VERSION ""

NS_ :

BS_:

BU_: VCU_LE CHUD_LE VKM_LE RCRM_LE VPM_LE EDI_LE V2V_LE TCP_LE CSM_LE UHP_Low_LE TouchPad_LE RSE_LE RSC_LE RSA_LE PDIM_LE OTIM_LE ICS_LE LVMPC_LE LVMNav_LE DVB_T_LE ONSTAR_LE HUD_LE IPC_LE RadioHead_LE CHM_LE Dummy_LE CGM_LE AMP_LE

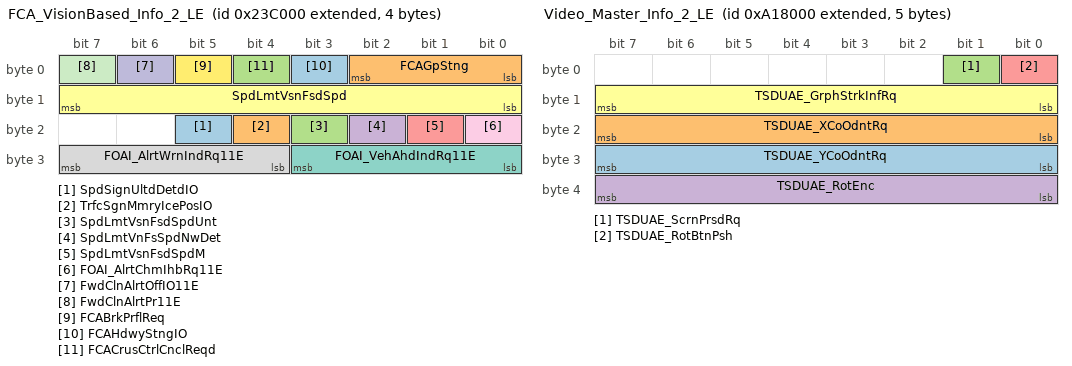
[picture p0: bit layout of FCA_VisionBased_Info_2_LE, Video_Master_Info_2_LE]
BO_ 2149826560 FCA_VisionBased_Info_2_LE: 4 CGM_LE
 SG_ SpdSignUltdDetdIO : 21|1@0+ (1,0) [0|1] ""  VCU_LE,IPC_LE
 SG_ TrfcSgnMmryIcePosIO : 20|1@0+ (1,0) [0|1] ""  VCU_LE,IPC_LE
 SG_ SpdLmtVsnFsdSpdUnt : 19|1@0+ (1,0) [0|1] ""  VCU_LE,IPC_LE,Dummy_LE
 SG_ SpdLmtVnFsSpdNwDet : 18|1@0+ (1,0) [0|1] ""  Dummy_LE
 SG_ SpdLmtVsnFsdSpdM : 17|1@0+ (1,0) [0|1] ""  VCU_LE,IPC_LE
 SG_ SpdLmtVsnFsdSpd : 15|8@0+ (1,0) [0|255] ""  CSM_LE,RadioHead_LE,VCU_LE,IPC_LE
 SG_ FOAI_VehAhdIndRq11E : 27|4@0+ (1,0) [0|15] ""  VCU_LE,IPC_LE,CHUD_LE,HUD_LE
 SG_ FOAI_AlrtWrnIndRq11E : 31|4@0+ (1,0) [0|15] ""  VCU_LE,IPC_LE,CHUD_LE,HUD_LE
 SG_ FOAI_AlrtChmIhbRq11E : 16|1@0+ (1,0) [0|1] ""  VCU_LE,IPC_LE,CHUD_LE,HUD_LE
 SG_ FwdClnAlrtOffIO11E : 6|1@0+ (1,0) [0|1] ""  VCU_LE,IPC_LE
 SG_ FwdClnAlrtPr11E : 7|1@0+ (1,0) [0|1] ""  VCU_LE,IPC_LE,CHUD_LE,HUD_LE
 SG_ FCABrkPrflReq : 5|1@0+ (1,0) [0|1] ""  Dummy_LE
 SG_ FCAHdwyStngIO : 3|1@0+ (1,0) [0|1] ""  VCU_LE,IPC_LE
 SG_ FCAGpStng : 2|3@0+ (1,0) [0|7] ""  VCU_LE,IPC_LE
 SG_ FCACrusCtrlCnclReqd : 4|1@0+ (1,0) [0|1] ""  Dummy_LE

BO_ 2149711872 ACC_YawRate_Information_LE: 8 CGM_LE
 SG_ SetSpdLmtRchd : 54|2@0+ (1,0) [0|3] ""  VCU_LE,IPC_LE
 SG_ FOAI_VehAhdIndRq : 63|4@0+ (1,0) [0|15] ""  CSM_LE,RadioHead_LE,VCU_LE,IPC_LE,CHUD_LE,HUD_LE
 SG_ FOAI_AlrtWrnIndRq : 59|4@0+ (1,0) [0|15] ""  CSM_LE,RadioHead_LE,VCU_LE,IPC_LE,CHUD_LE,HUD_LE
 SG_ FOAI_AlrtChmIhbRq : 48|1@0+ (1,0) [0|1] ""  CSM_LE,RadioHead_LE,VCU_LE,IPC_LE,CHUD_LE,HUD_LE
 SG_ FwdClnAlrtOffIO : 39|1@0+ (1,0) [0|1] ""  CSM_LE,RadioHead_LE,VCU_LE,IPC_LE
 SG_ FwdClnAlrtPr : 23|1@0+ (1,0) [0|1] ""  V2V_LE,CSM_LE,RadioHead_LE,VCU_LE,IPC_LE,CHUD_LE,HUD_LE
 SG_ VehDynYawRateV : 36|1@0+ (1,0) [0|1] ""  VPM_LE,CSM_LE,RadioHead_LE,VCU_LE,IPC_LE
 SG_ ACCHdwyStg : 22|3@0+ (1,0) [0|7] ""  CSM_LE,RadioHead_LE,VCU_LE,IPC_LE,CHUD_LE,HUD_LE
 SG_ ACCDrvrSeltdSpd : 3|12@0+ (0.0625,0) [0|255.9375] "km / h"  CSM_LE,RadioHead_LE,VCU_LE,IPC_LE,CHUD_LE,HUD_LE
 SG_ AdapCrsCntVDA : 4|1@0+ (1,0) [0|1] ""  V2V_LE,CSM_LE,RadioHead_LE,VCU_LE,IPC_LE,CHUD_LE,HUD_LE
 SG_ SpdLmtrSpdWrngEnbld : 37|1@0+ (1,0) [0|1] ""  CSM_LE,RadioHead_LE,VCU_LE,IPC_LE
 SG_ VehDynYawRate : 35|12@0- (0.0625,0) [-128|127.9375] "deg/sec"  VPM_LE,CSM_LE,RadioHead_LE,VCU_LE,IPC_LE
 SG_ CrsCntlDrSelSpdAct : 7|1@0+ (1,0) [0|1] ""  CSM_LE,RadioHead_LE,VCU_LE,IPC_LE
 SG_ ACCAct370 : 6|1@0+ (1,0) [0|1] ""  V2V_LE,CSM_LE,RadioHead_LE,VCU_LE,IPC_LE,CHUD_LE,HUD_LE
 SG_ SpdLmtrSpdWrngAct : 38|1@0+ (1,0) [0|1] ""  CSM_LE,RadioHead_LE,VCU_LE,IPC_LE
 SG_ CrsSpdLmtrDrvSelSpd : 19|12@0+ (0.0625,0) [0|255.9375] "km / h"  CSM_LE,RadioHead_LE,VCU_LE,IPC_LE,Dummy_LE
 SG_ AutoMdSpdLmtStat : 50|2@0+ (1,0) [0|3] ""  CSM_LE,VCU_LE,IPC_LE
 SG_ ACCAutoSetSpdStat : 52|2@0+ (1,0) [0|3] ""  CSM_LE,ONSTAR_LE,VCU_LE,IPC_LE

BO_ 2149629952 Lighting_Status_LE: 5 CGM_LE
 SG_ RtTrnLmpOn : 34|1@0+ (1,0) [0|1] ""  VPM_LE,Dummy_LE
 SG_ LftTrnLmpOn : 35|1@0+ (1,0) [0|1] ""  VPM_LE,Dummy_LE
 SG_ FrFogLmpsAct : 7|1@0+ (1,0) [0|1] ""  CSM_LE,VCU_LE,RadioHead_LE
 SG_ HiBmReqd : 20|1@0+ (1,0) [0|1] ""  V2V_LE,CSM_LE,VCU_LE,RadioHead_LE
 SG_ PrkLtRightOn : 22|1@0+ (1,0) [0|1] ""  CSM_LE,V2V_LE,VCU_LE,RadioHead_LE
 SG_ PrkLtLeftOn : 8|1@0+ (1,0) [0|1] ""  CSM_LE,V2V_LE,VCU_LE,RadioHead_LE
 SG_ TrnSwAct : 6|2@0+ (1,0) [0|3] ""  VPM_LE,CSM_LE,RadioHead_LE,VCU_LE,IPC_LE,CHUD_LE,HUD_LE
 SG_ PrkLtRightIO : 4|1@0+ (1,0) [0|1] ""  CSM_LE,IPC_LE,VCU_LE,RadioHead_LE,CHUD_LE,HUD_LE
 SG_ MainLghtSw : 31|2@0+ (1,0) [0|3] "N/A"  CSM_LE,VCU_LE,RadioHead_LE
 SG_ PrkLtLeftIO : 3|1@0+ (1,0) [0|1] ""  CSM_LE,IPC_LE,VCU_LE,RadioHead_LE,CHUD_LE,HUD_LE
 SG_ HazSwAtv : 2|1@0+ (1,0) [0|1] ""  V2V_LE,IPC_LE,CSM_LE,VCU_LE,RadioHead_LE,CHUD_LE,HUD_LE
 SG_ HiBmIO : 13|1@0+ (1,0) [0|1] ""  CSM_LE,RadioHead_LE,VCU_LE,IPC_LE
 SG_ FrFgLtIO : 9|1@0+ (1,0) [0|1] ""  V2V_LE,CSM_LE,RadioHead_LE,VCU_LE,IPC_LE
 SG_ AutoLtsInactIO : 10|1@0+ (1,0) [0|1] ""  CSM_LE,RadioHead_LE,VCU_LE,IPC_LE
 SG_ AutoLtsActIO : 11|1@0+ (1,0) [0|1] ""  CSM_LE,RadioHead_LE,VCU_LE,IPC_LE
 SG_ LftTrnLmpAtv : 29|2@0+ (1,0) [0|3] ""  VPM_LE,V2V_LE,CSM_LE,RadioHead_LE,VCU_LE,IPC_LE,CHUD_LE,HUD_LE
 SG_ RtTrnLmpAtv : 25|2@0+ (1,0) [0|3] ""  VPM_LE,V2V_LE,CSM_LE,RadioHead_LE,VCU_LE,IPC_LE,CHUD_LE,HUD_LE
 SG_ RevLmpAtv : 17|1@0+ (1,0) [0|1] "N/A"  V2V_LE,CSM_LE,VCU_LE,RadioHead_LE
 SG_ HdlmpBmSelectStat : 33|2@0+ (1,0) [0|3] ""  V2V_LE,CSM_LE,VCU_LE,RadioHead_LE
 SG_ SrvlnceMdAct : 23|1@0+ (1,0) [0|1] ""  CSM_LE,VCU_LE,RadioHead_LE
 SG_ RrFgLtIO : 12|1@0+ (1,0) [0|1] ""  CSM_LE,RadioHead_LE,VCU_LE,IPC_LE
 SG_ PrkLtIO : 14|1@0+ (1,0) [0|1] ""  CSM_LE,VPM_LE,RadioHead_LE,VCU_LE,IPC_LE
 SG_ OtsdAmbtLtLvlStatV : 0|1@0+ (1,0) [0|1] ""  CSM_LE,VPM_LE,VCU_LE,RadioHead_LE
 SG_ OtsdAmbtLtLvlStat : 27|2@0+ (1,0) [0|3] ""  CSM_LE,VPM_LE,VCU_LE,RadioHead_LE
 SG_ RrFogLmpsAct : 19|1@0+ (1,0) [0|1] ""  CSM_LE,VCU_LE,RadioHead_LE
 SG_ PrkngLtsAct : 18|1@0+ (1,0) [0|1] ""  V2V_LE,VPM_LE,CSM_LE,VCU_LE,RadioHead_LE
 SG_ BrkLtsAtv : 15|1@0+ (1,0) [0|1] ""  CSM_LE,VCU_LE,RadioHead_LE
 SG_ AutoBmSlctAllwd : 21|1@0+ (1,0) [0|1] ""  CSM_LE,VCU_LE,RadioHead_LE
 SG_ FlToPsSwAtv : 16|1@0+ (1,0) [0|1] ""  CSM_LE,VCU_LE,RadioHead_LE
 SG_ DRLAct : 1|1@0+ (1,0) [0|1] ""  CSM_LE,V2V_LE,RadioHead_LE,VCU_LE,IPC_LE

BO_ 2151047168 HUD_Status_LE: 1 HUD_LE
 SG_ HdUpDspAnmtStat : 3|3@0+ (1,0) [0|7] ""  CGM_LE,RadioHead_LE,VCU_LE,IPC_LE
 SG_ HUDActv : 0|1@0+ (1,0) [0|1] ""  CSM_LE,CGM_LE,VCU_LE,RadioHead_LE

BO_ 1618 USDT_Resp_From_DVBT_LE: 8 DVB_T_LE
 SG_ DgnInf : 7|64@0+ (1,0) [0|1.84467440737096E+019] ""  CSM_LE,CGM_LE,TCP_LE,ONSTAR_LE

BO_ 1586 VNMF_LE_632_DVB_T: 8 DVB_T_LE
 SG_ VectraSpcNWMgtD : 7|64@0+ (1,0) [0|1.84467440737096E+019] ""  RCRM_LE,V2V_LE,TCP_LE,UHP_Low_LE,LVMNav_LE,ONSTAR_LE,VKM_LE,RSC_LE,RSE_LE,RSA_LE,PDIM_LE,OTIM_LE,CHUD_LE,LVMPC_LE,IPC_LE,ICS_LE,VPM_LE,HUD_LE,VCU_LE,CSM_LE,RadioHead_LE,CHM_LE,AMP_LE,CGM_LE

BO_ 1362 UUDT_Resp_From_DVBT_LE: 8 DVB_T_LE
 SG_ DgnInf_LS552 : 7|64@0+ (1,0) [0|1.84467440737096E+019] ""  CSM_LE,CGM_LE,TCP_LE,ONSTAR_LE

BO_ 2153947136 Remote_Reflash_Stat_LE: 1 CGM_LE
 SG_ RmtRflshMdAct : 7|1@0+ (1,0) [0|1] ""  VCU_LE,CSM_LE,RadioHead_LE

BO_ 2158067712 Video_Master_Info_2_LE: 5 RadioHead_LE
 SG_ TSDUAE_YCoOdntRq : 31|8@0+ (1,0) [0|255] ""  EDI_LE,DVB_T_LE,CGM_LE
 SG_ TSDUAE_XCoOdntRq : 23|8@0+ (1,0) [0|255] ""  EDI_LE,DVB_T_LE,CGM_LE
 SG_ TSDUAE_ScrnPrsdRq : 1|1@0+ (1,0) [0|1] ""  EDI_LE,DVB_T_LE,CGM_LE
 SG_ TSDUAE_RotEnc : 39|8@0- (1,0) [-128|127] "Detentions"  EDI_LE,DVB_T_LE,CGM_LE
 SG_ TSDUAE_RotBtnPsh : 0|1@0+ (1,0) [0|1] ""  EDI_LE,DVB_T_LE,CGM_LE
 SG_ TSDUAE_GrphStrkInfRq : 15|8@0+ (1,0) [0|255] ""  EDI_LE,DVB_T_LE,CGM_LE

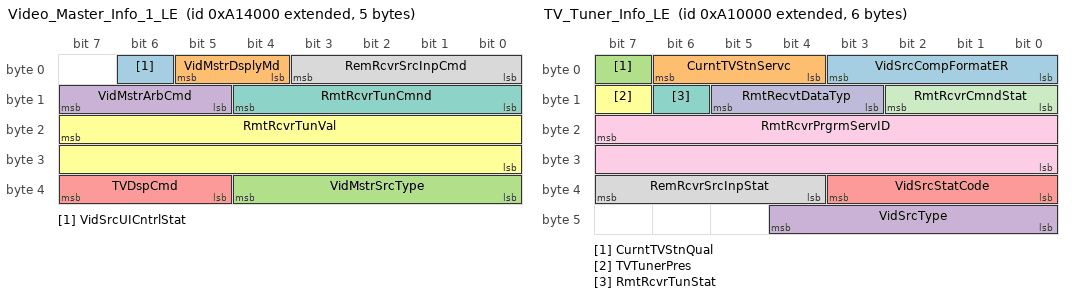
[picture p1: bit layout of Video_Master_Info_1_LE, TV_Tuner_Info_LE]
BO_ 2158051328 Video_Master_Info_1_LE: 5 RadioHead_LE
 SG_ VidSrcUICntrlStat : 6|1@0+ (1,0) [0|1] ""  EDI_LE,Dummy_LE,CGM_LE
 SG_ VidMstrDsplyMd : 5|2@0+ (1,0) [0|3] ""  EDI_LE,CGM_LE,Dummy_LE
 SG_ VidMstrSrcType : 36|5@0+ (1,0) [0|31] ""  EDI_LE,CGM_LE,DVB_T_LE
 SG_ VidMstrArbCmd : 15|3@0+ (1,0) [0|7] ""  CGM_LE,DVB_T_LE
 SG_ TVDspCmd : 39|3@0+ (1,0) [0|7] ""  CGM_LE,DVB_T_LE
 SG_ RmtRcvrTunVal : 23|16@0- (1,0) [-32768|32767] ""  CGM_LE,DVB_T_LE
 SG_ RmtRcvrTunCmnd : 12|5@0+ (1,0) [0|31] ""  CGM_LE,DVB_T_LE
 SG_ RemRcvrSrcInpCmd : 3|4@0+ (1,0) [0|15] ""  CGM_LE,DVB_T_LE

BO_ 2158034944 TV_Tuner_Info_LE: 6 DVB_T_LE
 SG_ VidSrcCompFormatER : 3|4@0+ (1,0) [0|15] ""  VCU_LE,RadioHead_LE
 SG_ CurntTVStnServc : 6|3@0+ (1,0) [0|7] ""  VCU_LE,RadioHead_LE
 SG_ CurntTVStnQual : 7|1@0+ (1,0) [0|1] ""  VCU_LE,RadioHead_LE
 SG_ VidSrcType : 44|5@0+ (1,0) [0|31] ""  VCU_LE,RadioHead_LE
 SG_ VidSrcStatCode : 35|4@0+ (1,0) [0|15] ""  VCU_LE,RadioHead_LE
 SG_ TVTunerPres : 15|1@0+ (1,0) [0|1] ""  VCU_LE,RadioHead_LE
 SG_ RmtRcvrTunStat : 14|1@0+ (1,0) [0|1] ""  VCU_LE,RadioHead_LE
 SG_ RemRcvrSrcInpStat : 39|4@0+ (1,0) [0|15] ""  VCU_LE,RadioHead_LE
 SG_ RmtRcvrPrgrmServID : 23|16@0+ (1,0) [0|65535] ""  VCU_LE,RadioHead_LE
 SG_ RmtRecvtDataTyp : 13|3@0+ (1,0) [0|7] ""  VCU_LE,RadioHead_LE
 SG_ RmtRcvrCmndStat : 10|3@0+ (1,0) [0|7] ""  VCU_LE,RadioHead_LE

BO_ 2158018560 TV_Station_Name_LE: 8 DVB_T_LE
 SG_ TVStatNmeChar1_8 : 7|64@0+ (1,0) [0|0] ""  VCU_LE,RadioHead_LE

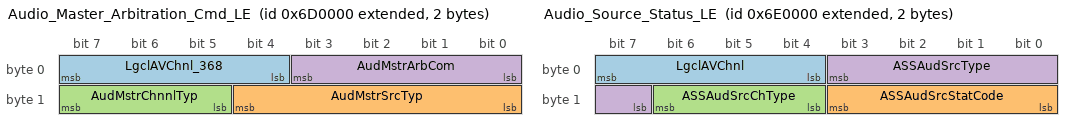
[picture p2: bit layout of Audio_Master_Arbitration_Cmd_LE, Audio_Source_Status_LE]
BO_ 2154627072 Audio_Master_Arbitration_Cmd_LE: 2 RadioHead_LE
 SG_ LgclAVChnl_368 : 7|4@0+ (1,0) [0|15] ""  TCP_LE,UHP_Low_LE,DVB_T_LE,ONSTAR_LE
 SG_ AudMstrSrcTyp : 12|5@0+ (1,0) [0|31] ""  LVMNav_LE,TCP_LE,UHP_Low_LE,DVB_T_LE,ONSTAR_LE
 SG_ AudMstrChnnlTyp : 15|3@0+ (1,0) [0|7] ""  LVMNav_LE,TCP_LE,UHP_Low_LE,DVB_T_LE,ONSTAR_LE
 SG_ AudMstrArbCom : 3|4@0+ (1,0) [0|15] ""  LVMNav_LE,TCP_LE,UHP_Low_LE,DVB_T_LE,ONSTAR_LE

BO_ 2154692608 Audio_Source_Status_LE: 2 ONSTAR_LE
 SG_ LgclAVChnl : 7|4@0+ (1,0) [0|15] ""  V2V_LE,CSM_LE,CGM_LE,LVMNav_LE,VCU_LE,RadioHead_LE
 SG_ ASSAudSrcStatCode : 11|4@0+ (1,0) [0|15] ""  CSM_LE,CGM_LE,OTIM_LE,VCU_LE,RadioHead_LE
 SG_ ASSAudSrcChType : 14|3@0+ (1,0) [0|7] ""  CSM_LE,CGM_LE,OTIM_LE,VCU_LE,RadioHead_LE
 SG_ ASSAudSrcType : 3|5@0+ (1,0) [0|31] ""  CSM_LE,CGM_LE,OTIM_LE,VCU_LE,RadioHead_LE

BO_ 1604 USDT_Resp_From_RadioHead_LE: 8 CHM_LE
 SG_ DgnInf : 7|64@0+ (1,0) [0|1.84467440737096E+019] ""  CGM_LE,TCP_LE,ONSTAR_LE

BO_ 1348 UUDT_Resp_From_RadioHead_LE: 8 CHM_LE
 SG_ DgnInf_LS544 : 7|64@0+ (1,0) [0|1.84467440737096E+019] ""  CGM_LE,TCP_LE,ONSTAR_LE

BO_ 1572 VNMF_LE_624_RadioHead_CHM: 8 CHM_LE
 SG_ VectraSpcNWMgtD : 7|64@0+ (1,0) [0|1.84467440737096E+019] ""  RCRM_LE,V2V_LE,TCP_LE,UHP_Low_LE,LVMNav_LE,ONSTAR_LE,VKM_LE,RSC_LE,RSE_LE,RSA_LE,PDIM_LE,OTIM_LE,CHUD_LE,LVMPC_LE,IPC_LE,ICS_LE,VPM_LE,HUD_LE,TouchPad_LE,DVB_T_LE,AMP_LE,CGM_LE

BO_ 1620 USDT_Resp_From_AMP_LE: 8 AMP_LE
 SG_ DgnInf : 7|64@0+ (1,0) [0|1.84467440737096E+019] ""  CSM_LE,CGM_LE,TCP_LE,ONSTAR_LE

BO_ 1588 VNMF_LE_634_AMP: 8 AMP_LE
 SG_ VectraSpcNWMgtD : 7|64@0+ (1,0) [0|1.84467440737096E+019] ""  RCRM_LE,V2V_LE,TCP_LE,UHP_Low_LE,LVMNav_LE,ONSTAR_LE,VKM_LE,RSC_LE,RSE_LE,RSA_LE,PDIM_LE,OTIM_LE,CHUD_LE,LVMPC_LE,IPC_LE,ICS_LE,VPM_LE,HUD_LE,TouchPad_LE,DVB_T_LE,VCU_LE,CSM_LE,RadioHead_LE,CHM_LE,CGM_LE

BO_ 1364 UUDT_Resp_From_AMP_LE: 8 AMP_LE
 SG_ DgnInf_LS554 : 7|64@0+ (1,0) [0|1.84467440737096E+019] ""  CSM_LE,CGM_LE,TCP_LE,ONSTAR_LE

BO_ 2153775104 DTC_Triggered_LE: 7 AMP_LE
 SG_ DTCI_DTCFaultType : 55|8@0+ (1,0) [0|255] ""  VCU_LE,RadioHead_LE,TCP_LE,CSM_LE,ONSTAR_LE
 SG_ DTCI_CodeSupported : 40|1@0+ (1,0) [0|1] ""  VCU_LE,RadioHead_LE,TCP_LE,CSM_LE,ONSTAR_LE
 SG_ DTCI_CurrentStatus : 41|1@0+ (1,0) [0|1] ""  VCU_LE,RadioHead_LE,TCP_LE,CSM_LE,ONSTAR_LE
 SG_ DTCI_TstNPsdCdClrdSt : 42|1@0+ (1,0) [0|1] ""  VCU_LE,RadioHead_LE,TCP_LE,CSM_LE,ONSTAR_LE
 SG_ DTCI_TstFldCdClrdStat : 43|1@0+ (1,0) [0|1] ""  VCU_LE,RadioHead_LE,TCP_LE,CSM_LE,ONSTAR_LE
 SG_ DTCI_HistStat : 44|1@0+ (1,0) [0|1] ""  VCU_LE,RadioHead_LE,TCP_LE,CSM_LE,ONSTAR_LE
 SG_ DTCI_TstNPsdPwrUpSt : 45|1@0+ (1,0) [0|1] ""  VCU_LE,RadioHead_LE,TCP_LE,CSM_LE,ONSTAR_LE
 SG_ DTCI_TstFldPwrUpSt : 46|1@0+ (1,0) [0|1] ""  VCU_LE,RadioHead_LE,TCP_LE,CSM_LE,ONSTAR_LE
 SG_ DTCI_WrnIndRqdSt : 47|1@0+ (1,0) [0|1] ""  VCU_LE,RadioHead_LE,TCP_LE,CSM_LE,ONSTAR_LE
 SG_ DTCI_DTCFailType : 39|8@0+ (1,0) [0|255] ""  VCU_LE,RadioHead_LE,TCP_LE,CSM_LE,ONSTAR_LE
 SG_ DTCI_DTCNumber : 23|16@0+ (1,0) [0|65535] ""  VCU_LE,RadioHead_LE,TCP_LE,CSM_LE,ONSTAR_LE
 SG_ DTCI_DTCSource : 15|8@0+ (1,0) [0|255] ""  VCU_LE,RadioHead_LE,TCP_LE,CSM_LE,ONSTAR_LE
 SG_ DTCI_DTCTriggered : 0|1@0+ (1,0) [0|1] ""  VCU_LE,RadioHead_LE,TCP_LE,CSM_LE,ONSTAR_LE
 SG_ DTCIUnused7 : 7|1@0+ (1,0) [0|1] ""  VCU_LE,RadioHead_LE,TCP_LE,CSM_LE,ONSTAR_LE
 SG_ DTCIUnused6 : 6|1@0+ (1,0) [0|1] ""  VCU_LE,RadioHead_LE,TCP_LE,CSM_LE,ONSTAR_LE
 SG_ DTCIUnused5 : 5|1@0+ (1,0) [0|1] ""  VCU_LE,RadioHead_LE,TCP_LE,CSM_LE,ONSTAR_LE
 SG_ DTCIUnused4 : 4|1@0+ (1,0) [0|1] ""  VCU_LE,RadioHead_LE,TCP_LE,CSM_LE,ONSTAR_LE
 SG_ DTCIUnused3 : 3|1@0+ (1,0) [0|1] ""  VCU_LE,RadioHead_LE,TCP_LE,CSM_LE,ONSTAR_LE
 SG_ DTCIUnused2 : 2|1@0+ (1,0) [0|1] ""  VCU_LE,RadioHead_LE,TCP_LE,CSM_LE,ONSTAR_LE
 SG_ DTCIUnused1 : 1|1@0+ (1,0) [0|1] ""  VCU_LE,RadioHead_LE,TCP_LE,CSM_LE,ONSTAR_LE

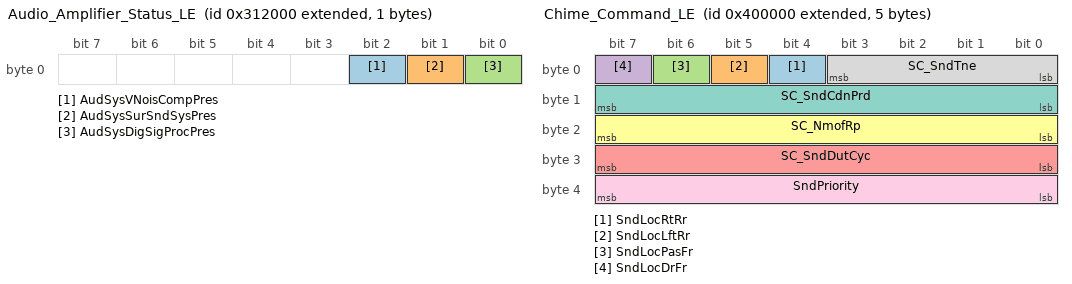
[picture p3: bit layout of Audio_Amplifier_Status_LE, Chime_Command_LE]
BO_ 2150703104 Audio_Amplifier_Status_LE: 1 AMP_LE
 SG_ AudSysVNoisCompPres : 2|1@0+ (1,0) [0|1] ""  VCU_LE,RadioHead_LE
 SG_ AudSysSurSndSysPres : 1|1@0+ (1,0) [0|1] ""  VCU_LE,RadioHead_LE
 SG_ AudSysDigSigProcPres : 0|1@0+ (1,0) [0|1] ""  VCU_LE,RadioHead_LE

BO_ 2151718912 Chime_Active_LE: 1 AMP_LE
 SG_ ChmVolSt : 2|2@0+ (1,0) [0|3] ""  V2V_LE,CSM_LE,CGM_LE,VCU_LE,RadioHead_LE
 SG_ ChmAct : 0|1@0+ (1,0) [0|1] ""  VPM_LE,V2V_LE,TCP_LE,CSM_LE,CGM_LE,ONSTAR_LE,RadioHead_LE,CHUD_LE,HUD_LE,VCU_LE,IPC_LE

BO_ 2155020288 Language_Selection_LE: 1 RadioHead_LE
 SG_ ChVolRq2 : 7|2@0+ (1,0) [0|3] ""  VCU_LE,CSM_LE,IPC_LE,RadioHead_LE,CHM_LE,AMP_LE
 SG_ LngSelExt : 5|6@0+ (1,0) [0|63] ""  RSE_LE,TCP_LE,VPM_LE,RSC_LE,LVMNav_LE,PDIM_LE,OTIM_LE,LVMPC_LE,UHP_Low_LE,ONSTAR_LE,RSA_LE,CHUD_LE,HUD_LE,VCU_LE,IPC_LE

BO_ 2151677952 Chime_Command_LE: 5 CGM_LE
 SG_ SndLocRtRr : 4|1@0+ (1,0) [0|1] ""  VCU_LE,CSM_LE,IPC_LE,RadioHead_LE,CHM_LE,AMP_LE
 SG_ SndLocLftRr : 5|1@0+ (1,0) [0|1] ""  VCU_LE,CSM_LE,IPC_LE,RadioHead_LE,CHM_LE,AMP_LE
 SG_ SndLocPasFr : 6|1@0+ (1,0) [0|1] ""  VCU_LE,CSM_LE,IPC_LE,RadioHead_LE,CHM_LE,AMP_LE
 SG_ SndLocDrFr : 7|1@0+ (1,0) [0|1] ""  VCU_LE,CSM_LE,IPC_LE,RadioHead_LE,CHM_LE,AMP_LE
 SG_ SC_SndDutCyc : 31|8@0+ (0.392157,0) [0|100.000035] "%"  VCU_LE,CSM_LE,IPC_LE,RadioHead_LE,CHM_LE,AMP_LE
 SG_ SC_NmofRp : 23|8@0+ (1,0) [0|255] "reps"  VCU_LE,CSM_LE,IPC_LE,RadioHead_LE,CHM_LE,AMP_LE
 SG_ SC_SndCdnPrd : 15|8@0+ (10,0) [0|2550] "ms"  VCU_LE,CSM_LE,IPC_LE,RadioHead_LE,CHM_LE,AMP_LE
 SG_ SC_SndTne : 3|4@0+ (1,0) [0|15] ""  VCU_LE,CSM_LE,IPC_LE,RadioHead_LE,CHM_LE,AMP_LE
 SG_ SndPriority : 39|8@0+ (1,0) [0|255] ""  VCU_LE,CSM_LE,IPC_LE,RadioHead_LE,CHM_LE,AMP_LE

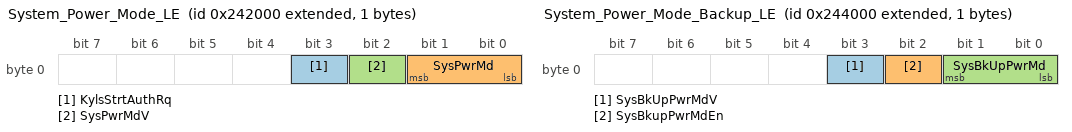
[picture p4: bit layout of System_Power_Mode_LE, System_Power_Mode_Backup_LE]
BO_ 2149851136 System_Power_Mode_LE: 1 CGM_LE
 SG_ KylsStrtAuthRq : 3|1@0+ (1,0) [0|1] ""  Dummy_LE
 SG_ SysPwrMd : 1|2@0+ (1,0) [0|3] ""  EDI_LE,IPC_LE,VCU_LE,CHUD_LE,VKM_LE,RCRM_LE,VPM_LE,V2V_LE,TCP_LE,CSM_LE,UHP_Low_LE,RSC_LE,RSA_LE,PDIM_LE,OTIM_LE,ICS_LE,LVMPC_LE,LVMNav_LE,DVB_T_LE,ONSTAR_LE,HUD_LE,RadioHead_LE,CHM_LE,AMP_LE
 SG_ SysPwrMdV : 2|1@0+ (1,0) [0|1] ""  EDI_LE,VCU_LE,CHUD_LE,VKM_LE,RCRM_LE,VPM_LE,V2V_LE,TCP_LE,CSM_LE,UHP_Low_LE,RSC_LE,RSA_LE,PDIM_LE,OTIM_LE,ICS_LE,LVMPC_LE,LVMNav_LE,DVB_T_LE,ONSTAR_LE,HUD_LE,RadioHead_LE,CHM_LE,AMP_LE

BO_ 2149859328 System_Power_Mode_Backup_LE: 1 IPC_LE
 SG_ SysBkUpPwrMdV : 3|1@0+ (1,0) [0|1] ""  CGM_LE,VCU_LE,CHUD_LE,VKM_LE,RCRM_LE,VPM_LE,V2V_LE,TCP_LE,CSM_LE,UHP_Low_LE,RSC_LE,RSA_LE,PDIM_LE,OTIM_LE,ICS_LE,LVMPC_LE,LVMNav_LE,DVB_T_LE,ONSTAR_LE,HUD_LE,RadioHead_LE,CHM_LE,AMP_LE
 SG_ SysBkupPwrMdEn : 2|1@0+ (1,0) [0|1] ""  CGM_LE,VCU_LE,CHUD_LE,VKM_LE,RCRM_LE,VPM_LE,V2V_LE,TCP_LE,CSM_LE,UHP_Low_LE,RSC_LE,RSA_LE,PDIM_LE,OTIM_LE,ICS_LE,LVMPC_LE,LVMNav_LE,DVB_T_LE,ONSTAR_LE,HUD_LE,RadioHead_LE,CHM_LE,AMP_LE
 SG_ SysBkUpPwrMd : 1|2@0+ (1,0) [0|3] ""  CGM_LE,VCU_LE,CHUD_LE,VKM_LE,RCRM_LE,VPM_LE,V2V_LE,TCP_LE,CSM_LE,UHP_Low_LE,RSC_LE,RSA_LE,PDIM_LE,OTIM_LE,ICS_LE,LVMPC_LE,LVMNav_LE,DVB_T_LE,ONSTAR_LE,HUD_LE,RadioHead_LE,CHM_LE,AMP_LE

BO_ 2155167744 Power_Mode_Info_LE: 3 CGM_LE
 SG_ ClsEngCmprtmtToStrtVehIO : 23|1@0+ (1,0) [0|1] ""  VCU_LE,IPC_LE
 SG_ PrsCltchPrsStrtAgnIO : 22|1@0+ (1,0) [0|1] ""  VCU_LE,IPC_LE
 SG_ PrsStrtAgnIO : 21|1@0+ (1,0) [0|1] ""  VCU_LE,IPC_LE
 SG_ AutoShtdwnDsblIO : 11|1@0+ (1,0) [0|1] ""  VCU_LE,IPC_LE
 SG_ ShftToNtrlIO : 1|1@0+ (1,0) [0|1] ""  VCU_LE,IPC_LE
 SG_ AppPrkBrkIO : 12|1@0+ (1,0) [0|1] ""  VCU_LE,IPC_LE
 SG_ NRmtDtctdRstrtAllwd : 20|1@0+ (1,0) [0|1] ""  VCU_LE,IPC_LE,Dummy_LE
 SG_ NRmtDtdPsCluRstIO : 13|1@0+ (1,0) [0|1] ""  VCU_LE,IPC_LE,Dummy_LE
 SG_ SecPwrMdPshBtnAtv : 3|1@0+ (1,0) [0|1] ""  VKM_LE,Dummy_LE
 SG_ TSLgMdPwrCtOWAtv : 19|1@0+ (1,0) [0|1] ""  Dummy_LE
 SG_ PrsBtnAgnTTrnEngOffIO : 18|1@0+ (1,0) [0|1] ""  VCU_LE,IPC_LE,Dummy_LE
 SG_ NRmtDtdPsBrkRstIO : 17|1@0+ (1,0) [0|1] ""  VCU_LE,IPC_LE,Dummy_LE
 SG_ NoReDetInOn : 16|1@0+ (1,0) [0|1] ""  VCU_LE,IPC_LE,Dummy_LE
 SG_ ApplyCltPdlIO : 15|1@0+ (1,0) [0|1] ""  CSM_LE,VCU_LE,IPC_LE,Dummy_LE
 SG_ VehMovState : 10|3@0+ (1,0) [0|7] ""  RCRM_LE,VPM_LE,ICS_LE,VCU_LE,CSM_LE,RadioHead_LE,LVMNav_LE,TCP_LE,ONSTAR_LE,Dummy_LE
 SG_ TrStLgMdAtv : 7|1@0+ (1,0) [0|1] ""  VCU_LE,CHUD_LE,VKM_LE,RCRM_LE,VPM_LE,V2V_LE,TCP_LE,CSM_LE,UHP_Low_LE,TouchPad_LE,RSC_LE,RSA_LE,PDIM_LE,OTIM_LE,ICS_LE,LVMPC_LE,LVMNav_LE,DVB_T_LE,HUD_LE,IPC_LE,RadioHead_LE,CHM_LE,AMP_LE,ONSTAR_LE
 SG_ TransModInactIO : 5|1@0+ (1,0) [0|1] ""  VCU_LE,IPC_LE,Dummy_LE
 SG_ TransModActIO : 4|1@0+ (1,0) [0|1] ""  VCU_LE,IPC_LE,Dummy_LE
 SG_ ApplyBrkPdlIO : 14|1@0+ (1,0) [0|1] ""  CSM_LE,VCU_LE,IPC_LE,Dummy_LE
 SG_ Ky_IdDevPr : 2|1@0+ (1,0) [0|1] ""  ONSTAR_LE,TCP_LE,CSM_LE,RadioHead_LE,CHUD_LE,HUD_LE,VCU_LE,IPC_LE
 SG_ KylsStrtUseTxPckIO : 6|1@0+ (1,0) [0|1] ""  VCU_LE,IPC_LE,Dummy_LE
 SG_ ShftPrkIO : 0|1@0+ (1,0) [0|1] ""  VCU_LE,IPC_LE,Dummy_LE

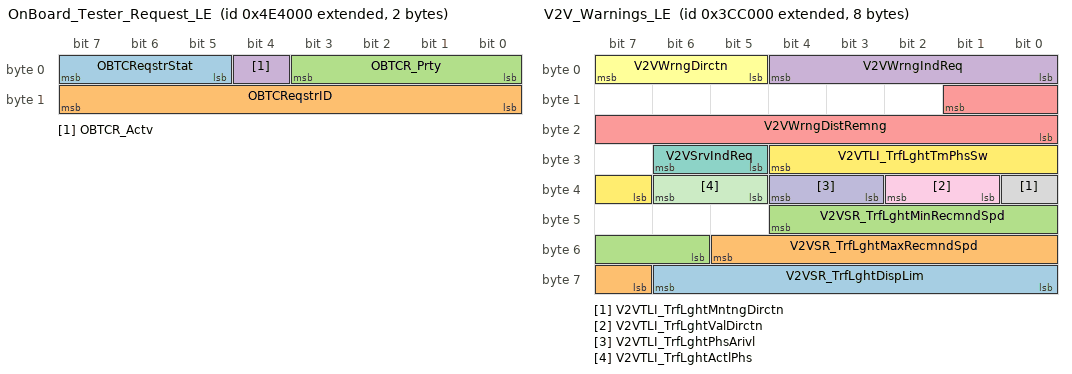
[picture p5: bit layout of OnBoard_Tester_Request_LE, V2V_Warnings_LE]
BO_ 2152611840 OnBoard_Tester_Request_LE: 2 CSM_LE
 SG_ OBTCReqstrStat : 7|3@0+ (1,0) [0|7] ""  TCP_LE
 SG_ OBTCReqstrID : 15|8@0+ (1,0) [0|255] ""  TCP_LE
 SG_ OBTCR_Prty : 3|4@0+ (1,0) [0|15] ""  TCP_LE
 SG_ OBTCR_Actv : 4|1@0+ (1,0) [0|1] ""  TCP_LE

BO_ 2156945408 SSID_AMM_1_LE: 8 ONSTAR_LE
 SG_ WiFiSSIDDgts1to8_Mp : 7|64@0+ (1,0) [0|0] ""  CGM_LE

BO_ 2151292928 V2V_Customization_Menu_LE: 5 V2V_LE
 SG_ TrfRdsdInfCsStAvail : 0|1@0+ (1,0) [0|1] ""  VCU_LE,CSM_LE,RadioHead_LE
 SG_ TrfRdsdInfCsCrStVal : 10|3@0+ (1,0) [0|7] ""  VCU_LE,CSM_LE,RadioHead_LE
 SG_ TRICA_Resrv5Avail : 32|1@0+ (1,0) [0|1] ""  VCU_LE,CSM_LE,RadioHead_LE
 SG_ TRICA_Resrv4Avail : 33|1@0+ (1,0) [0|1] ""  VCU_LE,CSM_LE,RadioHead_LE
 SG_ TRICA_Resrv3Avail : 34|1@0+ (1,0) [0|1] ""  VCU_LE,CSM_LE,RadioHead_LE
 SG_ TRICA_Resrv2Avail : 35|1@0+ (1,0) [0|1] ""  VCU_LE,CSM_LE,RadioHead_LE
 SG_ TRICA_Resrv1Avail : 36|1@0+ (1,0) [0|1] ""  VCU_LE,CSM_LE,RadioHead_LE
 SG_ TRICA_OnAvail : 37|1@0+ (1,0) [0|1] ""  VCU_LE,CSM_LE,RadioHead_LE
 SG_ TRICA_OfAvail : 38|1@0+ (1,0) [0|1] ""  VCU_LE,CSM_LE,RadioHead_LE
 SG_ IntrStopAlrtCsSetAvl : 2|1@0+ (1,0) [0|1] ""  VCU_LE,CSM_LE,RadioHead_LE
 SG_ IntrStAlrtCsCrSetVal : 5|3@0+ (1,0) [0|7] ""  VCU_LE,CSM_LE,RadioHead_LE
 SG_ ISACA_Resrv4Avail : 16|1@0+ (1,0) [0|1] ""  VCU_LE,CSM_LE,RadioHead_LE
 SG_ ISACA_Resrv3Avail : 17|1@0+ (1,0) [0|1] ""  VCU_LE,CSM_LE,RadioHead_LE
 SG_ ISACA_Resrv2Avail : 18|1@0+ (1,0) [0|1] ""  VCU_LE,CSM_LE,RadioHead_LE
 SG_ ISACA_Resrv1Avail : 19|1@0+ (1,0) [0|1] ""  VCU_LE,CSM_LE,RadioHead_LE
 SG_ ISACA_AlrtBrkAvail : 20|1@0+ (1,0) [0|1] ""  VCU_LE,CSM_LE,RadioHead_LE
 SG_ ISACA_AlrtAvail : 21|1@0+ (1,0) [0|1] ""  VCU_LE,CSM_LE,RadioHead_LE
 SG_ ISACA_OfAvail : 22|1@0+ (1,0) [0|1] ""  VCU_LE,CSM_LE,RadioHead_LE
 SG_ CntdVehBrkAltCsStAvl : 1|1@0+ (1,0) [0|1] ""  VCU_LE,CSM_LE,RadioHead_LE
 SG_ CntdVehBrAltCsCrStVal : 13|3@0+ (1,0) [0|7] ""  VCU_LE,CSM_LE,RadioHead_LE
 SG_ CVBACA_Resrv5Avail : 24|1@0+ (1,0) [0|1] ""  VCU_LE,CSM_LE,RadioHead_LE
 SG_ CVBACA_Resrv4Avail : 25|1@0+ (1,0) [0|1] ""  VCU_LE,CSM_LE,RadioHead_LE
 SG_ CVBACA_Resrv3Avail : 26|1@0+ (1,0) [0|1] ""  VCU_LE,CSM_LE,RadioHead_LE
 SG_ CVBACA_Resrv2Avail : 27|1@0+ (1,0) [0|1] ""  VCU_LE,CSM_LE,RadioHead_LE
 SG_ CVBACA_Resrv1Avail : 28|1@0+ (1,0) [0|1] ""  VCU_LE,CSM_LE,RadioHead_LE
 SG_ CVBACA_OnAvail : 29|1@0+ (1,0) [0|1] ""  VCU_LE,CSM_LE,RadioHead_LE
 SG_ CVBACA_OfAvail : 30|1@0+ (1,0) [0|1] ""  VCU_LE,CSM_LE,RadioHead_LE

BO_ 2151464960 V2V_Warnings_LE: 8 V2V_LE
 SG_ V2VSR_TrfLghtDispLim : 62|7@0+ (1,0) [0|127] "km/h"  VCU_LE,IPC_LE
 SG_ V2VSR_TrfLghtMaxRecmndSpd : 53|7@0+ (1,0) [0|127] "km/h"  VCU_LE,IPC_LE
 SG_ V2VSR_TrfLghtMinRecmndSpd : 44|7@0+ (1,0) [0|127] "km/h"  VCU_LE,IPC_LE
 SG_ V2VWrngIndReq : 4|5@0+ (1,0) [0|31] ""  VCU_LE,IPC_LE
 SG_ V2VWrngDistRemng : 9|10@0+ (1,0) [0|1023] ""  VCU_LE,IPC_LE
 SG_ V2VWrngDirctn : 7|3@0+ (1,0) [0|7] ""  VCU_LE,IPC_LE
 SG_ V2VSrvIndReq : 30|2@0+ (1,0) [0|3] ""  VCU_LE,IPC_LE
 SG_ V2VTLI_TrfLghtMntngDirctn : 32|1@0+ (1,0) [0|1] ""  VCU_LE,IPC_LE
 SG_ V2VTLI_TrfLghtValDirctn : 34|2@0+ (1,0) [0|3] ""  VCU_LE,IPC_LE
 SG_ V2VTLI_TrfLghtPhsArivl : 36|2@0+ (1,0) [0|3] ""  VCU_LE,IPC_LE
 SG_ V2VTLI_TrfLghtActlPhs : 38|2@0+ (1,0) [0|3] ""  VCU_LE,IPC_LE
 SG_ V2VTLI_TrfLghtTmPhsSw : 28|6@0+ (1,0) [0|63] ""  VCU_LE,IPC_LE

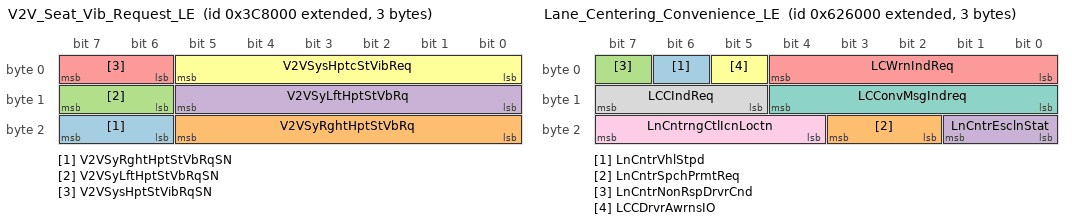
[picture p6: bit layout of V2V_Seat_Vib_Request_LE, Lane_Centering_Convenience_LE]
BO_ 2151448576 V2V_Seat_Vib_Request_LE: 3 V2V_LE
 SG_ V2VSyRghtHptStVbRqSN : 23|2@0+ (1,0) [0|3] ""  CGM_LE
 SG_ V2VSyRghtHptStVbRq : 21|6@0+ (1,0) [0|63] ""  CGM_LE
 SG_ V2VSyLftHptStVbRqSN : 15|2@0+ (1,0) [0|3] ""  CGM_LE
 SG_ V2VSyLftHptStVbRq : 13|6@0+ (1,0) [0|63] ""  CGM_LE
 SG_ V2VSysHptStVibRqSN : 7|2@0+ (1,0) [0|3] ""  CGM_LE
 SG_ V2VSysHptcStVibReq : 5|6@0+ (1,0) [0|63] ""  CGM_LE

BO_ 2153930752 Lane_Centering_Convenience_LE: 3 CGM_LE
 SG_ LnCntrVhlStpd : 6|1@0+ (1,0) [0|1] ""  TCP_LE,ONSTAR_LE
 SG_ LnCntrSpchPrmtReq : 19|2@0+ (1,0) [0|3] ""  CSM_LE,TCP_LE,ONSTAR_LE
 SG_ LnCntrNonRspDrvrCnd : 7|1@0+ (1,0) [0|1] ""  TCP_LE,ONSTAR_LE
 SG_ LnCntrEsclnStat : 17|2@0+ (1,0) [0|3] ""  TCP_LE,ONSTAR_LE
 SG_ LCWrnIndReq : 4|5@0+ (1,0) [0|31] ""  VCU_LE,IPC_LE
 SG_ LCCDrvrAwrnsIO : 5|1@0+ (1,0) [0|1] ""  TCP_LE,ONSTAR_LE,VCU_LE,IPC_LE
 SG_ LCConvMsgIndreq : 12|5@0+ (1,0) [0|31] ""  CSM_LE,VCU_LE,IPC_LE
 SG_ LCCIndReq : 15|3@0+ (1,0) [0|7] ""  TCP_LE,ONSTAR_LE,VCU_LE,IPC_LE
 SG_ LnCntrngCtlIcnLoctn : 23|4@0- (1,0) [-8|7] ""  VCU_LE,IPC_LE

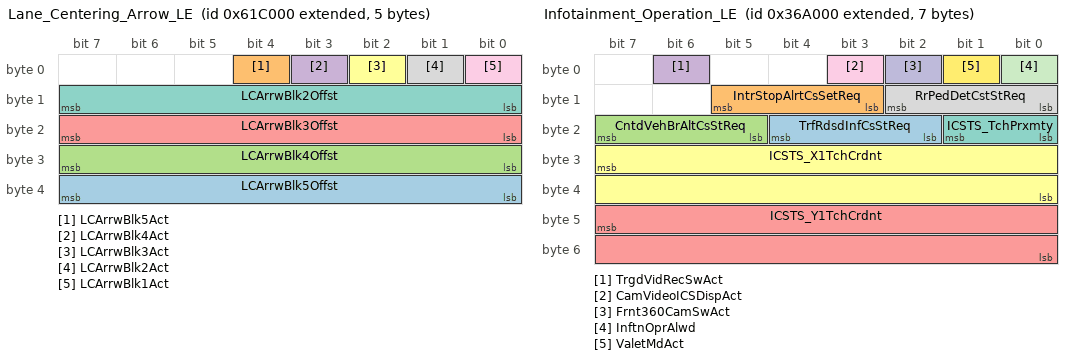
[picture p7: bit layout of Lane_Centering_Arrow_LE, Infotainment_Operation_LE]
BO_ 2153889792 Lane_Centering_Arrow_LE: 5 CGM_LE
 SG_ LCArrwBlk5Offst : 39|8@0- (1,0) [-128|127] ""  VCU_LE,IPC_LE
 SG_ LCArrwBlk5Act : 4|1@0+ (1,0) [0|1] ""  VCU_LE,IPC_LE
 SG_ LCArrwBlk4Offst : 31|8@0- (1,0) [-128|127] ""  VCU_LE,IPC_LE
 SG_ LCArrwBlk4Act : 3|1@0+ (1,0) [0|1] ""  VCU_LE,IPC_LE
 SG_ LCArrwBlk3Offst : 23|8@0- (1,0) [-128|127] ""  VCU_LE,IPC_LE
 SG_ LCArrwBlk3Act : 2|1@0+ (1,0) [0|1] ""  VCU_LE,IPC_LE
 SG_ LCArrwBlk2Offst : 15|8@0- (1,0) [-128|127] ""  VCU_LE,IPC_LE
 SG_ LCArrwBlk2Act : 1|1@0+ (1,0) [0|1] ""  VCU_LE,IPC_LE
 SG_ LCArrwBlk1Act : 0|1@0+ (1,0) [0|1] ""  VCU_LE,IPC_LE

BO_ 2151063552 Infotainment_Operation_LE: 7 RadioHead_LE
 SG_ TrfRdsdInfCsStReq : 20|3@0+ (1,0) [0|7] ""  CGM_LE,V2V_LE
 SG_ IntrStopAlrtCsSetReq : 13|3@0+ (1,0) [0|7] ""  CGM_LE,V2V_LE
 SG_ CntdVehBrAltCsStReq : 23|3@0+ (1,0) [0|7] ""  CGM_LE,V2V_LE
 SG_ TrgdVidRecSwAct : 6|1@0+ (1,0) [0|1] ""  CGM_LE,VPM_LE,Dummy_LE
 SG_ ICSTS_Y1TchCrdnt : 47|16@0+ (0.001526,0) [0|100] ""  CGM_LE,VPM_LE,Dummy_LE
 SG_ ICSTS_X1TchCrdnt : 31|16@0+ (0.001526,0) [0|100] ""  CGM_LE,VPM_LE,Dummy_LE
 SG_ ICSTS_TchPrxmty : 17|2@0+ (1,0) [0|3] ""  CGM_LE,VPM_LE,Dummy_LE
 SG_ RrPedDetCstStReq : 10|3@0+ (1,0) [0|7] ""  CGM_LE,VPM_LE,Dummy_LE
 SG_ CamVideoICSDispAct : 3|1@0+ (1,0) [0|1] ""  CGM_LE,VPM_LE,Dummy_LE
 SG_ Frnt360CamSwAct : 2|1@0+ (1,0) [0|1] ""  CGM_LE,VPM_LE,Dummy_LE
 SG_ InftnOprAlwd : 0|1@0+ (1,0) [0|1] ""  CGM_LE,LVMPC_LE,TCP_LE,UHP_Low_LE,RSC_LE,PDIM_LE,OTIM_LE,ONSTAR_LE,AMP_LE
 SG_ ValetMdAct : 1|1@0+ (1,0) [0|1] ""  ICS_LE,VCU_LE,IPC_LE,TCP_LE,CGM_LE,ONSTAR_LE,LVMPC_LE

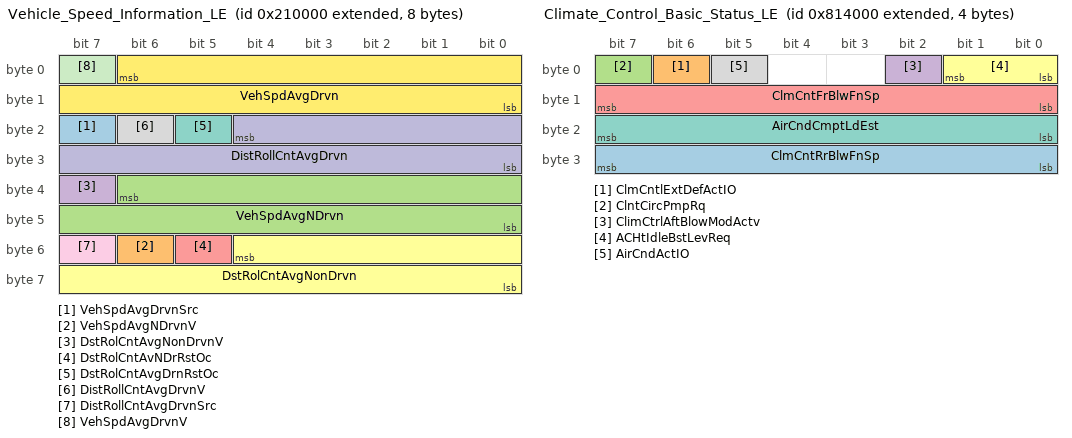
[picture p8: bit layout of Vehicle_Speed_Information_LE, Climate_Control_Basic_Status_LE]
BO_ 2149646336 Vehicle_Speed_Information_LE: 8 CGM_LE
 SG_ VehSpdAvgDrvnSrc : 23|1@0+ (1,0) [0|1] ""  CSM_LE,RadioHead_LE,VCU_LE,IPC_LE
 SG_ VehSpdAvgNDrvnV : 54|1@0+ (1,0) [0|1] ""  RCRM_LE,CSM_LE,VPM_LE,IPC_LE,PDIM_LE,VCU_LE,RadioHead_LE,CHUD_LE,HUD_LE
 SG_ VehSpdAvgNDrvn : 38|15@0+ (0.015625,0) [0|511.984375] "km / h"  RCRM_LE,VPM_LE,CSM_LE,ICS_LE,IPC_LE,PDIM_LE,VCU_LE,RadioHead_LE,CHUD_LE,HUD_LE
 SG_ DstRolCntAvgNonDrvnV : 39|1@0+ (1,0) [0|1] ""  CSM_LE,RadioHead_LE,VCU_LE,IPC_LE
 SG_ DstRolCntAvNDrRstOc : 53|1@0+ (1,0) [0|1] ""  CSM_LE,RadioHead_LE,VCU_LE,IPC_LE
 SG_ DstRolCntAvgNonDrvn : 52|13@0+ (0.125,0) [0|1023.875] "m"  CSM_LE,RadioHead_LE,VCU_LE,IPC_LE
 SG_ DstRolCntAvgDrnRstOc : 21|1@0+ (1,0) [0|1] ""  CSM_LE,RadioHead_LE,VCU_LE,IPC_LE
 SG_ DistRollCntAvgDrvnV : 22|1@0+ (1,0) [0|1] ""  CSM_LE,RadioHead_LE,VCU_LE,IPC_LE
 SG_ DistRollCntAvgDrvnSrc : 55|1@0+ (1,0) [0|1] ""  CSM_LE,RadioHead_LE,VCU_LE,IPC_LE
 SG_ DistRollCntAvgDrvn : 20|13@0+ (0.125,0) [0|1023.875] "m"  CSM_LE,RadioHead_LE,VCU_LE,IPC_LE
 SG_ VehSpdAvgDrvnV : 7|1@0+ (1,0) [0|1] ""  VKM_LE,AMP_LE,TCP_LE,ONSTAR_LE,LVMNav_LE,IPC_LE,OTIM_LE,CHUD_LE,HUD_LE,VCU_LE,CSM_LE,RadioHead_LE
 SG_ VehSpdAvgDrvn : 6|15@0+ (0.015625,0) [0|511.984375] "km / h"  VKM_LE,ICS_LE,AMP_LE,TCP_LE,ONSTAR_LE,LVMNav_LE,IPC_LE,OTIM_LE,CHUD_LE,HUD_LE,VCU_LE,CSM_LE,RadioHead_LE

BO_ 2154905600 Driver_Identifier_LE: 1 CGM_LE
 SG_ DrvSeatPrsMemID : 5|3@0+ (1,0) [0|7] ""  CSM_LE,EDI_LE,ONSTAR_LE,VCU_LE,IPC_LE,CHUD_LE,HUD_LE
 SG_ DrId : 2|3@0+ (1,0) [0|7] ""  EDI_LE,TCP_LE,IPC_LE,LVMNav_LE,ONSTAR_LE,VCU_LE,CSM_LE,RadioHead_LE

BO_ 2155954176 Climate_Control_Basic_Status_LE: 4 CGM_LE
 SG_ ClmCntRrBlwFnSp : 31|8@0+ (0.392157,0) [0|100.000035] "%"  Dummy_LE
 SG_ ClmCntlExtDefActIO : 6|1@0+ (1,0) [0|1] ""  RSC_LE,VCU_LE,IPC_LE
 SG_ ClntCircPmpRq : 7|1@0+ (1,0) [0|1] ""  RSC_LE
 SG_ ClimCtrlAftBlowModActv : 2|1@0+ (1,0) [0|1] ""  RSC_LE
 SG_ ClmCntFrBlwFnSp : 15|8@0+ (0.392157,0) [0|100.000035] "%"  RSA_LE,RSC_LE,IPC_LE,VCU_LE,CSM_LE,RadioHead_LE
 SG_ ACHtIdleBstLevReq : 1|2@0+ (1,0) [0|3] ""  RSC_LE
 SG_ AirCndCmptLdEst : 23|8@0+ (0.392157,0) [0|100.000035] "%"  RSC_LE,VCU_LE,IPC_LE
 SG_ AirCndActIO : 5|1@0+ (1,0) [0|1] ""  CSM_LE,RSC_LE,VCU_LE,IPC_LE

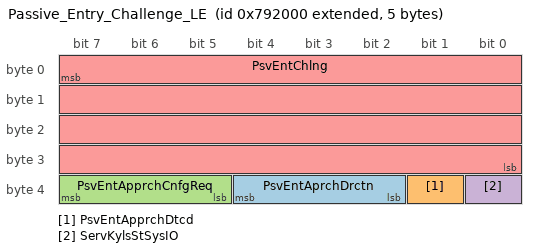
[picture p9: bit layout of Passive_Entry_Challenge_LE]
BO_ 2155421696 Passive_Entry_Challenge_LE: 5 CGM_LE
 SG_ PsvEntAprchDrctn : 36|3@0+ (1,0) [0|7] ""  Dummy_LE
 SG_ PsvEntApprchDtcd : 33|1@0+ (1,0) [0|1] ""  Dummy_LE
 SG_ PsvEntApprchCnfgReq : 39|3@0+ (1,0) [0|7] ""  Dummy_LE
 SG_ ServKylsStSysIO : 32|1@0+ (1,0) [0|1] ""  VCU_LE,IPC_LE
 SG_ PsvEntChlng : 7|32@0+ (1,0) [0|4294967295] "passwrd"  TCP_LE,ONSTAR_LE,VCU_LE,CSM_LE,RadioHead_LE,Dummy_LE

BO_ 2153938944 Remote_Reflash_Req_LE: 1 RadioHead_LE
 SG_ RmtRflshMdReqtd : 7|1@0+ (1,0) [0|1] ""  CGM_LE

BO_TX_BU_ 2151047168 : VCU_LE,IPC_LE,CHUD_LE,HUD_LE;
BO_TX_BU_ 1618 : TouchPad_LE,DVB_T_LE;
BO_TX_BU_ 1586 : TouchPad_LE,DVB_T_LE;
BO_TX_BU_ 1362 : TouchPad_LE,DVB_T_LE;
BO_TX_BU_ 2158067712 : VCU_LE,RadioHead_LE;
BO_TX_BU_ 2158051328 : VCU_LE,RadioHead_LE;
BO_TX_BU_ 2154627072 : CSM_LE,VCU_LE,RadioHead_LE;
BO_TX_BU_ 2154692608 : TCP_LE,UHP_Low_LE,DVB_T_LE,ONSTAR_LE;
BO_TX_BU_ 1604 : VCU_LE,CSM_LE,RadioHead_LE,CHM_LE;
BO_TX_BU_ 1348 : VCU_LE,CSM_LE,RadioHead_LE,CHM_LE;
BO_TX_BU_ 1572 : VCU_LE,CSM_LE,RadioHead_LE,CHM_LE;
BO_TX_BU_ 2153775104 : VCU_LE,CHUD_LE,VKM_LE,RCRM_LE,VPM_LE,V2V_LE,TCP_LE,CSM_LE,UHP_Low_LE,TouchPad_LE,RSE_LE,RSC_LE,RSA_LE,PDIM_LE,OTIM_LE,ICS_LE,LVMPC_LE,LVMNav_LE,DVB_T_LE,ONSTAR_LE,HUD_LE,IPC_LE,RadioHead_LE,CHM_LE,CGM_LE,AMP_LE;
BO_TX_BU_ 2151718912 : VCU_LE,CSM_LE,IPC_LE,RadioHead_LE,CHM_LE,AMP_LE;
BO_TX_BU_ 2155020288 : CSM_LE,VCU_LE,RadioHead_LE;
BO_TX_BU_ 2151677952 : V2V_LE,VPM_LE,TCP_LE,CSM_LE,RadioHead_LE,ONSTAR_LE,VCU_LE,IPC_LE,CHUD_LE,HUD_LE,CGM_LE;
BO_TX_BU_ 2149859328 : VCU_LE,IPC_LE;
BO_TX_BU_ 2156945408 : CSM_LE,ONSTAR_LE;
BO_TX_BU_ 2151063552 : VCU_LE,CSM_LE,RadioHead_LE;
BO_TX_BU_ 2153938944 : VCU_LE,CSM_LE,RadioHead_LE;
CM_ SG_ 2149711872 ACCHdwyStg "Headway is the  time which results from dividing the following distance (or gap) between vehicles by the vehicle speed.  This setting allows the driver to choose a Headway Setting without actually knowing the value of this time.";
CM_ SG_ 2149629952 MainLghtSw "Operator selection for the main lighting switch";
CM_ SG_ 2149629952 RevLmpAtv "Indicates if backup lamps are active - Changed name to Reversing Lamps Active";
CM_ SG_ 2158051328 RmtRcvrTunVal "To be used with the Remote Receiver Tune Command signal";
CM_ SG_ 2153775104 DTCI_DTCFaultType "Based on Powertrain definition.  Not expected to be supported by all devices.";
CM_ SG_ 2153775104 DTCI_DTCFailType "Assigned per GMW3110, Appendix E";
CM_ SG_ 2153775104 DTCI_DTCSource "This shall be equal to the Diagnostic Address of the transmittting device.";
CM_ SG_ 2155167744 NRmtDtdPsBrkRstIO "Used to display notification to the driver that they do not have the fob in the vehicle when they pressed the off button.  Gives the driver a chance to obtain the fob before shutting off the car.";
CM_ SG_ 2154905600 DrId "Driver 8 changed to Unknown on 3/30/99";
BA_DEF_ SG_  "VNSigPrimaryTriggering" ENUM  "No","Yes","DLCLS","DLCHS","DLCCE","DLCFO";
BA_DEF_ SG_  "VNSigRemoteDiagnostics" ENUM  "No","Yes","DLCLS","DLCHS","DLCCE","DLCFO";
BA_DEF_ SG_  "VNSigInfotainment" ENUM  "No","Yes","DLCLS","DLCHS","DLCCE","DLCFO";
BA_DEF_ SG_  "VNSigParkedVehicle" ENUM  "No","Yes","DLCLS","DLCHS","DLCCE","DLCFO";
BA_DEF_ SG_  "VNSigIntermediate" ENUM  "No","Yes","DLCLS","DLCHS","DLCCE","DLCFO";
BA_DEF_ SG_  "VNSigUnused_4" ENUM  "No","Yes","DLCLS","DLCHS","DLCCE","DLCFO";
BA_DEF_ SG_  "SignalType" STRING ;
BA_DEF_ SG_  "PacketOrder" INT 0 65535;
BA_DEF_ SG_  "SignalLongName" STRING ;
BA_DEF_ SG_  "GenSigStartValue" INT 0 65535;
BA_DEF_ SG_  "VNSigDiagnostic" ENUM  "No","Yes","DLCLS","DLCHS","DLCCE","DLCFO";
BA_DEF_ SG_  "VNSigAllNodes" ENUM  "No","Yes","DLCLS","DLCHS","DLCCE","DLCFO";
BA_DEF_ SG_  "GenSigDeltaValue" INT 0 0;
BA_DEF_ SG_  "GenSigSendType" ENUM  "not used","not used","not used","not used","not used","not used","not used","NoSigSendType","not used","not used","OnAnyChange","OnChangeIfActive","OnDelta","DLCLS","DLCHS","DLCCE","DLCFO";
BA_DEF_ SG_  "GenSigSendOnInit" ENUM  "Not Initialized","Application","Handler","DLCLS","DLCHS","DLCCE","DLCFO";
BA_DEF_ BO_  "AppGenMsgCycleTime" INT 0 0;
BA_DEF_ BO_  "TpTxIndex" INT 0 99;
BA_DEF_ BO_  "GenMsgILSupport" ENUM  "No","Yes","DLCLS","DLCHS","DLCCE","DLCFO";
BA_DEF_ BO_  "TpApplType" STRING ;
BA_DEF_ BO_  "Prio" INT 0 7;
BA_DEF_ BO_  "MessageSubnet" ENUM  "LS","MS","HS","CE","PE","HV","FO","S1","HE","LE","HE2","DLCLS","DLCHS","DLCCE","DLCFO";
BA_DEF_ BO_  "GenMsgMandatoryToSupervision" ENUM  "No","Yes","DLCLS","DLCHS","DLCCE","DLCFO";
BA_DEF_ BO_  "DiagState" ENUM  "No","Yes","DLCLS","DLCHS","DLCCE","DLCFO";
BA_DEF_ BO_  "GenMsgStartDelayTime" INT 0 100000;
BA_DEF_ BO_  "GenMsgDelayTime" INT 0 100000;
BA_DEF_ BO_  "GenMsgCycleTime" INT 0 100000;
BA_DEF_ BO_  "GenMsgSendType" ENUM  "cyclicX","spontanX","cyclicIfActiveX","spontanWithDelay","cyclicAndSpontanX","cyclicAndSpontanWithDelay","spontanWithRepitition","cyclicIfActiveAndSpontanWD","DLCLS","DLCHS","DLCCE","DLCFO";
BA_DEF_ BO_  "DiagResponse" ENUM  "No","Yes","DLCLS","DLCHS","DLCCE","DLCFO";
BA_DEF_ BO_  "DiagRequest" ENUM  "No","Yes","DLCLS","DLCHS","DLCCE","DLCFO";
BA_DEF_ BO_  "NmMessage" ENUM  "No","Yes","DLCLS","DLCHS","DLCCE","DLCFO";
BA_DEF_REL_ BU_SG_REL_  "GenSigSuprvRespComment" STRING ;
BA_DEF_REL_ BU_SG_REL_  "GenSigVBitResp" ENUM  "No","Yes","DLCLS","DLCHS","DLCCE","DLCFO";
BA_DEF_REL_ BU_SG_REL_  "GenSigVBitRespComment" STRING ;
BA_DEF_REL_ BU_SG_REL_  "GenSigVDAFailComment" STRING ;
BA_DEF_REL_ BU_SG_REL_  "GenSigVDAFailResp" ENUM  "No","Yes","DLCLS","DLCHS","DLCCE","DLCFO";
BA_DEF_REL_ BU_SG_REL_  "GenSigRxStartValue" STRING ;
BA_DEF_REL_ BU_SG_REL_  "GenSigSuprvRespSubValue" INT 0 65535;
BA_DEF_REL_ BU_SG_REL_  "GenSigSuprvResp" ENUM  "None","Notify App","Substitute Default","DLCLS","DLCHS","DLCCE","DLCFO";
BA_DEF_REL_ BU_SG_REL_  "GenSigTimeoutMsg" HEX -2147483648 268435455;
BA_DEF_DEF_  "VNSigPrimaryTriggering" "No";
BA_DEF_DEF_  "VNSigRemoteDiagnostics" "No";
BA_DEF_DEF_  "VNSigInfotainment" "No";
BA_DEF_DEF_  "VNSigParkedVehicle" "No";
BA_DEF_DEF_  "VNSigIntermediate" "No";
BA_DEF_DEF_  "VNSigUnused_4" "No";
BA_DEF_DEF_  "SignalType" "";
BA_DEF_DEF_  "PacketOrder" 0;
BA_DEF_DEF_  "SignalLongName" "";
BA_DEF_DEF_  "GenSigStartValue" 0;
BA_DEF_DEF_  "VNSigDiagnostic" "No";
BA_DEF_DEF_  "VNSigAllNodes" "No";
BA_DEF_DEF_  "GenSigDeltaValue" 0;
BA_DEF_DEF_  "GenSigSendType" "NoSigSendType";
BA_DEF_DEF_  "GenSigSendOnInit" "Not Initialized";
BA_DEF_DEF_  "AppGenMsgCycleTime" 0;
BA_DEF_DEF_  "TpTxIndex" 0;
BA_DEF_DEF_  "GenMsgILSupport" "Yes";
BA_DEF_DEF_  "TpApplType" "";
BA_DEF_DEF_  "Prio" 4;
BA_DEF_DEF_  "MessageSubnet" "FO";
BA_DEF_DEF_  "GenMsgMandatoryToSupervision" "No";
BA_DEF_DEF_  "DiagState" "No";
BA_DEF_DEF_  "GenMsgStartDelayTime" 0;
BA_DEF_DEF_  "GenMsgDelayTime" 0;
BA_DEF_DEF_  "GenMsgCycleTime" 0;
BA_DEF_DEF_  "GenMsgSendType" "spontanX";
BA_DEF_DEF_  "DiagResponse" "No";
BA_DEF_DEF_  "DiagRequest" "No";
BA_DEF_DEF_  "NmMessage" "No";
BA_DEF_DEF_REL_ "GenSigSuprvRespComment" "";
BA_DEF_DEF_REL_ "GenSigVBitResp" "No";
BA_DEF_DEF_REL_ "GenSigVBitRespComment" "";
BA_DEF_DEF_REL_ "GenSigVDAFailComment" "";
BA_DEF_DEF_REL_ "GenSigVDAFailResp" "No";
BA_DEF_DEF_REL_ "GenSigRxStartValue" "";
BA_DEF_DEF_REL_ "GenSigSuprvRespSubValue" 0;
BA_DEF_DEF_REL_ "GenSigSuprvResp" "None";
BA_DEF_DEF_REL_ "GenSigTimeoutMsg" 0;
BA_ "MessageSubnet" BO_ 2149826560 9;
BA_ "GenMsgDelayTime" BO_ 2149826560 100;
BA_ "MessageSubnet" BO_ 2149711872 9;
BA_ "GenMsgStartDelayTime" BO_ 2149711872 120;
BA_ "GenMsgCycleTime" BO_ 2149711872 100;
BA_ "GenMsgSendType" BO_ 2149711872 0;
BA_ "MessageSubnet" BO_ 2149629952 9;
BA_ "GenMsgMandatoryToSupervision" BO_ 2149629952 1;
BA_ "GenMsgDelayTime" BO_ 2149629952 30;
BA_ "MessageSubnet" BO_ 2151047168 9;
BA_ "GenMsgDelayTime" BO_ 2151047168 100;
BA_ "Prio" BO_ 1618 0;
BA_ "MessageSubnet" BO_ 1618 9;
BA_ "DiagResponse" BO_ 1618 1;
BA_ "Prio" BO_ 1586 0;
BA_ "MessageSubnet" BO_ 1586 9;
BA_ "GenMsgCycleTime" BO_ 1586 3000;
BA_ "GenMsgSendType" BO_ 1586 0;
BA_ "NmMessage" BO_ 1586 1;
BA_ "GenMsgILSupport" BO_ 1362 0;
BA_ "TpApplType" BO_ 1362 "DiagUUDTResponse";
BA_ "Prio" BO_ 1362 0;
BA_ "MessageSubnet" BO_ 1362 9;
BA_ "MessageSubnet" BO_ 2153947136 9;
BA_ "GenMsgDelayTime" BO_ 2153947136 100;
BA_ "MessageSubnet" BO_ 2158067712 9;
BA_ "GenMsgDelayTime" BO_ 2158067712 100;
BA_ "MessageSubnet" BO_ 2158051328 9;
BA_ "GenMsgDelayTime" BO_ 2158051328 100;
BA_ "MessageSubnet" BO_ 2158034944 9;
BA_ "GenMsgDelayTime" BO_ 2158034944 100;
BA_ "MessageSubnet" BO_ 2158018560 9;
BA_ "GenMsgDelayTime" BO_ 2158018560 100;
BA_ "MessageSubnet" BO_ 2154627072 9;
BA_ "GenMsgDelayTime" BO_ 2154627072 100;
BA_ "GenMsgCycleTime" BO_ 2154627072 1200;
BA_ "GenMsgSendType" BO_ 2154627072 0;
BA_ "MessageSubnet" BO_ 2154692608 9;
BA_ "GenMsgDelayTime" BO_ 2154692608 10;
BA_ "GenMsgCycleTime" BO_ 2154692608 1200;
BA_ "GenMsgSendType" BO_ 2154692608 0;
BA_ "Prio" BO_ 1604 0;
BA_ "MessageSubnet" BO_ 1604 9;
BA_ "DiagResponse" BO_ 1604 1;
BA_ "TpApplType" BO_ 1348 "DiagUUDTResponse";
BA_ "Prio" BO_ 1348 0;
BA_ "MessageSubnet" BO_ 1348 9;
BA_ "Prio" BO_ 1572 0;
BA_ "MessageSubnet" BO_ 1572 9;
BA_ "GenMsgCycleTime" BO_ 1572 3000;
BA_ "GenMsgSendType" BO_ 1572 0;
BA_ "NmMessage" BO_ 1572 1;
BA_ "Prio" BO_ 1620 0;
BA_ "MessageSubnet" BO_ 1620 9;
BA_ "DiagResponse" BO_ 1620 1;
BA_ "Prio" BO_ 1588 0;
BA_ "MessageSubnet" BO_ 1588 9;
BA_ "GenMsgCycleTime" BO_ 1588 3000;
BA_ "GenMsgSendType" BO_ 1588 0;
BA_ "NmMessage" BO_ 1588 1;
BA_ "GenMsgILSupport" BO_ 1364 0;
BA_ "TpApplType" BO_ 1364 "DiagUUDTResponse";
BA_ "Prio" BO_ 1364 0;
BA_ "MessageSubnet" BO_ 1364 9;
BA_ "MessageSubnet" BO_ 2153775104 9;
BA_ "GenMsgDelayTime" BO_ 2153775104 1000;
BA_ "MessageSubnet" BO_ 2150703104 9;
BA_ "GenMsgDelayTime" BO_ 2150703104 100;
BA_ "MessageSubnet" BO_ 2151718912 9;
BA_ "GenMsgDelayTime" BO_ 2151718912 10;
BA_ "MessageSubnet" BO_ 2155020288 9;
BA_ "GenMsgDelayTime" BO_ 2155020288 100;
BA_ "MessageSubnet" BO_ 2151677952 9;
BA_ "GenMsgDelayTime" BO_ 2151677952 100;
BA_ "MessageSubnet" BO_ 2149851136 9;
BA_ "GenMsgStartDelayTime" BO_ 2149851136 120;
BA_ "GenMsgDelayTime" BO_ 2149851136 30;
BA_ "GenMsgCycleTime" BO_ 2149851136 5000;
BA_ "GenMsgSendType" BO_ 2149851136 0;
BA_ "MessageSubnet" BO_ 2149859328 9;
BA_ "GenMsgMandatoryToSupervision" BO_ 2149859328 1;
BA_ "GenMsgDelayTime" BO_ 2149859328 100;
BA_ "GenMsgCycleTime" BO_ 2149859328 5000;
BA_ "GenMsgSendType" BO_ 2149859328 0;
BA_ "MessageSubnet" BO_ 2155167744 9;
BA_ "GenMsgDelayTime" BO_ 2155167744 100;
BA_ "MessageSubnet" BO_ 2152611840 9;
BA_ "GenMsgDelayTime" BO_ 2152611840 100;
BA_ "GenMsgCycleTime" BO_ 2152611840 3000;
BA_ "GenMsgSendType" BO_ 2152611840 0;
BA_ "MessageSubnet" BO_ 2156945408 9;
BA_ "GenMsgDelayTime" BO_ 2156945408 100;
BA_ "MessageSubnet" BO_ 2151292928 9;
BA_ "GenMsgDelayTime" BO_ 2151292928 100;
BA_ "MessageSubnet" BO_ 2151464960 9;
BA_ "GenMsgDelayTime" BO_ 2151464960 100;
BA_ "MessageSubnet" BO_ 2151448576 9;
BA_ "GenMsgDelayTime" BO_ 2151448576 100;
BA_ "MessageSubnet" BO_ 2153930752 9;
BA_ "GenMsgDelayTime" BO_ 2153930752 100;
BA_ "AppGenMsgCycleTime" BO_ 2153889792 250;
BA_ "MessageSubnet" BO_ 2153889792 9;
BA_ "GenMsgDelayTime" BO_ 2153889792 100;
BA_ "MessageSubnet" BO_ 2151063552 9;
BA_ "GenMsgDelayTime" BO_ 2151063552 100;
BA_ "MessageSubnet" BO_ 2149646336 9;
BA_ "GenMsgMandatoryToSupervision" BO_ 2149646336 1;
BA_ "GenMsgStartDelayTime" BO_ 2149646336 110;
BA_ "GenMsgCycleTime" BO_ 2149646336 100;
BA_ "GenMsgSendType" BO_ 2149646336 0;
BA_ "Prio" BO_ 2154905600 3;
BA_ "MessageSubnet" BO_ 2154905600 9;
BA_ "GenMsgDelayTime" BO_ 2154905600 100;
BA_ "MessageSubnet" BO_ 2155954176 9;
BA_ "GenMsgDelayTime" BO_ 2155954176 100;
BA_ "GenMsgCycleTime" BO_ 2155954176 2500;
BA_ "GenMsgSendType" BO_ 2155954176 0;
BA_ "Prio" BO_ 2155421696 3;
BA_ "MessageSubnet" BO_ 2155421696 9;
BA_ "GenMsgDelayTime" BO_ 2155421696 100;
BA_ "MessageSubnet" BO_ 2153938944 9;
BA_ "GenMsgDelayTime" BO_ 2153938944 100;
BA_ "GenSigSendType" SG_ 2149826560 SpdSignUltdDetdIO 10;
BA_ "SignalType" SG_ 2149826560 SpdSignUltdDetdIO "BLN";
BA_ "SignalLongName" SG_ 2149826560 SpdSignUltdDetdIO "Speed Sign Unlimited Detected Indication On";
BA_ "VNSigAllNodes" SG_ 2149826560 SpdSignUltdDetdIO 1;
BA_ "GenSigSendType" SG_ 2149826560 TrfcSgnMmryIcePosIO 10;
BA_ "SignalType" SG_ 2149826560 TrfcSgnMmryIcePosIO "BLN";
BA_ "SignalLongName" SG_ 2149826560 TrfcSgnMmryIcePosIO "Traffic Sign Memory Ice Possible Indication On";
BA_ "VNSigAllNodes" SG_ 2149826560 TrfcSgnMmryIcePosIO 1;
BA_ "GenSigSendType" SG_ 2149826560 SpdLmtVsnFsdSpdUnt 10;
BA_ "SignalType" SG_ 2149826560 SpdLmtVsnFsdSpdUnt "ENM";
BA_ "SignalLongName" SG_ 2149826560 SpdLmtVsnFsdSpdUnt "Speed Limit Vision Fused Speed Unit";
BA_ "VNSigAllNodes" SG_ 2149826560 SpdLmtVsnFsdSpdUnt 1;
BA_ "GenSigSendType" SG_ 2149826560 SpdLmtVnFsSpdNwDet 10;
BA_ "SignalType" SG_ 2149826560 SpdLmtVnFsSpdNwDet "BLN";
BA_ "SignalLongName" SG_ 2149826560 SpdLmtVnFsSpdNwDet "Speed Limit Vision Fused Speed New Detected";
BA_ "VNSigAllNodes" SG_ 2149826560 SpdLmtVnFsSpdNwDet 1;
BA_ "GenSigSendType" SG_ 2149826560 SpdLmtVsnFsdSpdM 10;
BA_ "SignalType" SG_ 2149826560 SpdLmtVsnFsdSpdM "ENM";
BA_ "SignalLongName" SG_ 2149826560 SpdLmtVsnFsdSpdM "Speed Limit Vision Fused Speed Mask";
BA_ "VNSigAllNodes" SG_ 2149826560 SpdLmtVsnFsdSpdM 1;
BA_ "GenSigDeltaValue" SG_ 2149826560 SpdLmtVsnFsdSpd 1;
BA_ "GenSigSendType" SG_ 2149826560 SpdLmtVsnFsdSpd 12;
BA_ "SignalType" SG_ 2149826560 SpdLmtVsnFsdSpd "UNM";
BA_ "SignalLongName" SG_ 2149826560 SpdLmtVsnFsdSpd "Speed Limit Vision Fused Speed";
BA_ "VNSigAllNodes" SG_ 2149826560 SpdLmtVsnFsdSpd 1;
BA_ "GenSigSendType" SG_ 2149826560 FOAI_VehAhdIndRq11E 10;
BA_ "SignalType" SG_ 2149826560 FOAI_VehAhdIndRq11E "ENM";
BA_ "PacketOrder" SG_ 2149826560 FOAI_VehAhdIndRq11E 3;
BA_ "SignalLongName" SG_ 2149826560 FOAI_VehAhdIndRq11E "Forward Object Alert Indications : Vehicle Ahead Indication Request";
BA_ "VNSigAllNodes" SG_ 2149826560 FOAI_VehAhdIndRq11E 1;
BA_ "GenSigSendType" SG_ 2149826560 FOAI_AlrtWrnIndRq11E 10;
BA_ "SignalType" SG_ 2149826560 FOAI_AlrtWrnIndRq11E "ENM";
BA_ "PacketOrder" SG_ 2149826560 FOAI_AlrtWrnIndRq11E 2;
BA_ "SignalLongName" SG_ 2149826560 FOAI_AlrtWrnIndRq11E "Forward Object Alert Indications : Alert Warning Indication Request";
BA_ "VNSigAllNodes" SG_ 2149826560 FOAI_AlrtWrnIndRq11E 1;
BA_ "GenSigSendType" SG_ 2149826560 FOAI_AlrtChmIhbRq11E 10;
BA_ "SignalType" SG_ 2149826560 FOAI_AlrtChmIhbRq11E "ENM";
BA_ "PacketOrder" SG_ 2149826560 FOAI_AlrtChmIhbRq11E 1;
BA_ "SignalLongName" SG_ 2149826560 FOAI_AlrtChmIhbRq11E "Forward Object Alert Indications : Alert Warning Chime Inhibit Request";
BA_ "VNSigAllNodes" SG_ 2149826560 FOAI_AlrtChmIhbRq11E 1;
BA_ "GenSigSendType" SG_ 2149826560 FwdClnAlrtOffIO11E 10;
BA_ "SignalType" SG_ 2149826560 FwdClnAlrtOffIO11E "BLN";
BA_ "SignalLongName" SG_ 2149826560 FwdClnAlrtOffIO11E "Forward Collision Alert Off Indication On";
BA_ "VNSigAllNodes" SG_ 2149826560 FwdClnAlrtOffIO11E 1;
BA_ "GenSigSendType" SG_ 2149826560 FwdClnAlrtPr11E 10;
BA_ "GenSigSendOnInit" SG_ 2149826560 FwdClnAlrtPr11E 1;
BA_ "SignalType" SG_ 2149826560 FwdClnAlrtPr11E "BLN";
BA_ "SignalLongName" SG_ 2149826560 FwdClnAlrtPr11E "Forward Collision Alert Present";
BA_ "VNSigAllNodes" SG_ 2149826560 FwdClnAlrtPr11E 1;
BA_ "GenSigSendType" SG_ 2149826560 FCABrkPrflReq 10;
BA_ "SignalType" SG_ 2149826560 FCABrkPrflReq "BLN";
BA_ "SignalLongName" SG_ 2149826560 FCABrkPrflReq "Forward Collision Alert Brake Prefill Request";
BA_ "VNSigAllNodes" SG_ 2149826560 FCABrkPrflReq 1;
BA_ "GenSigSendType" SG_ 2149826560 FCAHdwyStngIO 10;
BA_ "SignalType" SG_ 2149826560 FCAHdwyStngIO "BLN";
BA_ "SignalLongName" SG_ 2149826560 FCAHdwyStngIO "Forward Collision Alert Headway Setting Indication On";
BA_ "VNSigAllNodes" SG_ 2149826560 FCAHdwyStngIO 1;
BA_ "GenSigSendType" SG_ 2149826560 FCAGpStng 10;
BA_ "SignalType" SG_ 2149826560 FCAGpStng "ENM";
BA_ "SignalLongName" SG_ 2149826560 FCAGpStng "Forward Collision Alert Gap Setting";
BA_ "VNSigAllNodes" SG_ 2149826560 FCAGpStng 1;
BA_ "GenSigSendType" SG_ 2149826560 FCACrusCtrlCnclReqd 10;
BA_ "SignalType" SG_ 2149826560 FCACrusCtrlCnclReqd "BLN";
BA_ "SignalLongName" SG_ 2149826560 FCACrusCtrlCnclReqd "Forward Collision Alert Cruise Control Cancel Requested";
BA_ "VNSigAllNodes" SG_ 2149826560 FCACrusCtrlCnclReqd 1;
BA_ "SignalType" SG_ 2149711872 SetSpdLmtRchd "ENM";
BA_ "SignalLongName" SG_ 2149711872 SetSpdLmtRchd "Set Speed Limit Reached";
BA_ "VNSigAllNodes" SG_ 2149711872 SetSpdLmtRchd 1;
BA_ "SignalType" SG_ 2149711872 FOAI_VehAhdIndRq "ENM";
BA_ "PacketOrder" SG_ 2149711872 FOAI_VehAhdIndRq 2;
BA_ "SignalLongName" SG_ 2149711872 FOAI_VehAhdIndRq "Forward Object Alert Indications : Vehicle Ahead Indication Request";
BA_ "VNSigAllNodes" SG_ 2149711872 FOAI_VehAhdIndRq 1;
BA_ "SignalType" SG_ 2149711872 FOAI_AlrtWrnIndRq "ENM";
BA_ "PacketOrder" SG_ 2149711872 FOAI_AlrtWrnIndRq 3;
BA_ "SignalLongName" SG_ 2149711872 FOAI_AlrtWrnIndRq "Forward Object Alert Indications : Alert Warning Indication Request";
BA_ "VNSigAllNodes" SG_ 2149711872 FOAI_AlrtWrnIndRq 1;
BA_ "SignalType" SG_ 2149711872 FOAI_AlrtChmIhbRq "ENM";
BA_ "PacketOrder" SG_ 2149711872 FOAI_AlrtChmIhbRq 1;
BA_ "SignalLongName" SG_ 2149711872 FOAI_AlrtChmIhbRq "Forward Object Alert Indications : Alert Warning Chime Inhibit Request";
BA_ "VNSigAllNodes" SG_ 2149711872 FOAI_AlrtChmIhbRq 1;
BA_ "SignalType" SG_ 2149711872 FwdClnAlrtOffIO "BLN";
BA_ "SignalLongName" SG_ 2149711872 FwdClnAlrtOffIO "Forward Collision Alert Off Indication On";
BA_ "VNSigAllNodes" SG_ 2149711872 FwdClnAlrtOffIO 1;
BA_ "SignalType" SG_ 2149711872 FwdClnAlrtPr "BLN";
BA_ "SignalLongName" SG_ 2149711872 FwdClnAlrtPr "Forward Collision Alert Present";
BA_ "VNSigAllNodes" SG_ 2149711872 FwdClnAlrtPr 1;
BA_ "SignalType" SG_ 2149711872 VehDynYawRateV "ENM";
BA_ "SignalLongName" SG_ 2149711872 VehDynYawRateV "Vehicle Dynamics Yaw Rate Validity";
BA_ "VNSigAllNodes" SG_ 2149711872 VehDynYawRateV 1;
BA_ "SignalType" SG_ 2149711872 ACCHdwyStg "ENM";
BA_ "SignalLongName" SG_ 2149711872 ACCHdwyStg "Adaptive Cruise Control Headway Setting";
BA_ "VNSigAllNodes" SG_ 2149711872 ACCHdwyStg 1;
BA_ "SignalType" SG_ 2149711872 ACCDrvrSeltdSpd "UNM";
BA_ "SignalLongName" SG_ 2149711872 ACCDrvrSeltdSpd "Adaptive Cruise Control Driver Selected Speed";
BA_ "VNSigAllNodes" SG_ 2149711872 ACCDrvrSeltdSpd 1;
BA_ "SignalType" SG_ 2149711872 AdapCrsCntVDA "ENM";
BA_ "SignalLongName" SG_ 2149711872 AdapCrsCntVDA "Adaptive Cruise Control Virtual Device Availability";
BA_ "GenSigStartValue" SG_ 2149711872 AdapCrsCntVDA 1;
BA_ "VNSigAllNodes" SG_ 2149711872 AdapCrsCntVDA 1;
BA_ "SignalType" SG_ 2149711872 SpdLmtrSpdWrngEnbld "BLN";
BA_ "SignalLongName" SG_ 2149711872 SpdLmtrSpdWrngEnbld "Speed Limiter/Speed Warning Enabled";
BA_ "VNSigAllNodes" SG_ 2149711872 SpdLmtrSpdWrngEnbld 1;
BA_ "SignalType" SG_ 2149711872 VehDynYawRate "SNM";
BA_ "SignalLongName" SG_ 2149711872 VehDynYawRate "Vehicle Dynamics Yaw Rate";
BA_ "VNSigAllNodes" SG_ 2149711872 VehDynYawRate 1;
BA_ "SignalType" SG_ 2149711872 CrsCntlDrSelSpdAct "BLN";
BA_ "SignalLongName" SG_ 2149711872 CrsCntlDrSelSpdAct "Cruise Control Driver Selected Speed Active";
BA_ "VNSigAllNodes" SG_ 2149711872 CrsCntlDrSelSpdAct 1;
BA_ "SignalType" SG_ 2149711872 ACCAct370 "BLN";
BA_ "SignalLongName" SG_ 2149711872 ACCAct370 "Adaptive Cruise Control Active";
BA_ "VNSigAllNodes" SG_ 2149711872 ACCAct370 1;
BA_ "SignalType" SG_ 2149711872 SpdLmtrSpdWrngAct "BLN";
BA_ "SignalLongName" SG_ 2149711872 SpdLmtrSpdWrngAct "Speed Limiter/Speed Warning Active";
BA_ "VNSigAllNodes" SG_ 2149711872 SpdLmtrSpdWrngAct 1;
BA_ "SignalType" SG_ 2149711872 CrsSpdLmtrDrvSelSpd "UNM";
BA_ "SignalLongName" SG_ 2149711872 CrsSpdLmtrDrvSelSpd "Cruise and Speed Limiter Driver Selected Speed";
BA_ "VNSigAllNodes" SG_ 2149711872 CrsSpdLmtrDrvSelSpd 1;
BA_ "SignalType" SG_ 2149711872 AutoMdSpdLmtStat "ENM";
BA_ "SignalLongName" SG_ 2149711872 AutoMdSpdLmtStat "Auto Mode Speed Limit Status";
BA_ "VNSigAllNodes" SG_ 2149711872 AutoMdSpdLmtStat 1;
BA_ "SignalType" SG_ 2149711872 ACCAutoSetSpdStat "ENM";
BA_ "SignalLongName" SG_ 2149711872 ACCAutoSetSpdStat "Adaptive Cruise Control Auto Set Speed Status";
BA_ "VNSigAllNodes" SG_ 2149711872 ACCAutoSetSpdStat 1;
BA_ "GenSigSendType" SG_ 2149629952 RtTrnLmpOn 10;
BA_ "VNSigParkedVehicle" SG_ 2149629952 RtTrnLmpOn 1;
BA_ "SignalType" SG_ 2149629952 RtTrnLmpOn "BLN";
BA_ "SignalLongName" SG_ 2149629952 RtTrnLmpOn "Right Turn Lamp On";
BA_ "VNSigAllNodes" SG_ 2149629952 RtTrnLmpOn 1;
BA_ "GenSigSendType" SG_ 2149629952 LftTrnLmpOn 10;
BA_ "VNSigParkedVehicle" SG_ 2149629952 LftTrnLmpOn 1;
BA_ "SignalType" SG_ 2149629952 LftTrnLmpOn "BLN";
BA_ "SignalLongName" SG_ 2149629952 LftTrnLmpOn "Left Turn Lamp On";
BA_ "VNSigAllNodes" SG_ 2149629952 LftTrnLmpOn 1;
BA_ "GenSigSendType" SG_ 2149629952 FrFogLmpsAct 10;
BA_ "GenSigSendOnInit" SG_ 2149629952 FrFogLmpsAct 1;
BA_ "SignalType" SG_ 2149629952 FrFogLmpsAct "BLN";
BA_ "SignalLongName" SG_ 2149629952 FrFogLmpsAct "Front Fog Lamps Active";
BA_ "VNSigAllNodes" SG_ 2149629952 FrFogLmpsAct 1;
BA_ "GenSigSendType" SG_ 2149629952 HiBmReqd 10;
BA_ "SignalType" SG_ 2149629952 HiBmReqd "BLN";
BA_ "SignalLongName" SG_ 2149629952 HiBmReqd "High Beam Requested";
BA_ "VNSigAllNodes" SG_ 2149629952 HiBmReqd 1;
BA_ "GenSigSendType" SG_ 2149629952 PrkLtRightOn 10;
BA_ "GenSigSendOnInit" SG_ 2149629952 PrkLtRightOn 2;
BA_ "VNSigParkedVehicle" SG_ 2149629952 PrkLtRightOn 1;
BA_ "SignalType" SG_ 2149629952 PrkLtRightOn "BLN";
BA_ "SignalLongName" SG_ 2149629952 PrkLtRightOn "Park Light Right On";
BA_ "VNSigAllNodes" SG_ 2149629952 PrkLtRightOn 1;
BA_ "GenSigSendType" SG_ 2149629952 PrkLtLeftOn 10;
BA_ "GenSigSendOnInit" SG_ 2149629952 PrkLtLeftOn 2;
BA_ "VNSigParkedVehicle" SG_ 2149629952 PrkLtLeftOn 1;
BA_ "SignalType" SG_ 2149629952 PrkLtLeftOn "BLN";
BA_ "SignalLongName" SG_ 2149629952 PrkLtLeftOn "Park Light Left On";
BA_ "VNSigAllNodes" SG_ 2149629952 PrkLtLeftOn 1;
BA_ "GenSigSendType" SG_ 2149629952 TrnSwAct 10;
BA_ "GenSigSendOnInit" SG_ 2149629952 TrnSwAct 1;
BA_ "SignalType" SG_ 2149629952 TrnSwAct "ENM";
BA_ "SignalLongName" SG_ 2149629952 TrnSwAct "Turn Switch Activation";
BA_ "VNSigAllNodes" SG_ 2149629952 TrnSwAct 1;
BA_ "GenSigSendType" SG_ 2149629952 PrkLtRightIO 10;
BA_ "GenSigSendOnInit" SG_ 2149629952 PrkLtRightIO 2;
BA_ "VNSigParkedVehicle" SG_ 2149629952 PrkLtRightIO 1;
BA_ "SignalType" SG_ 2149629952 PrkLtRightIO "BLN";
BA_ "SignalLongName" SG_ 2149629952 PrkLtRightIO "Park Light Right Indication On";
BA_ "VNSigAllNodes" SG_ 2149629952 PrkLtRightIO 1;
BA_ "GenSigSendType" SG_ 2149629952 MainLghtSw 10;
BA_ "GenSigSendOnInit" SG_ 2149629952 MainLghtSw 1;
BA_ "SignalType" SG_ 2149629952 MainLghtSw "ENM";
BA_ "SignalLongName" SG_ 2149629952 MainLghtSw "Main Light Switch";
BA_ "VNSigAllNodes" SG_ 2149629952 MainLghtSw 1;
BA_ "GenSigSendType" SG_ 2149629952 PrkLtLeftIO 10;
BA_ "GenSigSendOnInit" SG_ 2149629952 PrkLtLeftIO 2;
BA_ "VNSigParkedVehicle" SG_ 2149629952 PrkLtLeftIO 1;
BA_ "SignalType" SG_ 2149629952 PrkLtLeftIO "BLN";
BA_ "SignalLongName" SG_ 2149629952 PrkLtLeftIO "Park Light Left Indication On";
BA_ "VNSigAllNodes" SG_ 2149629952 PrkLtLeftIO 1;
BA_ "GenSigSendType" SG_ 2149629952 HazSwAtv 10;
BA_ "GenSigSendOnInit" SG_ 2149629952 HazSwAtv 1;
BA_ "VNSigParkedVehicle" SG_ 2149629952 HazSwAtv 1;
BA_ "SignalType" SG_ 2149629952 HazSwAtv "BLN";
BA_ "SignalLongName" SG_ 2149629952 HazSwAtv "Hazard Switch Active";
BA_ "VNSigAllNodes" SG_ 2149629952 HazSwAtv 1;
BA_ "GenSigSendType" SG_ 2149629952 HiBmIO 10;
BA_ "GenSigSendOnInit" SG_ 2149629952 HiBmIO 1;
BA_ "SignalType" SG_ 2149629952 HiBmIO "BLN";
BA_ "SignalLongName" SG_ 2149629952 HiBmIO "High Beam Indication On";
BA_ "VNSigAllNodes" SG_ 2149629952 HiBmIO 1;
BA_ "GenSigSendType" SG_ 2149629952 FrFgLtIO 10;
BA_ "GenSigSendOnInit" SG_ 2149629952 FrFgLtIO 1;
BA_ "SignalType" SG_ 2149629952 FrFgLtIO "BLN";
BA_ "SignalLongName" SG_ 2149629952 FrFgLtIO "Front Fog Light Indication On";
BA_ "VNSigAllNodes" SG_ 2149629952 FrFgLtIO 1;
BA_ "GenSigSendType" SG_ 2149629952 AutoLtsInactIO 10;
BA_ "SignalType" SG_ 2149629952 AutoLtsInactIO "BLN";
BA_ "SignalLongName" SG_ 2149629952 AutoLtsInactIO "Automatic Lights Inactive Indication On";
BA_ "VNSigAllNodes" SG_ 2149629952 AutoLtsInactIO 1;
BA_ "GenSigSendType" SG_ 2149629952 AutoLtsActIO 10;
BA_ "SignalType" SG_ 2149629952 AutoLtsActIO "BLN";
BA_ "SignalLongName" SG_ 2149629952 AutoLtsActIO "Automatic Lights Active Indication On";
BA_ "VNSigAllNodes" SG_ 2149629952 AutoLtsActIO 1;
BA_ "GenSigSendType" SG_ 2149629952 LftTrnLmpAtv 10;
BA_ "GenSigSendOnInit" SG_ 2149629952 LftTrnLmpAtv 1;
BA_ "VNSigParkedVehicle" SG_ 2149629952 LftTrnLmpAtv 1;
BA_ "SignalType" SG_ 2149629952 LftTrnLmpAtv "ENM";
BA_ "SignalLongName" SG_ 2149629952 LftTrnLmpAtv "Left Turn Lamp Active";
BA_ "VNSigAllNodes" SG_ 2149629952 LftTrnLmpAtv 1;
BA_ "GenSigSendType" SG_ 2149629952 RtTrnLmpAtv 10;
BA_ "GenSigSendOnInit" SG_ 2149629952 RtTrnLmpAtv 1;
BA_ "VNSigParkedVehicle" SG_ 2149629952 RtTrnLmpAtv 1;
BA_ "SignalType" SG_ 2149629952 RtTrnLmpAtv "ENM";
BA_ "SignalLongName" SG_ 2149629952 RtTrnLmpAtv "Right Turn Lamp Active";
BA_ "VNSigAllNodes" SG_ 2149629952 RtTrnLmpAtv 1;
BA_ "GenSigSendType" SG_ 2149629952 RevLmpAtv 10;
BA_ "GenSigSendOnInit" SG_ 2149629952 RevLmpAtv 1;
BA_ "SignalType" SG_ 2149629952 RevLmpAtv "BLN";
BA_ "SignalLongName" SG_ 2149629952 RevLmpAtv "Reversing Lamp";
BA_ "VNSigAllNodes" SG_ 2149629952 RevLmpAtv 1;
BA_ "GenSigSendType" SG_ 2149629952 HdlmpBmSelectStat 10;
BA_ "GenSigSendOnInit" SG_ 2149629952 HdlmpBmSelectStat 1;
BA_ "SignalType" SG_ 2149629952 HdlmpBmSelectStat "ENM";
BA_ "SignalLongName" SG_ 2149629952 HdlmpBmSelectStat "Headlamp Beam Select Status";
BA_ "VNSigAllNodes" SG_ 2149629952 HdlmpBmSelectStat 1;
BA_ "GenSigSendType" SG_ 2149629952 SrvlnceMdAct 10;
BA_ "SignalType" SG_ 2149629952 SrvlnceMdAct "BLN";
BA_ "SignalLongName" SG_ 2149629952 SrvlnceMdAct "Surveillance Mode Active";
BA_ "VNSigAllNodes" SG_ 2149629952 SrvlnceMdAct 1;
BA_ "GenSigSendType" SG_ 2149629952 RrFgLtIO 10;
BA_ "SignalType" SG_ 2149629952 RrFgLtIO "BLN";
BA_ "SignalLongName" SG_ 2149629952 RrFgLtIO "Rear Fog Light Indication On";
BA_ "VNSigAllNodes" SG_ 2149629952 RrFgLtIO 1;
BA_ "GenSigSendType" SG_ 2149629952 PrkLtIO 10;
BA_ "GenSigSendOnInit" SG_ 2149629952 PrkLtIO 2;
BA_ "VNSigParkedVehicle" SG_ 2149629952 PrkLtIO 1;
BA_ "SignalType" SG_ 2149629952 PrkLtIO "BLN";
BA_ "SignalLongName" SG_ 2149629952 PrkLtIO "Park Light Indication On";
BA_ "VNSigAllNodes" SG_ 2149629952 PrkLtIO 1;
BA_ "GenSigSendType" SG_ 2149629952 OtsdAmbtLtLvlStatV 10;
BA_ "SignalType" SG_ 2149629952 OtsdAmbtLtLvlStatV "ENM";
BA_ "SignalLongName" SG_ 2149629952 OtsdAmbtLtLvlStatV "Outside Ambient Light Level Status Validity";
BA_ "VNSigAllNodes" SG_ 2149629952 OtsdAmbtLtLvlStatV 1;
BA_ "GenSigSendType" SG_ 2149629952 OtsdAmbtLtLvlStat 10;
BA_ "SignalType" SG_ 2149629952 OtsdAmbtLtLvlStat "ENM";
BA_ "SignalLongName" SG_ 2149629952 OtsdAmbtLtLvlStat "Outside Ambient Light Level Status";
BA_ "VNSigAllNodes" SG_ 2149629952 OtsdAmbtLtLvlStat 1;
BA_ "GenSigSendType" SG_ 2149629952 RrFogLmpsAct 10;
BA_ "GenSigSendOnInit" SG_ 2149629952 RrFogLmpsAct 1;
BA_ "SignalType" SG_ 2149629952 RrFogLmpsAct "BLN";
BA_ "SignalLongName" SG_ 2149629952 RrFogLmpsAct "Rear Fog Lamps Active";
BA_ "VNSigAllNodes" SG_ 2149629952 RrFogLmpsAct 1;
BA_ "GenSigSendType" SG_ 2149629952 PrkngLtsAct 10;
BA_ "GenSigSendOnInit" SG_ 2149629952 PrkngLtsAct 1;
BA_ "VNSigParkedVehicle" SG_ 2149629952 PrkngLtsAct 1;
BA_ "SignalType" SG_ 2149629952 PrkngLtsAct "BLN";
BA_ "SignalLongName" SG_ 2149629952 PrkngLtsAct "Parking Lights Active";
BA_ "VNSigAllNodes" SG_ 2149629952 PrkngLtsAct 1;
BA_ "GenSigSendType" SG_ 2149629952 BrkLtsAtv 10;
BA_ "GenSigSendOnInit" SG_ 2149629952 BrkLtsAtv 1;
BA_ "SignalType" SG_ 2149629952 BrkLtsAtv "BLN";
BA_ "SignalLongName" SG_ 2149629952 BrkLtsAtv "Brake Lights Active";
BA_ "VNSigAllNodes" SG_ 2149629952 BrkLtsAtv 1;
BA_ "GenSigSendType" SG_ 2149629952 AutoBmSlctAllwd 10;
BA_ "GenSigSendOnInit" SG_ 2149629952 AutoBmSlctAllwd 2;
BA_ "SignalType" SG_ 2149629952 AutoBmSlctAllwd "BLN";
BA_ "SignalLongName" SG_ 2149629952 AutoBmSlctAllwd "Automatic Beam Select Allowed";
BA_ "VNSigAllNodes" SG_ 2149629952 AutoBmSlctAllwd 1;
BA_ "GenSigSendType" SG_ 2149629952 FlToPsSwAtv 10;
BA_ "SignalType" SG_ 2149629952 FlToPsSwAtv "BLN";
BA_ "SignalLongName" SG_ 2149629952 FlToPsSwAtv "Flash To Pass Switch Active";
BA_ "VNSigAllNodes" SG_ 2149629952 FlToPsSwAtv 1;
BA_ "GenSigSendType" SG_ 2149629952 DRLAct 10;
BA_ "SignalType" SG_ 2149629952 DRLAct "BLN";
BA_ "SignalLongName" SG_ 2149629952 DRLAct "Daytime Running Lamps Active";
BA_ "VNSigAllNodes" SG_ 2149629952 DRLAct 1;
BA_ "GenSigSendType" SG_ 2151047168 HdUpDspAnmtStat 10;
BA_ "SignalType" SG_ 2151047168 HdUpDspAnmtStat "ENM";
BA_ "SignalLongName" SG_ 2151047168 HdUpDspAnmtStat "Head Up Display Animation Status";
BA_ "VNSigAllNodes" SG_ 2151047168 HdUpDspAnmtStat 1;
BA_ "GenSigSendType" SG_ 2151047168 HUDActv 10;
BA_ "GenSigSendOnInit" SG_ 2151047168 HUDActv 1;
BA_ "VNSigInfotainment" SG_ 2151047168 HUDActv 1;
BA_ "SignalType" SG_ 2151047168 HUDActv "BLN";
BA_ "SignalLongName" SG_ 2151047168 HUDActv "Head Up Display Active";
BA_ "VNSigAllNodes" SG_ 2151047168 HUDActv 1;
BA_ "SignalType" SG_ 1618 DgnInf "UNM";
BA_ "SignalLongName" SG_ 1618 DgnInf "Diagnostic Information";
BA_ "VNSigDiagnostic" SG_ 1618 DgnInf 1;
BA_ "VNSigAllNodes" SG_ 1618 DgnInf 1;
BA_ "VNSigPrimaryTriggering" SG_ 1586 VectraSpcNWMgtD 1;
BA_ "VNSigRemoteDiagnostics" SG_ 1586 VectraSpcNWMgtD 1;
BA_ "VNSigInfotainment" SG_ 1586 VectraSpcNWMgtD 1;
BA_ "VNSigParkedVehicle" SG_ 1586 VectraSpcNWMgtD 1;
BA_ "VNSigIntermediate" SG_ 1586 VectraSpcNWMgtD 1;
BA_ "VNSigUnused_4" SG_ 1586 VectraSpcNWMgtD 1;
BA_ "SignalType" SG_ 1586 VectraSpcNWMgtD "UNM";
BA_ "SignalLongName" SG_ 1586 VectraSpcNWMgtD "Vectra Specific Network Management Data";
BA_ "VNSigDiagnostic" SG_ 1586 VectraSpcNWMgtD 1;
BA_ "VNSigAllNodes" SG_ 1586 VectraSpcNWMgtD 1;
BA_ "GenSigDeltaValue" SG_ 1362 DgnInf_LS552 1;
BA_ "GenSigSendType" SG_ 1362 DgnInf_LS552 12;
BA_ "SignalType" SG_ 1362 DgnInf_LS552 "UNM";
BA_ "SignalLongName" SG_ 1362 DgnInf_LS552 "Diagnostic Information LS552";
BA_ "VNSigDiagnostic" SG_ 1362 DgnInf_LS552 1;
BA_ "VNSigAllNodes" SG_ 1362 DgnInf_LS552 1;
BA_ "GenSigSendType" SG_ 2153947136 RmtRflshMdAct 10;
BA_ "VNSigRemoteDiagnostics" SG_ 2153947136 RmtRflshMdAct 1;
BA_ "SignalType" SG_ 2153947136 RmtRflshMdAct "BLN";
BA_ "SignalLongName" SG_ 2153947136 RmtRflshMdAct "Remote Reflash Mode Active";
BA_ "GenSigDeltaValue" SG_ 2158067712 TSDUAE_YCoOdntRq 1;
BA_ "GenSigSendType" SG_ 2158067712 TSDUAE_YCoOdntRq 12;
BA_ "SignalType" SG_ 2158067712 TSDUAE_YCoOdntRq "UNM";
BA_ "PacketOrder" SG_ 2158067712 TSDUAE_YCoOdntRq 5;
BA_ "SignalLongName" SG_ 2158067712 TSDUAE_YCoOdntRq "Touch Screen Display User Action Extended : Y_Coordinate Request";
BA_ "VNSigAllNodes" SG_ 2158067712 TSDUAE_YCoOdntRq 1;
BA_ "GenSigDeltaValue" SG_ 2158067712 TSDUAE_XCoOdntRq 1;
BA_ "GenSigSendType" SG_ 2158067712 TSDUAE_XCoOdntRq 12;
BA_ "SignalType" SG_ 2158067712 TSDUAE_XCoOdntRq "UNM";
BA_ "PacketOrder" SG_ 2158067712 TSDUAE_XCoOdntRq 4;
BA_ "SignalLongName" SG_ 2158067712 TSDUAE_XCoOdntRq "Touch Screen Display User Action Extended : X_Coordinate Request";
BA_ "VNSigAllNodes" SG_ 2158067712 TSDUAE_XCoOdntRq 1;
BA_ "GenSigSendType" SG_ 2158067712 TSDUAE_ScrnPrsdRq 10;
BA_ "SignalType" SG_ 2158067712 TSDUAE_ScrnPrsdRq "BLN";
BA_ "PacketOrder" SG_ 2158067712 TSDUAE_ScrnPrsdRq 1;
BA_ "SignalLongName" SG_ 2158067712 TSDUAE_ScrnPrsdRq "Touch Screen Display User Action Extended : Screen Press Requested";
BA_ "VNSigAllNodes" SG_ 2158067712 TSDUAE_ScrnPrsdRq 1;
BA_ "GenSigDeltaValue" SG_ 2158067712 TSDUAE_RotEnc 1;
BA_ "GenSigSendType" SG_ 2158067712 TSDUAE_RotEnc 12;
BA_ "SignalType" SG_ 2158067712 TSDUAE_RotEnc "SNM";
BA_ "PacketOrder" SG_ 2158067712 TSDUAE_RotEnc 6;
BA_ "SignalLongName" SG_ 2158067712 TSDUAE_RotEnc "Touch Screen Display User Action Extended : Rotary Encoder";
BA_ "VNSigAllNodes" SG_ 2158067712 TSDUAE_RotEnc 1;
BA_ "GenSigSendType" SG_ 2158067712 TSDUAE_RotBtnPsh 10;
BA_ "SignalType" SG_ 2158067712 TSDUAE_RotBtnPsh "BLN";
BA_ "PacketOrder" SG_ 2158067712 TSDUAE_RotBtnPsh 2;
BA_ "SignalLongName" SG_ 2158067712 TSDUAE_RotBtnPsh "Touch Screen Display User Action Extended : Rotary Button Push";
BA_ "VNSigAllNodes" SG_ 2158067712 TSDUAE_RotBtnPsh 1;
BA_ "GenSigSendType" SG_ 2158067712 TSDUAE_GrphStrkInfRq 10;
BA_ "SignalType" SG_ 2158067712 TSDUAE_GrphStrkInfRq "ENM";
BA_ "PacketOrder" SG_ 2158067712 TSDUAE_GrphStrkInfRq 3;
BA_ "SignalLongName" SG_ 2158067712 TSDUAE_GrphStrkInfRq "Touch Screen Display User Action Extended : Graphic Stroke Information Request";
BA_ "VNSigAllNodes" SG_ 2158067712 TSDUAE_GrphStrkInfRq 1;
BA_ "GenSigSendType" SG_ 2158051328 VidSrcUICntrlStat 10;
BA_ "GenSigSendOnInit" SG_ 2158051328 VidSrcUICntrlStat 1;
BA_ "SignalType" SG_ 2158051328 VidSrcUICntrlStat "ENM";
BA_ "SignalLongName" SG_ 2158051328 VidSrcUICntrlStat "Video Source User Interface Control Status";
BA_ "VNSigAllNodes" SG_ 2158051328 VidSrcUICntrlStat 1;
BA_ "GenSigSendType" SG_ 2158051328 VidMstrDsplyMd 10;
BA_ "GenSigSendOnInit" SG_ 2158051328 VidMstrDsplyMd 1;
BA_ "SignalType" SG_ 2158051328 VidMstrDsplyMd "ENM";
BA_ "SignalLongName" SG_ 2158051328 VidMstrDsplyMd "Video Master Display Mode";
BA_ "VNSigAllNodes" SG_ 2158051328 VidMstrDsplyMd 1;
BA_ "GenSigSendType" SG_ 2158051328 VidMstrSrcType 10;
BA_ "GenSigSendOnInit" SG_ 2158051328 VidMstrSrcType 1;
BA_ "SignalType" SG_ 2158051328 VidMstrSrcType "ENM";
BA_ "SignalLongName" SG_ 2158051328 VidMstrSrcType "Video Master Source Type";
BA_ "VNSigAllNodes" SG_ 2158051328 VidMstrSrcType 1;
BA_ "GenSigSendType" SG_ 2158051328 VidMstrArbCmd 10;
BA_ "SignalType" SG_ 2158051328 VidMstrArbCmd "ENM";
BA_ "SignalLongName" SG_ 2158051328 VidMstrArbCmd "Video Master Arbitration Command";
BA_ "VNSigAllNodes" SG_ 2158051328 VidMstrArbCmd 1;
BA_ "GenSigSendType" SG_ 2158051328 TVDspCmd 10;
BA_ "SignalType" SG_ 2158051328 TVDspCmd "ENM";
BA_ "SignalLongName" SG_ 2158051328 TVDspCmd "TV Display Command";
BA_ "VNSigAllNodes" SG_ 2158051328 TVDspCmd 1;
BA_ "GenSigDeltaValue" SG_ 2158051328 RmtRcvrTunVal 1;
BA_ "GenSigSendType" SG_ 2158051328 RmtRcvrTunVal 12;
BA_ "SignalType" SG_ 2158051328 RmtRcvrTunVal "SNM";
BA_ "SignalLongName" SG_ 2158051328 RmtRcvrTunVal "Remote Receiver Tune Value";
BA_ "VNSigAllNodes" SG_ 2158051328 RmtRcvrTunVal 1;
BA_ "GenSigSendType" SG_ 2158051328 RmtRcvrTunCmnd 10;
BA_ "SignalType" SG_ 2158051328 RmtRcvrTunCmnd "ENM";
BA_ "SignalLongName" SG_ 2158051328 RmtRcvrTunCmnd "Remote Receiver Tune Command";
BA_ "VNSigAllNodes" SG_ 2158051328 RmtRcvrTunCmnd 1;
BA_ "GenSigSendType" SG_ 2158051328 RemRcvrSrcInpCmd 10;
BA_ "SignalType" SG_ 2158051328 RemRcvrSrcInpCmd "ENM";
BA_ "SignalLongName" SG_ 2158051328 RemRcvrSrcInpCmd "Remote Receiver Source Input Command";
BA_ "VNSigAllNodes" SG_ 2158051328 RemRcvrSrcInpCmd 1;
BA_ "GenSigSendType" SG_ 2158034944 VidSrcCompFormatER 10;
BA_ "SignalType" SG_ 2158034944 VidSrcCompFormatER "ENM";
BA_ "SignalLongName" SG_ 2158034944 VidSrcCompFormatER "Video Source Composite Format Extended Range";
BA_ "VNSigAllNodes" SG_ 2158034944 VidSrcCompFormatER 1;
BA_ "GenSigSendType" SG_ 2158034944 CurntTVStnServc 10;
BA_ "SignalType" SG_ 2158034944 CurntTVStnServc "ENM";
BA_ "SignalLongName" SG_ 2158034944 CurntTVStnServc "Current TV Station Service";
BA_ "VNSigAllNodes" SG_ 2158034944 CurntTVStnServc 1;
BA_ "GenSigSendType" SG_ 2158034944 CurntTVStnQual 10;
BA_ "SignalType" SG_ 2158034944 CurntTVStnQual "ENM";
BA_ "SignalLongName" SG_ 2158034944 CurntTVStnQual "Current TV Station Quality";
BA_ "VNSigAllNodes" SG_ 2158034944 CurntTVStnQual 1;
BA_ "GenSigSendType" SG_ 2158034944 VidSrcType 10;
BA_ "SignalType" SG_ 2158034944 VidSrcType "ENM";
BA_ "SignalLongName" SG_ 2158034944 VidSrcType "Video Source Type";
BA_ "VNSigAllNodes" SG_ 2158034944 VidSrcType 1;
BA_ "GenSigSendType" SG_ 2158034944 VidSrcStatCode 10;
BA_ "SignalType" SG_ 2158034944 VidSrcStatCode "ENM";
BA_ "SignalLongName" SG_ 2158034944 VidSrcStatCode "Video Source Status Code";
BA_ "VNSigAllNodes" SG_ 2158034944 VidSrcStatCode 1;
BA_ "GenSigSendType" SG_ 2158034944 TVTunerPres 10;
BA_ "SignalType" SG_ 2158034944 TVTunerPres "BLN";
BA_ "SignalLongName" SG_ 2158034944 TVTunerPres "Television Tuner Present";
BA_ "VNSigAllNodes" SG_ 2158034944 TVTunerPres 1;
BA_ "GenSigSendType" SG_ 2158034944 RmtRcvrTunStat 10;
BA_ "SignalType" SG_ 2158034944 RmtRcvrTunStat "ENM";
BA_ "SignalLongName" SG_ 2158034944 RmtRcvrTunStat "Remote Receiver Tuning Status";
BA_ "VNSigAllNodes" SG_ 2158034944 RmtRcvrTunStat 1;
BA_ "GenSigSendType" SG_ 2158034944 RemRcvrSrcInpStat 10;
BA_ "SignalType" SG_ 2158034944 RemRcvrSrcInpStat "ENM";
BA_ "SignalLongName" SG_ 2158034944 RemRcvrSrcInpStat "Remote Receiver Source Input Status";
BA_ "VNSigAllNodes" SG_ 2158034944 RemRcvrSrcInpStat 1;
BA_ "GenSigDeltaValue" SG_ 2158034944 RmtRcvrPrgrmServID 1;
BA_ "GenSigSendType" SG_ 2158034944 RmtRcvrPrgrmServID 12;
BA_ "SignalType" SG_ 2158034944 RmtRcvrPrgrmServID "UNM";
BA_ "SignalLongName" SG_ 2158034944 RmtRcvrPrgrmServID "Remote Receiver Program Service ID";
BA_ "VNSigAllNodes" SG_ 2158034944 RmtRcvrPrgrmServID 1;
BA_ "GenSigSendType" SG_ 2158034944 RmtRecvtDataTyp 10;
BA_ "SignalType" SG_ 2158034944 RmtRecvtDataTyp "ENM";
BA_ "SignalLongName" SG_ 2158034944 RmtRecvtDataTyp "Remote Receiver Data Type";
BA_ "VNSigAllNodes" SG_ 2158034944 RmtRecvtDataTyp 1;
BA_ "GenSigSendType" SG_ 2158034944 RmtRcvrCmndStat 10;
BA_ "SignalType" SG_ 2158034944 RmtRcvrCmndStat "ENM";
BA_ "SignalLongName" SG_ 2158034944 RmtRcvrCmndStat "Remote Receiver Command Status";
BA_ "VNSigAllNodes" SG_ 2158034944 RmtRcvrCmndStat 1;
BA_ "GenSigSendType" SG_ 2158018560 TVStatNmeChar1_8 10;
BA_ "SignalType" SG_ 2158018560 TVStatNmeChar1_8 "ASC";
BA_ "SignalLongName" SG_ 2158018560 TVStatNmeChar1_8 "TV Station Name Character 1-8";
BA_ "VNSigAllNodes" SG_ 2158018560 TVStatNmeChar1_8 1;
BA_ "GenSigSendType" SG_ 2154627072 LgclAVChnl_368 10;
BA_ "SignalType" SG_ 2154627072 LgclAVChnl_368 "ENM";
BA_ "SignalLongName" SG_ 2154627072 LgclAVChnl_368 "Logical AV Channel";
BA_ "VNSigAllNodes" SG_ 2154627072 LgclAVChnl_368 1;
BA_ "GenSigSendType" SG_ 2154627072 AudMstrSrcTyp 10;
BA_ "VNSigInfotainment" SG_ 2154627072 AudMstrSrcTyp 1;
BA_ "SignalType" SG_ 2154627072 AudMstrSrcTyp "ENM";
BA_ "SignalLongName" SG_ 2154627072 AudMstrSrcTyp "Audio Master Source Type";
BA_ "VNSigAllNodes" SG_ 2154627072 AudMstrSrcTyp 1;
BA_ "GenSigSendType" SG_ 2154627072 AudMstrChnnlTyp 10;
BA_ "VNSigInfotainment" SG_ 2154627072 AudMstrChnnlTyp 1;
BA_ "SignalType" SG_ 2154627072 AudMstrChnnlTyp "ENM";
BA_ "SignalLongName" SG_ 2154627072 AudMstrChnnlTyp "Audio Master Channel Type";
BA_ "VNSigAllNodes" SG_ 2154627072 AudMstrChnnlTyp 1;
BA_ "GenSigSendType" SG_ 2154627072 AudMstrArbCom 10;
BA_ "VNSigInfotainment" SG_ 2154627072 AudMstrArbCom 1;
BA_ "SignalType" SG_ 2154627072 AudMstrArbCom "ENM";
BA_ "SignalLongName" SG_ 2154627072 AudMstrArbCom "Audio Master Arbitration Command";
BA_ "VNSigAllNodes" SG_ 2154627072 AudMstrArbCom 1;
BA_ "GenSigSendType" SG_ 2154692608 LgclAVChnl 10;
BA_ "SignalType" SG_ 2154692608 LgclAVChnl "ENM";
BA_ "SignalLongName" SG_ 2154692608 LgclAVChnl "Logical AV Channel";
BA_ "VNSigAllNodes" SG_ 2154692608 LgclAVChnl 1;
BA_ "GenSigSendType" SG_ 2154692608 ASSAudSrcStatCode 10;
BA_ "VNSigInfotainment" SG_ 2154692608 ASSAudSrcStatCode 1;
BA_ "SignalType" SG_ 2154692608 ASSAudSrcStatCode "ENM";
BA_ "PacketOrder" SG_ 2154692608 ASSAudSrcStatCode 3;
BA_ "SignalLongName" SG_ 2154692608 ASSAudSrcStatCode "Audio Source Status : Audio Source Status Code";
BA_ "VNSigAllNodes" SG_ 2154692608 ASSAudSrcStatCode 1;
BA_ "GenSigSendType" SG_ 2154692608 ASSAudSrcChType 10;
BA_ "VNSigInfotainment" SG_ 2154692608 ASSAudSrcChType 1;
BA_ "SignalType" SG_ 2154692608 ASSAudSrcChType "ENM";
BA_ "PacketOrder" SG_ 2154692608 ASSAudSrcChType 2;
BA_ "SignalLongName" SG_ 2154692608 ASSAudSrcChType "Audio Source Status : Audio Source Channel Type";
BA_ "VNSigAllNodes" SG_ 2154692608 ASSAudSrcChType 1;
BA_ "GenSigSendType" SG_ 2154692608 ASSAudSrcType 10;
BA_ "VNSigInfotainment" SG_ 2154692608 ASSAudSrcType 1;
BA_ "SignalType" SG_ 2154692608 ASSAudSrcType "ENM";
BA_ "PacketOrder" SG_ 2154692608 ASSAudSrcType 1;
BA_ "SignalLongName" SG_ 2154692608 ASSAudSrcType "Audio Source Status : Audio Source Type";
BA_ "VNSigAllNodes" SG_ 2154692608 ASSAudSrcType 1;
BA_ "SignalType" SG_ 1604 DgnInf "UNM";
BA_ "SignalLongName" SG_ 1604 DgnInf "Diagnostic Information";
BA_ "VNSigDiagnostic" SG_ 1604 DgnInf 1;
BA_ "VNSigAllNodes" SG_ 1604 DgnInf 1;
BA_ "GenSigDeltaValue" SG_ 1348 DgnInf_LS544 1;
BA_ "GenSigSendType" SG_ 1348 DgnInf_LS544 12;
BA_ "SignalType" SG_ 1348 DgnInf_LS544 "UNM";
BA_ "SignalLongName" SG_ 1348 DgnInf_LS544 "Diagnostic Information LS544";
BA_ "VNSigDiagnostic" SG_ 1348 DgnInf_LS544 1;
BA_ "VNSigAllNodes" SG_ 1348 DgnInf_LS544 1;
BA_ "VNSigPrimaryTriggering" SG_ 1572 VectraSpcNWMgtD 1;
BA_ "VNSigRemoteDiagnostics" SG_ 1572 VectraSpcNWMgtD 1;
BA_ "VNSigInfotainment" SG_ 1572 VectraSpcNWMgtD 1;
BA_ "VNSigParkedVehicle" SG_ 1572 VectraSpcNWMgtD 1;
BA_ "VNSigIntermediate" SG_ 1572 VectraSpcNWMgtD 1;
BA_ "VNSigUnused_4" SG_ 1572 VectraSpcNWMgtD 1;
BA_ "SignalType" SG_ 1572 VectraSpcNWMgtD "UNM";
BA_ "SignalLongName" SG_ 1572 VectraSpcNWMgtD "Vectra Specific Network Management Data";
BA_ "VNSigDiagnostic" SG_ 1572 VectraSpcNWMgtD 1;
BA_ "VNSigAllNodes" SG_ 1572 VectraSpcNWMgtD 1;
BA_ "SignalType" SG_ 1620 DgnInf "UNM";
BA_ "SignalLongName" SG_ 1620 DgnInf "Diagnostic Information";
BA_ "VNSigDiagnostic" SG_ 1620 DgnInf 1;
BA_ "VNSigAllNodes" SG_ 1620 DgnInf 1;
BA_ "VNSigPrimaryTriggering" SG_ 1588 VectraSpcNWMgtD 1;
BA_ "VNSigRemoteDiagnostics" SG_ 1588 VectraSpcNWMgtD 1;
BA_ "VNSigInfotainment" SG_ 1588 VectraSpcNWMgtD 1;
BA_ "VNSigParkedVehicle" SG_ 1588 VectraSpcNWMgtD 1;
BA_ "VNSigIntermediate" SG_ 1588 VectraSpcNWMgtD 1;
BA_ "VNSigUnused_4" SG_ 1588 VectraSpcNWMgtD 1;
BA_ "SignalType" SG_ 1588 VectraSpcNWMgtD "UNM";
BA_ "SignalLongName" SG_ 1588 VectraSpcNWMgtD "Vectra Specific Network Management Data";
BA_ "VNSigDiagnostic" SG_ 1588 VectraSpcNWMgtD 1;
BA_ "VNSigAllNodes" SG_ 1588 VectraSpcNWMgtD 1;
BA_ "GenSigDeltaValue" SG_ 1364 DgnInf_LS554 1;
BA_ "GenSigSendType" SG_ 1364 DgnInf_LS554 12;
BA_ "SignalType" SG_ 1364 DgnInf_LS554 "UNM";
BA_ "SignalLongName" SG_ 1364 DgnInf_LS554 "Diagnostic Information LS554";
BA_ "VNSigDiagnostic" SG_ 1364 DgnInf_LS554 1;
BA_ "VNSigAllNodes" SG_ 1364 DgnInf_LS554 1;
BA_ "GenSigSendType" SG_ 2153775104 DTCI_DTCFaultType 10;
BA_ "SignalType" SG_ 2153775104 DTCI_DTCFaultType "ENM";
BA_ "PacketOrder" SG_ 2153775104 DTCI_DTCFaultType 20;
BA_ "SignalLongName" SG_ 2153775104 DTCI_DTCFaultType "Diagnostic Trouble Code Information Extended : Diagnostic Trouble Code Fault Type";
BA_ "VNSigAllNodes" SG_ 2153775104 DTCI_DTCFaultType 1;
BA_ "GenSigSendType" SG_ 2153775104 DTCI_CodeSupported 10;
BA_ "SignalType" SG_ 2153775104 DTCI_CodeSupported "BLN";
BA_ "PacketOrder" SG_ 2153775104 DTCI_CodeSupported 19;
BA_ "SignalLongName" SG_ 2153775104 DTCI_CodeSupported "Diagnostic Trouble Code Information Extended : Code Supported";
BA_ "VNSigAllNodes" SG_ 2153775104 DTCI_CodeSupported 1;
BA_ "GenSigSendType" SG_ 2153775104 DTCI_CurrentStatus 10;
BA_ "SignalType" SG_ 2153775104 DTCI_CurrentStatus "BLN";
BA_ "PacketOrder" SG_ 2153775104 DTCI_CurrentStatus 18;
BA_ "SignalLongName" SG_ 2153775104 DTCI_CurrentStatus "Diagnostic Trouble Code Information Extended : Current Status";
BA_ "VNSigAllNodes" SG_ 2153775104 DTCI_CurrentStatus 1;
BA_ "GenSigSendType" SG_ 2153775104 DTCI_TstNPsdCdClrdSt 10;
BA_ "SignalType" SG_ 2153775104 DTCI_TstNPsdCdClrdSt "BLN";
BA_ "PacketOrder" SG_ 2153775104 DTCI_TstNPsdCdClrdSt 17;
BA_ "SignalLongName" SG_ 2153775104 DTCI_TstNPsdCdClrdSt "Diagnostic Trouble Code Information Extended : Test Not Passed Since Code Cleared Status";
BA_ "VNSigAllNodes" SG_ 2153775104 DTCI_TstNPsdCdClrdSt 1;
BA_ "GenSigSendType" SG_ 2153775104 DTCI_TstFldCdClrdStat 10;
BA_ "SignalType" SG_ 2153775104 DTCI_TstFldCdClrdStat "BLN";
BA_ "PacketOrder" SG_ 2153775104 DTCI_TstFldCdClrdStat 16;
BA_ "SignalLongName" SG_ 2153775104 DTCI_TstFldCdClrdStat "Diagnostic Trouble Code Information Extended : Test Failed Since Code Cleared Status";
BA_ "VNSigAllNodes" SG_ 2153775104 DTCI_TstFldCdClrdStat 1;
BA_ "GenSigSendType" SG_ 2153775104 DTCI_HistStat 10;
BA_ "SignalType" SG_ 2153775104 DTCI_HistStat "BLN";
BA_ "PacketOrder" SG_ 2153775104 DTCI_HistStat 15;
BA_ "SignalLongName" SG_ 2153775104 DTCI_HistStat "Diagnostic Trouble Code Information Extended : History Status";
BA_ "VNSigAllNodes" SG_ 2153775104 DTCI_HistStat 1;
BA_ "GenSigSendType" SG_ 2153775104 DTCI_TstNPsdPwrUpSt 10;
BA_ "SignalType" SG_ 2153775104 DTCI_TstNPsdPwrUpSt "BLN";
BA_ "PacketOrder" SG_ 2153775104 DTCI_TstNPsdPwrUpSt 14;
BA_ "SignalLongName" SG_ 2153775104 DTCI_TstNPsdPwrUpSt "Diagnostic Trouble Code Information Extended : Test Not Passed Since Power Up Status";
BA_ "VNSigAllNodes" SG_ 2153775104 DTCI_TstNPsdPwrUpSt 1;
BA_ "GenSigSendType" SG_ 2153775104 DTCI_TstFldPwrUpSt 10;
BA_ "SignalType" SG_ 2153775104 DTCI_TstFldPwrUpSt "BLN";
BA_ "PacketOrder" SG_ 2153775104 DTCI_TstFldPwrUpSt 13;
BA_ "SignalLongName" SG_ 2153775104 DTCI_TstFldPwrUpSt "Diagnostic Trouble Code Information Extended : Test Failed Since Power Up Status";
BA_ "VNSigAllNodes" SG_ 2153775104 DTCI_TstFldPwrUpSt 1;
BA_ "GenSigSendType" SG_ 2153775104 DTCI_WrnIndRqdSt 10;
BA_ "SignalType" SG_ 2153775104 DTCI_WrnIndRqdSt "BLN";
BA_ "PacketOrder" SG_ 2153775104 DTCI_WrnIndRqdSt 12;
BA_ "SignalLongName" SG_ 2153775104 DTCI_WrnIndRqdSt "Diagnostic Trouble Code Information Extended : Warning Indicator Requested Status";
BA_ "VNSigAllNodes" SG_ 2153775104 DTCI_WrnIndRqdSt 1;
BA_ "GenSigSendType" SG_ 2153775104 DTCI_DTCFailType 12;
BA_ "SignalType" SG_ 2153775104 DTCI_DTCFailType "UNM";
BA_ "PacketOrder" SG_ 2153775104 DTCI_DTCFailType 11;
BA_ "SignalLongName" SG_ 2153775104 DTCI_DTCFailType "Diagnostic Trouble Code Information Extended : Diagnostic Trouble Code Failure Type";
BA_ "VNSigAllNodes" SG_ 2153775104 DTCI_DTCFailType 1;
BA_ "GenSigSendType" SG_ 2153775104 DTCI_DTCNumber 12;
BA_ "SignalType" SG_ 2153775104 DTCI_DTCNumber "UNM";
BA_ "PacketOrder" SG_ 2153775104 DTCI_DTCNumber 10;
BA_ "SignalLongName" SG_ 2153775104 DTCI_DTCNumber "Diagnostic Trouble Code Information Extended : Diagnostic Trouble Code Number";
BA_ "VNSigAllNodes" SG_ 2153775104 DTCI_DTCNumber 1;
BA_ "GenSigSendType" SG_ 2153775104 DTCI_DTCSource 12;
BA_ "SignalType" SG_ 2153775104 DTCI_DTCSource "UNM";
BA_ "PacketOrder" SG_ 2153775104 DTCI_DTCSource 9;
BA_ "SignalLongName" SG_ 2153775104 DTCI_DTCSource "Diagnostic Trouble Code Information Extended : Diagnostic Trouble Code Source";
BA_ "VNSigAllNodes" SG_ 2153775104 DTCI_DTCSource 1;
BA_ "GenSigSendType" SG_ 2153775104 DTCI_DTCTriggered 10;
BA_ "SignalType" SG_ 2153775104 DTCI_DTCTriggered "BLN";
BA_ "PacketOrder" SG_ 2153775104 DTCI_DTCTriggered 8;
BA_ "SignalLongName" SG_ 2153775104 DTCI_DTCTriggered "Diagnostic Trouble Code Information Extended : Diagnostic Trouble Code Triggered";
BA_ "VNSigAllNodes" SG_ 2153775104 DTCI_DTCTriggered 1;
BA_ "GenSigSendType" SG_ 2153775104 DTCIUnused7 10;
BA_ "SignalType" SG_ 2153775104 DTCIUnused7 "BLN";
BA_ "PacketOrder" SG_ 2153775104 DTCIUnused7 1;
BA_ "SignalLongName" SG_ 2153775104 DTCIUnused7 "Diagnostic Trouble Code Information Extended : Unused 7";
BA_ "VNSigAllNodes" SG_ 2153775104 DTCIUnused7 1;
BA_ "GenSigSendType" SG_ 2153775104 DTCIUnused6 10;
BA_ "SignalType" SG_ 2153775104 DTCIUnused6 "BLN";
BA_ "PacketOrder" SG_ 2153775104 DTCIUnused6 2;
BA_ "SignalLongName" SG_ 2153775104 DTCIUnused6 "Diagnostic Trouble Code Information Extended : Unused 6";
BA_ "VNSigAllNodes" SG_ 2153775104 DTCIUnused6 1;
BA_ "GenSigSendType" SG_ 2153775104 DTCIUnused5 10;
BA_ "SignalType" SG_ 2153775104 DTCIUnused5 "BLN";
BA_ "PacketOrder" SG_ 2153775104 DTCIUnused5 3;
BA_ "SignalLongName" SG_ 2153775104 DTCIUnused5 "Diagnostic Trouble Code Information Extended : Unused 5";
BA_ "VNSigAllNodes" SG_ 2153775104 DTCIUnused5 1;
BA_ "GenSigSendType" SG_ 2153775104 DTCIUnused4 10;
BA_ "SignalType" SG_ 2153775104 DTCIUnused4 "BLN";
BA_ "PacketOrder" SG_ 2153775104 DTCIUnused4 4;
BA_ "SignalLongName" SG_ 2153775104 DTCIUnused4 "Diagnostic Trouble Code Information Extended : Unused 4";
BA_ "VNSigAllNodes" SG_ 2153775104 DTCIUnused4 1;
BA_ "GenSigSendType" SG_ 2153775104 DTCIUnused3 10;
BA_ "SignalType" SG_ 2153775104 DTCIUnused3 "BLN";
BA_ "PacketOrder" SG_ 2153775104 DTCIUnused3 5;
BA_ "SignalLongName" SG_ 2153775104 DTCIUnused3 "Diagnostic Trouble Code Information Extended : Unused 3";
BA_ "VNSigAllNodes" SG_ 2153775104 DTCIUnused3 1;
BA_ "GenSigSendType" SG_ 2153775104 DTCIUnused2 10;
BA_ "SignalType" SG_ 2153775104 DTCIUnused2 "BLN";
BA_ "PacketOrder" SG_ 2153775104 DTCIUnused2 6;
BA_ "SignalLongName" SG_ 2153775104 DTCIUnused2 "Diagnostic Trouble Code Information Extended : Unused 2";
BA_ "VNSigAllNodes" SG_ 2153775104 DTCIUnused2 1;
BA_ "GenSigSendType" SG_ 2153775104 DTCIUnused1 10;
BA_ "SignalType" SG_ 2153775104 DTCIUnused1 "BLN";
BA_ "PacketOrder" SG_ 2153775104 DTCIUnused1 7;
BA_ "SignalLongName" SG_ 2153775104 DTCIUnused1 "Diagnostic Trouble Code Information Extended : Unused 1";
BA_ "VNSigAllNodes" SG_ 2153775104 DTCIUnused1 1;
BA_ "GenSigSendType" SG_ 2150703104 AudSysVNoisCompPres 10;
BA_ "GenSigSendOnInit" SG_ 2150703104 AudSysVNoisCompPres 1;
BA_ "VNSigInfotainment" SG_ 2150703104 AudSysVNoisCompPres 1;
BA_ "SignalType" SG_ 2150703104 AudSysVNoisCompPres "BLN";
BA_ "SignalLongName" SG_ 2150703104 AudSysVNoisCompPres "Audio System Vehicle Noise Compression Present";
BA_ "VNSigAllNodes" SG_ 2150703104 AudSysVNoisCompPres 1;
BA_ "GenSigSendType" SG_ 2150703104 AudSysSurSndSysPres 10;
BA_ "GenSigSendOnInit" SG_ 2150703104 AudSysSurSndSysPres 1;
BA_ "VNSigInfotainment" SG_ 2150703104 AudSysSurSndSysPres 1;
BA_ "SignalType" SG_ 2150703104 AudSysSurSndSysPres "BLN";
BA_ "SignalLongName" SG_ 2150703104 AudSysSurSndSysPres "Audio System Surround Sound System Present";
BA_ "VNSigAllNodes" SG_ 2150703104 AudSysSurSndSysPres 1;
BA_ "GenSigSendType" SG_ 2150703104 AudSysDigSigProcPres 10;
BA_ "GenSigSendOnInit" SG_ 2150703104 AudSysDigSigProcPres 1;
BA_ "VNSigInfotainment" SG_ 2150703104 AudSysDigSigProcPres 1;
BA_ "SignalType" SG_ 2150703104 AudSysDigSigProcPres "BLN";
BA_ "SignalLongName" SG_ 2150703104 AudSysDigSigProcPres "Audio System Digital Signal Processing Present";
BA_ "VNSigAllNodes" SG_ 2150703104 AudSysDigSigProcPres 1;
BA_ "GenSigSendType" SG_ 2151718912 ChmVolSt 10;
BA_ "SignalType" SG_ 2151718912 ChmVolSt "ENM";
BA_ "SignalLongName" SG_ 2151718912 ChmVolSt "Chime Volume Status";
BA_ "VNSigAllNodes" SG_ 2151718912 ChmVolSt 1;
BA_ "GenSigSendType" SG_ 2151718912 ChmAct 10;
BA_ "GenSigSendOnInit" SG_ 2151718912 ChmAct 1;
BA_ "VNSigInfotainment" SG_ 2151718912 ChmAct 1;
BA_ "VNSigIntermediate" SG_ 2151718912 ChmAct 1;
BA_ "SignalType" SG_ 2151718912 ChmAct "BLN";
BA_ "SignalLongName" SG_ 2151718912 ChmAct "Chime Active";
BA_ "VNSigAllNodes" SG_ 2151718912 ChmAct 1;
BA_ "GenSigSendType" SG_ 2155020288 ChVolRq2 10;
BA_ "SignalType" SG_ 2155020288 ChVolRq2 "ENM";
BA_ "SignalLongName" SG_ 2155020288 ChVolRq2 "Chime Volume Request 2";
BA_ "VNSigAllNodes" SG_ 2155020288 ChVolRq2 1;
BA_ "GenSigSendType" SG_ 2155020288 LngSelExt 10;
BA_ "GenSigSendOnInit" SG_ 2155020288 LngSelExt 1;
BA_ "VNSigInfotainment" SG_ 2155020288 LngSelExt 1;
BA_ "SignalType" SG_ 2155020288 LngSelExt "ENM";
BA_ "SignalLongName" SG_ 2155020288 LngSelExt "Language Selection Extended";
BA_ "VNSigAllNodes" SG_ 2155020288 LngSelExt 1;
BA_ "GenSigSendType" SG_ 2151677952 SndLocRtRr 10;
BA_ "VNSigInfotainment" SG_ 2151677952 SndLocRtRr 1;
BA_ "VNSigIntermediate" SG_ 2151677952 SndLocRtRr 1;
BA_ "SignalType" SG_ 2151677952 SndLocRtRr "BLN";
BA_ "PacketOrder" SG_ 2151677952 SndLocRtRr 4;
BA_ "SignalLongName" SG_ 2151677952 SndLocRtRr "Sound Location : Right Rear";
BA_ "VNSigAllNodes" SG_ 2151677952 SndLocRtRr 1;
BA_ "GenSigSendType" SG_ 2151677952 SndLocLftRr 10;
BA_ "VNSigInfotainment" SG_ 2151677952 SndLocLftRr 1;
BA_ "VNSigIntermediate" SG_ 2151677952 SndLocLftRr 1;
BA_ "SignalType" SG_ 2151677952 SndLocLftRr "BLN";
BA_ "PacketOrder" SG_ 2151677952 SndLocLftRr 3;
BA_ "SignalLongName" SG_ 2151677952 SndLocLftRr "Sound Location : Left Rear";
BA_ "VNSigAllNodes" SG_ 2151677952 SndLocLftRr 1;
BA_ "GenSigSendType" SG_ 2151677952 SndLocPasFr 10;
BA_ "VNSigInfotainment" SG_ 2151677952 SndLocPasFr 1;
BA_ "VNSigIntermediate" SG_ 2151677952 SndLocPasFr 1;
BA_ "SignalType" SG_ 2151677952 SndLocPasFr "BLN";
BA_ "PacketOrder" SG_ 2151677952 SndLocPasFr 2;
BA_ "SignalLongName" SG_ 2151677952 SndLocPasFr "Sound Location : Passenger Front";
BA_ "VNSigAllNodes" SG_ 2151677952 SndLocPasFr 1;
BA_ "GenSigSendType" SG_ 2151677952 SndLocDrFr 10;
BA_ "VNSigInfotainment" SG_ 2151677952 SndLocDrFr 1;
BA_ "VNSigIntermediate" SG_ 2151677952 SndLocDrFr 1;
BA_ "SignalType" SG_ 2151677952 SndLocDrFr "BLN";
BA_ "PacketOrder" SG_ 2151677952 SndLocDrFr 1;
BA_ "SignalLongName" SG_ 2151677952 SndLocDrFr "Sound Location : Driver Front";
BA_ "VNSigAllNodes" SG_ 2151677952 SndLocDrFr 1;
BA_ "GenSigDeltaValue" SG_ 2151677952 SC_SndDutCyc 1;
BA_ "GenSigSendType" SG_ 2151677952 SC_SndDutCyc 12;
BA_ "VNSigInfotainment" SG_ 2151677952 SC_SndDutCyc 1;
BA_ "VNSigIntermediate" SG_ 2151677952 SC_SndDutCyc 1;
BA_ "SignalType" SG_ 2151677952 SC_SndDutCyc "UNM";
BA_ "PacketOrder" SG_ 2151677952 SC_SndDutCyc 4;
BA_ "SignalLongName" SG_ 2151677952 SC_SndDutCyc "Sound Characteristics : Sound Duty Cycle";
BA_ "VNSigAllNodes" SG_ 2151677952 SC_SndDutCyc 1;
BA_ "GenSigDeltaValue" SG_ 2151677952 SC_NmofRp 1;
BA_ "GenSigSendType" SG_ 2151677952 SC_NmofRp 12;
BA_ "VNSigInfotainment" SG_ 2151677952 SC_NmofRp 1;
BA_ "VNSigIntermediate" SG_ 2151677952 SC_NmofRp 1;
BA_ "SignalType" SG_ 2151677952 SC_NmofRp "UNM";
BA_ "PacketOrder" SG_ 2151677952 SC_NmofRp 3;
BA_ "SignalLongName" SG_ 2151677952 SC_NmofRp "Sound Characteristics : Number of Repetitions";
BA_ "VNSigAllNodes" SG_ 2151677952 SC_NmofRp 1;
BA_ "GenSigDeltaValue" SG_ 2151677952 SC_SndCdnPrd 1;
BA_ "GenSigSendType" SG_ 2151677952 SC_SndCdnPrd 12;
BA_ "VNSigInfotainment" SG_ 2151677952 SC_SndCdnPrd 1;
BA_ "VNSigIntermediate" SG_ 2151677952 SC_SndCdnPrd 1;
BA_ "SignalType" SG_ 2151677952 SC_SndCdnPrd "UNM";
BA_ "PacketOrder" SG_ 2151677952 SC_SndCdnPrd 2;
BA_ "SignalLongName" SG_ 2151677952 SC_SndCdnPrd "Sound Characteristics : Sound Cadence Period";
BA_ "VNSigAllNodes" SG_ 2151677952 SC_SndCdnPrd 1;
BA_ "GenSigSendType" SG_ 2151677952 SC_SndTne 10;
BA_ "VNSigInfotainment" SG_ 2151677952 SC_SndTne 1;
BA_ "VNSigIntermediate" SG_ 2151677952 SC_SndTne 1;
BA_ "SignalType" SG_ 2151677952 SC_SndTne "ENM";
BA_ "PacketOrder" SG_ 2151677952 SC_SndTne 1;
BA_ "SignalLongName" SG_ 2151677952 SC_SndTne "Sound Characteristics : Sound Tone";
BA_ "VNSigAllNodes" SG_ 2151677952 SC_SndTne 1;
BA_ "GenSigDeltaValue" SG_ 2151677952 SndPriority 1;
BA_ "GenSigSendType" SG_ 2151677952 SndPriority 12;
BA_ "VNSigInfotainment" SG_ 2151677952 SndPriority 1;
BA_ "VNSigIntermediate" SG_ 2151677952 SndPriority 1;
BA_ "SignalType" SG_ 2151677952 SndPriority "UNM";
BA_ "SignalLongName" SG_ 2151677952 SndPriority "Sound Priority";
BA_ "VNSigAllNodes" SG_ 2151677952 SndPriority 1;
BA_ "GenSigSendType" SG_ 2149851136 KylsStrtAuthRq 10;
BA_ "SignalType" SG_ 2149851136 KylsStrtAuthRq "BLN";
BA_ "SignalLongName" SG_ 2149851136 KylsStrtAuthRq "Keyless Start Authentication Requested";
BA_ "VNSigAllNodes" SG_ 2149851136 KylsStrtAuthRq 1;
BA_ "GenSigSendType" SG_ 2149851136 SysPwrMd 10;
BA_ "GenSigSendOnInit" SG_ 2149851136 SysPwrMd 2;
BA_ "VNSigInfotainment" SG_ 2149851136 SysPwrMd 1;
BA_ "VNSigParkedVehicle" SG_ 2149851136 SysPwrMd 1;
BA_ "VNSigIntermediate" SG_ 2149851136 SysPwrMd 1;
BA_ "SignalType" SG_ 2149851136 SysPwrMd "ENM";
BA_ "SignalLongName" SG_ 2149851136 SysPwrMd "System Power Mode";
BA_ "VNSigAllNodes" SG_ 2149851136 SysPwrMd 1;
BA_ "GenSigSendType" SG_ 2149851136 SysPwrMdV 10;
BA_ "VNSigInfotainment" SG_ 2149851136 SysPwrMdV 1;
BA_ "VNSigParkedVehicle" SG_ 2149851136 SysPwrMdV 1;
BA_ "VNSigIntermediate" SG_ 2149851136 SysPwrMdV 1;
BA_ "SignalType" SG_ 2149851136 SysPwrMdV "ENM";
BA_ "SignalLongName" SG_ 2149851136 SysPwrMdV "System Power Mode Validity";
BA_ "VNSigAllNodes" SG_ 2149851136 SysPwrMdV 1;
BA_ "GenSigSendType" SG_ 2149859328 SysBkUpPwrMdV 10;
BA_ "VNSigInfotainment" SG_ 2149859328 SysBkUpPwrMdV 1;
BA_ "VNSigParkedVehicle" SG_ 2149859328 SysBkUpPwrMdV 1;
BA_ "VNSigIntermediate" SG_ 2149859328 SysBkUpPwrMdV 1;
BA_ "SignalType" SG_ 2149859328 SysBkUpPwrMdV "ENM";
BA_ "SignalLongName" SG_ 2149859328 SysBkUpPwrMdV "System Backup Power Mode Validity";
BA_ "VNSigAllNodes" SG_ 2149859328 SysBkUpPwrMdV 1;
BA_ "GenSigSendType" SG_ 2149859328 SysBkupPwrMdEn 10;
BA_ "GenSigSendOnInit" SG_ 2149859328 SysBkupPwrMdEn 1;
BA_ "VNSigInfotainment" SG_ 2149859328 SysBkupPwrMdEn 1;
BA_ "VNSigParkedVehicle" SG_ 2149859328 SysBkupPwrMdEn 1;
BA_ "VNSigIntermediate" SG_ 2149859328 SysBkupPwrMdEn 1;
BA_ "SignalType" SG_ 2149859328 SysBkupPwrMdEn "BLN";
BA_ "SignalLongName" SG_ 2149859328 SysBkupPwrMdEn "System Backup Power Mode Enabled";
BA_ "VNSigAllNodes" SG_ 2149859328 SysBkupPwrMdEn 1;
BA_ "GenSigSendType" SG_ 2149859328 SysBkUpPwrMd 10;
BA_ "GenSigSendOnInit" SG_ 2149859328 SysBkUpPwrMd 1;
BA_ "VNSigInfotainment" SG_ 2149859328 SysBkUpPwrMd 1;
BA_ "VNSigParkedVehicle" SG_ 2149859328 SysBkUpPwrMd 1;
BA_ "VNSigIntermediate" SG_ 2149859328 SysBkUpPwrMd 1;
BA_ "SignalType" SG_ 2149859328 SysBkUpPwrMd "ENM";
BA_ "SignalLongName" SG_ 2149859328 SysBkUpPwrMd "System Backup Power Mode";
BA_ "VNSigAllNodes" SG_ 2149859328 SysBkUpPwrMd 1;
BA_ "GenSigSendType" SG_ 2155167744 ClsEngCmprtmtToStrtVehIO 10;
BA_ "SignalType" SG_ 2155167744 ClsEngCmprtmtToStrtVehIO "BLN";
BA_ "SignalLongName" SG_ 2155167744 ClsEngCmprtmtToStrtVehIO "Close Engine Compartment To Start Vehicle Indication On";
BA_ "VNSigAllNodes" SG_ 2155167744 ClsEngCmprtmtToStrtVehIO 1;
BA_ "GenSigSendType" SG_ 2155167744 PrsCltchPrsStrtAgnIO 10;
BA_ "SignalType" SG_ 2155167744 PrsCltchPrsStrtAgnIO "BLN";
BA_ "SignalLongName" SG_ 2155167744 PrsCltchPrsStrtAgnIO "Press Clutch and Press Start Again Indication On";
BA_ "VNSigAllNodes" SG_ 2155167744 PrsCltchPrsStrtAgnIO 1;
BA_ "GenSigSendType" SG_ 2155167744 PrsStrtAgnIO 10;
BA_ "SignalType" SG_ 2155167744 PrsStrtAgnIO "BLN";
BA_ "SignalLongName" SG_ 2155167744 PrsStrtAgnIO "Press Start Again Indication On";
BA_ "VNSigAllNodes" SG_ 2155167744 PrsStrtAgnIO 1;
BA_ "GenSigSendType" SG_ 2155167744 AutoShtdwnDsblIO 10;
BA_ "SignalType" SG_ 2155167744 AutoShtdwnDsblIO "BLN";
BA_ "SignalLongName" SG_ 2155167744 AutoShtdwnDsblIO "Automatic Shutdown Disabled Indication On";
BA_ "VNSigAllNodes" SG_ 2155167744 AutoShtdwnDsblIO 1;
BA_ "GenSigSendType" SG_ 2155167744 ShftToNtrlIO 10;
BA_ "SignalType" SG_ 2155167744 ShftToNtrlIO "BLN";
BA_ "SignalLongName" SG_ 2155167744 ShftToNtrlIO "Shift to Neutral Indication On";
BA_ "VNSigAllNodes" SG_ 2155167744 ShftToNtrlIO 1;
BA_ "GenSigSendType" SG_ 2155167744 AppPrkBrkIO 10;
BA_ "SignalType" SG_ 2155167744 AppPrkBrkIO "BLN";
BA_ "SignalLongName" SG_ 2155167744 AppPrkBrkIO "Apply Park Brake Indication On";
BA_ "VNSigAllNodes" SG_ 2155167744 AppPrkBrkIO 1;
BA_ "GenSigSendType" SG_ 2155167744 NRmtDtctdRstrtAllwd 10;
BA_ "SignalType" SG_ 2155167744 NRmtDtctdRstrtAllwd "BLN";
BA_ "SignalLongName" SG_ 2155167744 NRmtDtctdRstrtAllwd "No Remote Detected Restart Allowed";
BA_ "VNSigAllNodes" SG_ 2155167744 NRmtDtctdRstrtAllwd 1;
BA_ "GenSigSendType" SG_ 2155167744 NRmtDtdPsCluRstIO 10;
BA_ "SignalType" SG_ 2155167744 NRmtDtdPsCluRstIO "BLN";
BA_ "SignalLongName" SG_ 2155167744 NRmtDtdPsCluRstIO "No Remote Detected Press Clutch to Restart Indicator On";
BA_ "VNSigAllNodes" SG_ 2155167744 NRmtDtdPsCluRstIO 1;
BA_ "GenSigSendType" SG_ 2155167744 SecPwrMdPshBtnAtv 10;
BA_ "SignalType" SG_ 2155167744 SecPwrMdPshBtnAtv "BLN";
BA_ "SignalLongName" SG_ 2155167744 SecPwrMdPshBtnAtv "Secondary Power Mode Pushbutton Active";
BA_ "VNSigAllNodes" SG_ 2155167744 SecPwrMdPshBtnAtv 1;
BA_ "GenSigSendType" SG_ 2155167744 TSLgMdPwrCtOWAtv 10;
BA_ "SignalType" SG_ 2155167744 TSLgMdPwrCtOWAtv "BLN";
BA_ "SignalLongName" SG_ 2155167744 TSLgMdPwrCtOWAtv "Transport Storage Logistic Mode Power Cut Off Warning Active";
BA_ "VNSigAllNodes" SG_ 2155167744 TSLgMdPwrCtOWAtv 1;
BA_ "GenSigSendType" SG_ 2155167744 PrsBtnAgnTTrnEngOffIO 10;
BA_ "SignalType" SG_ 2155167744 PrsBtnAgnTTrnEngOffIO "BLN";
BA_ "SignalLongName" SG_ 2155167744 PrsBtnAgnTTrnEngOffIO "Press Button Again to Turn Engine Off Indicator On";
BA_ "VNSigAllNodes" SG_ 2155167744 PrsBtnAgnTTrnEngOffIO 1;
BA_ "GenSigSendType" SG_ 2155167744 NRmtDtdPsBrkRstIO 10;
BA_ "SignalType" SG_ 2155167744 NRmtDtdPsBrkRstIO "BLN";
BA_ "SignalLongName" SG_ 2155167744 NRmtDtdPsBrkRstIO "No Remote Detected Press Brake to Restart Indicator On";
BA_ "VNSigAllNodes" SG_ 2155167744 NRmtDtdPsBrkRstIO 1;
BA_ "GenSigSendType" SG_ 2155167744 NoReDetInOn 10;
BA_ "SignalType" SG_ 2155167744 NoReDetInOn "BLN";
BA_ "SignalLongName" SG_ 2155167744 NoReDetInOn "No Remote Detected Indication On";
BA_ "VNSigAllNodes" SG_ 2155167744 NoReDetInOn 1;
BA_ "GenSigSendType" SG_ 2155167744 ApplyCltPdlIO 10;
BA_ "SignalType" SG_ 2155167744 ApplyCltPdlIO "BLN";
BA_ "SignalLongName" SG_ 2155167744 ApplyCltPdlIO "Apply Clutch Pedal Indication On";
BA_ "VNSigAllNodes" SG_ 2155167744 ApplyCltPdlIO 1;
BA_ "GenSigSendType" SG_ 2155167744 VehMovState 10;
BA_ "GenSigSendOnInit" SG_ 2155167744 VehMovState 1;
BA_ "SignalType" SG_ 2155167744 VehMovState "ENM";
BA_ "SignalLongName" SG_ 2155167744 VehMovState "Vehicle Movement State";
BA_ "VNSigAllNodes" SG_ 2155167744 VehMovState 1;
BA_ "GenSigSendType" SG_ 2155167744 TrStLgMdAtv 10;
BA_ "GenSigSendOnInit" SG_ 2155167744 TrStLgMdAtv 1;
BA_ "VNSigInfotainment" SG_ 2155167744 TrStLgMdAtv 1;
BA_ "SignalType" SG_ 2155167744 TrStLgMdAtv "BLN";
BA_ "SignalLongName" SG_ 2155167744 TrStLgMdAtv "Transport Storage Logistic Mode Active";
BA_ "VNSigAllNodes" SG_ 2155167744 TrStLgMdAtv 1;
BA_ "GenSigSendType" SG_ 2155167744 TransModInactIO 10;
BA_ "SignalType" SG_ 2155167744 TransModInactIO "BLN";
BA_ "SignalLongName" SG_ 2155167744 TransModInactIO "Transport Mode Inactive Indication On";
BA_ "VNSigAllNodes" SG_ 2155167744 TransModInactIO 1;
BA_ "GenSigSendType" SG_ 2155167744 TransModActIO 10;
BA_ "SignalType" SG_ 2155167744 TransModActIO "BLN";
BA_ "SignalLongName" SG_ 2155167744 TransModActIO "Transport Mode Active Indication On";
BA_ "VNSigAllNodes" SG_ 2155167744 TransModActIO 1;
BA_ "GenSigSendType" SG_ 2155167744 ApplyBrkPdlIO 10;
BA_ "SignalType" SG_ 2155167744 ApplyBrkPdlIO "BLN";
BA_ "SignalLongName" SG_ 2155167744 ApplyBrkPdlIO "Apply Brake Pedal Indication On";
BA_ "VNSigAllNodes" SG_ 2155167744 ApplyBrkPdlIO 1;
BA_ "GenSigSendType" SG_ 2155167744 Ky_IdDevPr 10;
BA_ "GenSigSendOnInit" SG_ 2155167744 Ky_IdDevPr 1;
BA_ "VNSigInfotainment" SG_ 2155167744 Ky_IdDevPr 1;
BA_ "VNSigIntermediate" SG_ 2155167744 Ky_IdDevPr 1;
BA_ "SignalType" SG_ 2155167744 Ky_IdDevPr "BLN";
BA_ "SignalLongName" SG_ 2155167744 Ky_IdDevPr "Key / Identification Device Present";
BA_ "VNSigAllNodes" SG_ 2155167744 Ky_IdDevPr 1;
BA_ "GenSigSendType" SG_ 2155167744 KylsStrtUseTxPckIO 10;
BA_ "SignalType" SG_ 2155167744 KylsStrtUseTxPckIO "BLN";
BA_ "SignalLongName" SG_ 2155167744 KylsStrtUseTxPckIO "Keyless Start Use Transmitter Pocket Indication On";
BA_ "VNSigAllNodes" SG_ 2155167744 KylsStrtUseTxPckIO 1;
BA_ "GenSigSendType" SG_ 2155167744 ShftPrkIO 10;
BA_ "SignalType" SG_ 2155167744 ShftPrkIO "BLN";
BA_ "SignalLongName" SG_ 2155167744 ShftPrkIO "Shift to Park Indication On";
BA_ "VNSigAllNodes" SG_ 2155167744 ShftPrkIO 1;
BA_ "GenSigSendType" SG_ 2152611840 OBTCReqstrStat 10;
BA_ "GenSigSendOnInit" SG_ 2152611840 OBTCReqstrStat 1;
BA_ "VNSigInfotainment" SG_ 2152611840 OBTCReqstrStat 1;
BA_ "SignalType" SG_ 2152611840 OBTCReqstrStat "ENM";
BA_ "SignalLongName" SG_ 2152611840 OBTCReqstrStat "On Board Tester Coordination Requester Status";
BA_ "VNSigAllNodes" SG_ 2152611840 OBTCReqstrStat 1;
BA_ "GenSigDeltaValue" SG_ 2152611840 OBTCReqstrID 1;
BA_ "GenSigSendType" SG_ 2152611840 OBTCReqstrID 12;
BA_ "GenSigSendOnInit" SG_ 2152611840 OBTCReqstrID 1;
BA_ "VNSigInfotainment" SG_ 2152611840 OBTCReqstrID 1;
BA_ "SignalType" SG_ 2152611840 OBTCReqstrID "UNM";
BA_ "SignalLongName" SG_ 2152611840 OBTCReqstrID "On Board Tester Coordination Requester ID";
BA_ "VNSigAllNodes" SG_ 2152611840 OBTCReqstrID 1;
BA_ "GenSigDeltaValue" SG_ 2152611840 OBTCR_Prty 1;
BA_ "GenSigSendType" SG_ 2152611840 OBTCR_Prty 12;
BA_ "VNSigInfotainment" SG_ 2152611840 OBTCR_Prty 1;
BA_ "SignalType" SG_ 2152611840 OBTCR_Prty "UNM";
BA_ "PacketOrder" SG_ 2152611840 OBTCR_Prty 2;
BA_ "SignalLongName" SG_ 2152611840 OBTCR_Prty "On Board Tester Coordination Request : Priority";
BA_ "VNSigAllNodes" SG_ 2152611840 OBTCR_Prty 1;
BA_ "GenSigSendType" SG_ 2152611840 OBTCR_Actv 10;
BA_ "VNSigInfotainment" SG_ 2152611840 OBTCR_Actv 1;
BA_ "SignalType" SG_ 2152611840 OBTCR_Actv "BLN";
BA_ "PacketOrder" SG_ 2152611840 OBTCR_Actv 1;
BA_ "SignalLongName" SG_ 2152611840 OBTCR_Actv "On Board Tester Coordination Request : Active";
BA_ "VNSigAllNodes" SG_ 2152611840 OBTCR_Actv 1;
BA_ "GenSigSendType" SG_ 2156945408 WiFiSSIDDgts1to8_Mp 10;
BA_ "GenSigSendOnInit" SG_ 2156945408 WiFiSSIDDgts1to8_Mp 2;
BA_ "SignalType" SG_ 2156945408 WiFiSSIDDgts1to8_Mp "ASC";
BA_ "SignalLongName" SG_ 2156945408 WiFiSSIDDgts1to8_Mp "WiFi Service Set Identifier Digits 1 to 8 Map";
BA_ "VNSigAllNodes" SG_ 2156945408 WiFiSSIDDgts1to8_Mp 1;
BA_ "GenSigSendType" SG_ 2151292928 TrfRdsdInfCsStAvail 10;
BA_ "GenSigSendOnInit" SG_ 2151292928 TrfRdsdInfCsStAvail 2;
BA_ "SignalType" SG_ 2151292928 TrfRdsdInfCsStAvail "BLN";
BA_ "SignalLongName" SG_ 2151292928 TrfRdsdInfCsStAvail "Traffic and Roadside Information Customization Setting Available";
BA_ "VNSigAllNodes" SG_ 2151292928 TrfRdsdInfCsStAvail 1;
BA_ "GenSigSendType" SG_ 2151292928 TrfRdsdInfCsCrStVal 10;
BA_ "GenSigSendOnInit" SG_ 2151292928 TrfRdsdInfCsCrStVal 2;
BA_ "SignalType" SG_ 2151292928 TrfRdsdInfCsCrStVal "ENM";
BA_ "SignalLongName" SG_ 2151292928 TrfRdsdInfCsCrStVal "Traffic and Roadside Information Customization Current Setting Value";
BA_ "VNSigAllNodes" SG_ 2151292928 TrfRdsdInfCsCrStVal 1;
BA_ "GenSigSendType" SG_ 2151292928 TRICA_Resrv5Avail 10;
BA_ "GenSigSendOnInit" SG_ 2151292928 TRICA_Resrv5Avail 2;
BA_ "SignalType" SG_ 2151292928 TRICA_Resrv5Avail "BLN";
BA_ "PacketOrder" SG_ 2151292928 TRICA_Resrv5Avail 7;
BA_ "SignalLongName" SG_ 2151292928 TRICA_Resrv5Avail "Traffic and Roadside Information Customization Available : Reserved5 Available";
BA_ "VNSigAllNodes" SG_ 2151292928 TRICA_Resrv5Avail 1;
BA_ "GenSigSendType" SG_ 2151292928 TRICA_Resrv4Avail 10;
BA_ "GenSigSendOnInit" SG_ 2151292928 TRICA_Resrv4Avail 2;
BA_ "SignalType" SG_ 2151292928 TRICA_Resrv4Avail "BLN";
BA_ "PacketOrder" SG_ 2151292928 TRICA_Resrv4Avail 6;
BA_ "SignalLongName" SG_ 2151292928 TRICA_Resrv4Avail "Traffic and Roadside Information Customization Available : Reserved4 Available";
BA_ "VNSigAllNodes" SG_ 2151292928 TRICA_Resrv4Avail 1;
BA_ "GenSigSendType" SG_ 2151292928 TRICA_Resrv3Avail 10;
BA_ "GenSigSendOnInit" SG_ 2151292928 TRICA_Resrv3Avail 2;
BA_ "SignalType" SG_ 2151292928 TRICA_Resrv3Avail "BLN";
BA_ "PacketOrder" SG_ 2151292928 TRICA_Resrv3Avail 5;
BA_ "SignalLongName" SG_ 2151292928 TRICA_Resrv3Avail "Traffic and Roadside Information Customization Available : Reserved3 Available";
BA_ "VNSigAllNodes" SG_ 2151292928 TRICA_Resrv3Avail 1;
BA_ "GenSigSendType" SG_ 2151292928 TRICA_Resrv2Avail 10;
BA_ "GenSigSendOnInit" SG_ 2151292928 TRICA_Resrv2Avail 2;
BA_ "SignalType" SG_ 2151292928 TRICA_Resrv2Avail "BLN";
BA_ "PacketOrder" SG_ 2151292928 TRICA_Resrv2Avail 4;
BA_ "SignalLongName" SG_ 2151292928 TRICA_Resrv2Avail "Traffic and Roadside Information Customization Available : Reserved2 Available";
BA_ "VNSigAllNodes" SG_ 2151292928 TRICA_Resrv2Avail 1;
BA_ "GenSigSendType" SG_ 2151292928 TRICA_Resrv1Avail 10;
BA_ "GenSigSendOnInit" SG_ 2151292928 TRICA_Resrv1Avail 2;
BA_ "SignalType" SG_ 2151292928 TRICA_Resrv1Avail "BLN";
BA_ "PacketOrder" SG_ 2151292928 TRICA_Resrv1Avail 3;
BA_ "SignalLongName" SG_ 2151292928 TRICA_Resrv1Avail "Traffic and Roadside Information Customization Available : Reserved1 Available";
BA_ "VNSigAllNodes" SG_ 2151292928 TRICA_Resrv1Avail 1;
BA_ "GenSigSendType" SG_ 2151292928 TRICA_OnAvail 10;
BA_ "GenSigSendOnInit" SG_ 2151292928 TRICA_OnAvail 2;
BA_ "SignalType" SG_ 2151292928 TRICA_OnAvail "BLN";
BA_ "PacketOrder" SG_ 2151292928 TRICA_OnAvail 2;
BA_ "SignalLongName" SG_ 2151292928 TRICA_OnAvail "Traffic and Roadside Information Customization Available : On Available";
BA_ "VNSigAllNodes" SG_ 2151292928 TRICA_OnAvail 1;
BA_ "GenSigSendType" SG_ 2151292928 TRICA_OfAvail 10;
BA_ "GenSigSendOnInit" SG_ 2151292928 TRICA_OfAvail 2;
BA_ "SignalType" SG_ 2151292928 TRICA_OfAvail "BLN";
BA_ "PacketOrder" SG_ 2151292928 TRICA_OfAvail 1;
BA_ "SignalLongName" SG_ 2151292928 TRICA_OfAvail "Traffic and Roadside Information Customization Available : Off Available";
BA_ "VNSigAllNodes" SG_ 2151292928 TRICA_OfAvail 1;
BA_ "GenSigSendType" SG_ 2151292928 IntrStopAlrtCsSetAvl 10;
BA_ "GenSigSendOnInit" SG_ 2151292928 IntrStopAlrtCsSetAvl 2;
BA_ "SignalType" SG_ 2151292928 IntrStopAlrtCsSetAvl "BLN";
BA_ "SignalLongName" SG_ 2151292928 IntrStopAlrtCsSetAvl "Intersection Stop Alert Customization Setting Available";
BA_ "VNSigAllNodes" SG_ 2151292928 IntrStopAlrtCsSetAvl 1;
BA_ "GenSigSendType" SG_ 2151292928 IntrStAlrtCsCrSetVal 10;
BA_ "GenSigSendOnInit" SG_ 2151292928 IntrStAlrtCsCrSetVal 2;
BA_ "SignalType" SG_ 2151292928 IntrStAlrtCsCrSetVal "ENM";
BA_ "SignalLongName" SG_ 2151292928 IntrStAlrtCsCrSetVal "Intersection Stop Alert Customization Current Setting Value";
BA_ "VNSigAllNodes" SG_ 2151292928 IntrStAlrtCsCrSetVal 1;
BA_ "GenSigSendType" SG_ 2151292928 ISACA_Resrv4Avail 10;
BA_ "GenSigSendOnInit" SG_ 2151292928 ISACA_Resrv4Avail 2;
BA_ "SignalType" SG_ 2151292928 ISACA_Resrv4Avail "BLN";
BA_ "PacketOrder" SG_ 2151292928 ISACA_Resrv4Avail 7;
BA_ "SignalLongName" SG_ 2151292928 ISACA_Resrv4Avail "Intersection Stop Alert Customization Available : Reserved4 Available";
BA_ "VNSigAllNodes" SG_ 2151292928 ISACA_Resrv4Avail 1;
BA_ "GenSigSendType" SG_ 2151292928 ISACA_Resrv3Avail 10;
BA_ "GenSigSendOnInit" SG_ 2151292928 ISACA_Resrv3Avail 2;
BA_ "SignalType" SG_ 2151292928 ISACA_Resrv3Avail "BLN";
BA_ "PacketOrder" SG_ 2151292928 ISACA_Resrv3Avail 6;
BA_ "SignalLongName" SG_ 2151292928 ISACA_Resrv3Avail "Intersection Stop Alert Customization Available : Reserved3 Available";
BA_ "VNSigAllNodes" SG_ 2151292928 ISACA_Resrv3Avail 1;
BA_ "GenSigSendType" SG_ 2151292928 ISACA_Resrv2Avail 10;
BA_ "GenSigSendOnInit" SG_ 2151292928 ISACA_Resrv2Avail 2;
BA_ "SignalType" SG_ 2151292928 ISACA_Resrv2Avail "BLN";
BA_ "PacketOrder" SG_ 2151292928 ISACA_Resrv2Avail 5;
BA_ "SignalLongName" SG_ 2151292928 ISACA_Resrv2Avail "Intersection Stop Alert Customization Available : Reserved2 Available";
BA_ "VNSigAllNodes" SG_ 2151292928 ISACA_Resrv2Avail 1;
BA_ "GenSigSendType" SG_ 2151292928 ISACA_Resrv1Avail 10;
BA_ "GenSigSendOnInit" SG_ 2151292928 ISACA_Resrv1Avail 2;
BA_ "SignalType" SG_ 2151292928 ISACA_Resrv1Avail "BLN";
BA_ "PacketOrder" SG_ 2151292928 ISACA_Resrv1Avail 4;
BA_ "SignalLongName" SG_ 2151292928 ISACA_Resrv1Avail "Intersection Stop Alert Customization Available : Reserved1 Available";
BA_ "VNSigAllNodes" SG_ 2151292928 ISACA_Resrv1Avail 1;
BA_ "GenSigSendType" SG_ 2151292928 ISACA_AlrtBrkAvail 10;
BA_ "GenSigSendOnInit" SG_ 2151292928 ISACA_AlrtBrkAvail 2;
BA_ "SignalType" SG_ 2151292928 ISACA_AlrtBrkAvail "BLN";
BA_ "PacketOrder" SG_ 2151292928 ISACA_AlrtBrkAvail 3;
BA_ "SignalLongName" SG_ 2151292928 ISACA_AlrtBrkAvail "Intersection Stop Alert Customization Available : Alert and Brake Available";
BA_ "VNSigAllNodes" SG_ 2151292928 ISACA_AlrtBrkAvail 1;
BA_ "GenSigSendType" SG_ 2151292928 ISACA_AlrtAvail 10;
BA_ "GenSigSendOnInit" SG_ 2151292928 ISACA_AlrtAvail 2;
BA_ "SignalType" SG_ 2151292928 ISACA_AlrtAvail "BLN";
BA_ "PacketOrder" SG_ 2151292928 ISACA_AlrtAvail 2;
BA_ "SignalLongName" SG_ 2151292928 ISACA_AlrtAvail "Intersection Stop Alert Customization Available : Alert Available";
BA_ "VNSigAllNodes" SG_ 2151292928 ISACA_AlrtAvail 1;
BA_ "GenSigSendType" SG_ 2151292928 ISACA_OfAvail 10;
BA_ "GenSigSendOnInit" SG_ 2151292928 ISACA_OfAvail 2;
BA_ "SignalType" SG_ 2151292928 ISACA_OfAvail "BLN";
BA_ "PacketOrder" SG_ 2151292928 ISACA_OfAvail 1;
BA_ "SignalLongName" SG_ 2151292928 ISACA_OfAvail "Intersection Stop Alert Customization Available : Off Available";
BA_ "VNSigAllNodes" SG_ 2151292928 ISACA_OfAvail 1;
BA_ "GenSigSendType" SG_ 2151292928 CntdVehBrkAltCsStAvl 10;
BA_ "GenSigSendOnInit" SG_ 2151292928 CntdVehBrkAltCsStAvl 2;
BA_ "SignalType" SG_ 2151292928 CntdVehBrkAltCsStAvl "BLN";
BA_ "SignalLongName" SG_ 2151292928 CntdVehBrkAltCsStAvl "Connected Vehicle Braking Alerts Customization Setting Available";
BA_ "VNSigAllNodes" SG_ 2151292928 CntdVehBrkAltCsStAvl 1;
BA_ "GenSigSendType" SG_ 2151292928 CntdVehBrAltCsCrStVal 10;
BA_ "GenSigSendOnInit" SG_ 2151292928 CntdVehBrAltCsCrStVal 2;
BA_ "SignalType" SG_ 2151292928 CntdVehBrAltCsCrStVal "ENM";
BA_ "SignalLongName" SG_ 2151292928 CntdVehBrAltCsCrStVal "Connected Vehicle Braking Alerts Customization Current Setting Value";
BA_ "VNSigAllNodes" SG_ 2151292928 CntdVehBrAltCsCrStVal 1;
BA_ "GenSigSendType" SG_ 2151292928 CVBACA_Resrv5Avail 10;
BA_ "GenSigSendOnInit" SG_ 2151292928 CVBACA_Resrv5Avail 2;
BA_ "SignalType" SG_ 2151292928 CVBACA_Resrv5Avail "BLN";
BA_ "PacketOrder" SG_ 2151292928 CVBACA_Resrv5Avail 7;
BA_ "SignalLongName" SG_ 2151292928 CVBACA_Resrv5Avail "Connected Vehicle Braking Alerts Customization Available : Reserved5 Available";
BA_ "VNSigAllNodes" SG_ 2151292928 CVBACA_Resrv5Avail 1;
BA_ "GenSigSendType" SG_ 2151292928 CVBACA_Resrv4Avail 10;
BA_ "GenSigSendOnInit" SG_ 2151292928 CVBACA_Resrv4Avail 2;
BA_ "SignalType" SG_ 2151292928 CVBACA_Resrv4Avail "BLN";
BA_ "PacketOrder" SG_ 2151292928 CVBACA_Resrv4Avail 6;
BA_ "SignalLongName" SG_ 2151292928 CVBACA_Resrv4Avail "Connected Vehicle Braking Alerts Customization Available : Reserved4 Available";
BA_ "VNSigAllNodes" SG_ 2151292928 CVBACA_Resrv4Avail 1;
BA_ "GenSigSendType" SG_ 2151292928 CVBACA_Resrv3Avail 10;
BA_ "GenSigSendOnInit" SG_ 2151292928 CVBACA_Resrv3Avail 2;
BA_ "SignalType" SG_ 2151292928 CVBACA_Resrv3Avail "BLN";
BA_ "PacketOrder" SG_ 2151292928 CVBACA_Resrv3Avail 5;
BA_ "SignalLongName" SG_ 2151292928 CVBACA_Resrv3Avail "Connected Vehicle Braking Alerts Customization Available : Reserved3 Available";
BA_ "VNSigAllNodes" SG_ 2151292928 CVBACA_Resrv3Avail 1;
BA_ "GenSigSendType" SG_ 2151292928 CVBACA_Resrv2Avail 10;
BA_ "GenSigSendOnInit" SG_ 2151292928 CVBACA_Resrv2Avail 2;
BA_ "SignalType" SG_ 2151292928 CVBACA_Resrv2Avail "BLN";
BA_ "PacketOrder" SG_ 2151292928 CVBACA_Resrv2Avail 4;
BA_ "SignalLongName" SG_ 2151292928 CVBACA_Resrv2Avail "Connected Vehicle Braking Alerts Customization Available : Reserved2 Available";
BA_ "VNSigAllNodes" SG_ 2151292928 CVBACA_Resrv2Avail 1;
BA_ "GenSigSendType" SG_ 2151292928 CVBACA_Resrv1Avail 10;
BA_ "GenSigSendOnInit" SG_ 2151292928 CVBACA_Resrv1Avail 2;
BA_ "SignalType" SG_ 2151292928 CVBACA_Resrv1Avail "BLN";
BA_ "PacketOrder" SG_ 2151292928 CVBACA_Resrv1Avail 3;
BA_ "SignalLongName" SG_ 2151292928 CVBACA_Resrv1Avail "Connected Vehicle Braking Alerts Customization Available : Reserved1 Available";
BA_ "VNSigAllNodes" SG_ 2151292928 CVBACA_Resrv1Avail 1;
BA_ "GenSigSendType" SG_ 2151292928 CVBACA_OnAvail 10;
BA_ "GenSigSendOnInit" SG_ 2151292928 CVBACA_OnAvail 2;
BA_ "SignalType" SG_ 2151292928 CVBACA_OnAvail "BLN";
BA_ "PacketOrder" SG_ 2151292928 CVBACA_OnAvail 2;
BA_ "SignalLongName" SG_ 2151292928 CVBACA_OnAvail "Connected Vehicle Braking Alerts Customization Available : On Available";
BA_ "VNSigAllNodes" SG_ 2151292928 CVBACA_OnAvail 1;
BA_ "GenSigSendType" SG_ 2151292928 CVBACA_OfAvail 10;
BA_ "GenSigSendOnInit" SG_ 2151292928 CVBACA_OfAvail 2;
BA_ "SignalType" SG_ 2151292928 CVBACA_OfAvail "BLN";
BA_ "PacketOrder" SG_ 2151292928 CVBACA_OfAvail 1;
BA_ "SignalLongName" SG_ 2151292928 CVBACA_OfAvail "Connected Vehicle Braking Alerts Customization Available : Off Available";
BA_ "VNSigAllNodes" SG_ 2151292928 CVBACA_OfAvail 1;
BA_ "GenSigDeltaValue" SG_ 2151464960 V2VSR_TrfLghtDispLim 1;
BA_ "GenSigSendType" SG_ 2151464960 V2VSR_TrfLghtDispLim 12;
BA_ "PacketOrder" SG_ 2151464960 V2VSR_TrfLghtDispLim 3;
BA_ "SignalType" SG_ 2151464960 V2VSR_TrfLghtDispLim "UNM";
BA_ "SignalLongName" SG_ 2151464960 V2VSR_TrfLghtDispLim "Vehicle to Vehicle Speed Recommendation : Traffic Light Maximum Display Limit";
BA_ "VNSigAllNodes" SG_ 2151464960 V2VSR_TrfLghtDispLim 1;
BA_ "GenSigDeltaValue" SG_ 2151464960 V2VSR_TrfLghtMaxRecmndSpd 1;
BA_ "GenSigSendType" SG_ 2151464960 V2VSR_TrfLghtMaxRecmndSpd 12;
BA_ "PacketOrder" SG_ 2151464960 V2VSR_TrfLghtMaxRecmndSpd 2;
BA_ "SignalType" SG_ 2151464960 V2VSR_TrfLghtMaxRecmndSpd "UNM";
BA_ "SignalLongName" SG_ 2151464960 V2VSR_TrfLghtMaxRecmndSpd "Vehicle to Vehicle Speed Recommendation : Traffic Light Maximum Recommended Speed";
BA_ "VNSigAllNodes" SG_ 2151464960 V2VSR_TrfLghtMaxRecmndSpd 1;
BA_ "GenSigDeltaValue" SG_ 2151464960 V2VSR_TrfLghtMinRecmndSpd 1;
BA_ "GenSigSendType" SG_ 2151464960 V2VSR_TrfLghtMinRecmndSpd 12;
BA_ "PacketOrder" SG_ 2151464960 V2VSR_TrfLghtMinRecmndSpd 1;
BA_ "SignalType" SG_ 2151464960 V2VSR_TrfLghtMinRecmndSpd "UNM";
BA_ "SignalLongName" SG_ 2151464960 V2VSR_TrfLghtMinRecmndSpd "Vehicle to Vehicle Speed Recommendation : Traffic Light Minimum Recommended Speed";
BA_ "VNSigAllNodes" SG_ 2151464960 V2VSR_TrfLghtMinRecmndSpd 1;
BA_ "GenSigSendType" SG_ 2151464960 V2VWrngIndReq 10;
BA_ "SignalType" SG_ 2151464960 V2VWrngIndReq "ENM";
BA_ "SignalLongName" SG_ 2151464960 V2VWrngIndReq "Vehicle To Vehicle Warning Indication Request";
BA_ "VNSigAllNodes" SG_ 2151464960 V2VWrngIndReq 1;
BA_ "GenSigDeltaValue" SG_ 2151464960 V2VWrngDistRemng 1;
BA_ "GenSigSendType" SG_ 2151464960 V2VWrngDistRemng 12;
BA_ "SignalType" SG_ 2151464960 V2VWrngDistRemng "UNM";
BA_ "SignalLongName" SG_ 2151464960 V2VWrngDistRemng "Vehicle to Vehicle Warning Distance Remaining";
BA_ "VNSigAllNodes" SG_ 2151464960 V2VWrngDistRemng 1;
BA_ "GenSigSendType" SG_ 2151464960 V2VWrngDirctn 10;
BA_ "SignalType" SG_ 2151464960 V2VWrngDirctn "ENM";
BA_ "SignalLongName" SG_ 2151464960 V2VWrngDirctn "Vehicle to Vehicle Warning Direction";
BA_ "VNSigAllNodes" SG_ 2151464960 V2VWrngDirctn 1;
BA_ "GenSigSendType" SG_ 2151464960 V2VSrvIndReq 10;
BA_ "SignalType" SG_ 2151464960 V2VSrvIndReq "ENM";
BA_ "SignalLongName" SG_ 2151464960 V2VSrvIndReq "Vehicle To Vehicle Service Indication Request";
BA_ "VNSigAllNodes" SG_ 2151464960 V2VSrvIndReq 1;
BA_ "GenSigSendType" SG_ 2151464960 V2VTLI_TrfLghtMntngDirctn 10;
BA_ "PacketOrder" SG_ 2151464960 V2VTLI_TrfLghtMntngDirctn 5;
BA_ "SignalType" SG_ 2151464960 V2VTLI_TrfLghtMntngDirctn "ENM";
BA_ "SignalLongName" SG_ 2151464960 V2VTLI_TrfLghtMntngDirctn "Vehicle to Vehicle Traffic Light Information : Traffic Light Mounting Direction";
BA_ "VNSigAllNodes" SG_ 2151464960 V2VTLI_TrfLghtMntngDirctn 1;
BA_ "GenSigSendType" SG_ 2151464960 V2VTLI_TrfLghtValDirctn 10;
BA_ "PacketOrder" SG_ 2151464960 V2VTLI_TrfLghtValDirctn 4;
BA_ "SignalType" SG_ 2151464960 V2VTLI_TrfLghtValDirctn "ENM";
BA_ "SignalLongName" SG_ 2151464960 V2VTLI_TrfLghtValDirctn "Vehicle to Vehicle Traffic Light Information : Traffic Light Valid Direction";
BA_ "VNSigAllNodes" SG_ 2151464960 V2VTLI_TrfLghtValDirctn 1;
BA_ "GenSigSendType" SG_ 2151464960 V2VTLI_TrfLghtPhsArivl 10;
BA_ "PacketOrder" SG_ 2151464960 V2VTLI_TrfLghtPhsArivl 3;
BA_ "SignalType" SG_ 2151464960 V2VTLI_TrfLghtPhsArivl "ENM";
BA_ "SignalLongName" SG_ 2151464960 V2VTLI_TrfLghtPhsArivl "Vehicle to Vehicle Traffic Light Information : Traffic Light Phase at Arrival";
BA_ "VNSigAllNodes" SG_ 2151464960 V2VTLI_TrfLghtPhsArivl 1;
BA_ "GenSigSendType" SG_ 2151464960 V2VTLI_TrfLghtActlPhs 10;
BA_ "PacketOrder" SG_ 2151464960 V2VTLI_TrfLghtActlPhs 2;
BA_ "SignalType" SG_ 2151464960 V2VTLI_TrfLghtActlPhs "ENM";
BA_ "SignalLongName" SG_ 2151464960 V2VTLI_TrfLghtActlPhs "Vehicle to Vehicle Traffic Light Information : Traffic Light Actual Phase";
BA_ "VNSigAllNodes" SG_ 2151464960 V2VTLI_TrfLghtActlPhs 1;
BA_ "GenSigDeltaValue" SG_ 2151464960 V2VTLI_TrfLghtTmPhsSw 1;
BA_ "GenSigSendType" SG_ 2151464960 V2VTLI_TrfLghtTmPhsSw 12;
BA_ "PacketOrder" SG_ 2151464960 V2VTLI_TrfLghtTmPhsSw 1;
BA_ "SignalType" SG_ 2151464960 V2VTLI_TrfLghtTmPhsSw "UNM";
BA_ "SignalLongName" SG_ 2151464960 V2VTLI_TrfLghtTmPhsSw "Vehicle to Vehicle Traffic Light Information : Traffic Light Time to Phase Switch";
BA_ "VNSigAllNodes" SG_ 2151464960 V2VTLI_TrfLghtTmPhsSw 1;
BA_ "GenSigDeltaValue" SG_ 2151448576 V2VSyRghtHptStVbRqSN 1;
BA_ "GenSigSendType" SG_ 2151448576 V2VSyRghtHptStVbRqSN 12;
BA_ "SignalType" SG_ 2151448576 V2VSyRghtHptStVbRqSN "UNM";
BA_ "SignalLongName" SG_ 2151448576 V2VSyRghtHptStVbRqSN "Vehicle to Vehicle System Right Haptic Seat Vibration Request Sequence Number";
BA_ "VNSigAllNodes" SG_ 2151448576 V2VSyRghtHptStVbRqSN 1;
BA_ "GenSigDeltaValue" SG_ 2151448576 V2VSyRghtHptStVbRq 1;
BA_ "GenSigSendType" SG_ 2151448576 V2VSyRghtHptStVbRq 12;
BA_ "SignalType" SG_ 2151448576 V2VSyRghtHptStVbRq "UNM";
BA_ "SignalLongName" SG_ 2151448576 V2VSyRghtHptStVbRq "Vehicle to Vehicle System Right Haptic Seat Vibration Request";
BA_ "VNSigAllNodes" SG_ 2151448576 V2VSyRghtHptStVbRq 1;
BA_ "GenSigDeltaValue" SG_ 2151448576 V2VSyLftHptStVbRqSN 1;
BA_ "GenSigSendType" SG_ 2151448576 V2VSyLftHptStVbRqSN 12;
BA_ "SignalType" SG_ 2151448576 V2VSyLftHptStVbRqSN "UNM";
BA_ "SignalLongName" SG_ 2151448576 V2VSyLftHptStVbRqSN "Vehicle to Vehicle System Left Haptic Seat Vibration Request Sequence Number";
BA_ "VNSigAllNodes" SG_ 2151448576 V2VSyLftHptStVbRqSN 1;
BA_ "GenSigDeltaValue" SG_ 2151448576 V2VSyLftHptStVbRq 1;
BA_ "GenSigSendType" SG_ 2151448576 V2VSyLftHptStVbRq 12;
BA_ "SignalType" SG_ 2151448576 V2VSyLftHptStVbRq "UNM";
BA_ "SignalLongName" SG_ 2151448576 V2VSyLftHptStVbRq "Vehicle to Vehicle System Left Haptic Seat Vibration Request";
BA_ "VNSigAllNodes" SG_ 2151448576 V2VSyLftHptStVbRq 1;
BA_ "GenSigDeltaValue" SG_ 2151448576 V2VSysHptStVibRqSN 1;
BA_ "GenSigSendType" SG_ 2151448576 V2VSysHptStVibRqSN 12;
BA_ "SignalType" SG_ 2151448576 V2VSysHptStVibRqSN "UNM";
BA_ "SignalLongName" SG_ 2151448576 V2VSysHptStVibRqSN "Vehicle to Vehicle System Haptic Seat Vibration Request Sequence Number";
BA_ "VNSigAllNodes" SG_ 2151448576 V2VSysHptStVibRqSN 1;
BA_ "GenSigDeltaValue" SG_ 2151448576 V2VSysHptcStVibReq 1;
BA_ "GenSigSendType" SG_ 2151448576 V2VSysHptcStVibReq 12;
BA_ "SignalType" SG_ 2151448576 V2VSysHptcStVibReq "UNM";
BA_ "SignalLongName" SG_ 2151448576 V2VSysHptcStVibReq "Vehicle to Vehicle System Haptic Seat Vibration Request";
BA_ "VNSigAllNodes" SG_ 2151448576 V2VSysHptcStVibReq 1;
BA_ "GenSigSendType" SG_ 2153930752 LnCntrVhlStpd 10;
BA_ "SignalType" SG_ 2153930752 LnCntrVhlStpd "BLN";
BA_ "SignalLongName" SG_ 2153930752 LnCntrVhlStpd "Lane Centering Vehicle Stopped";
BA_ "VNSigAllNodes" SG_ 2153930752 LnCntrVhlStpd 1;
BA_ "GenSigSendType" SG_ 2153930752 LnCntrSpchPrmtReq 10;
BA_ "SignalType" SG_ 2153930752 LnCntrSpchPrmtReq "ENM";
BA_ "SignalLongName" SG_ 2153930752 LnCntrSpchPrmtReq "Lane Centering Speech Prompt Request";
BA_ "VNSigAllNodes" SG_ 2153930752 LnCntrSpchPrmtReq 1;
BA_ "GenSigSendType" SG_ 2153930752 LnCntrNonRspDrvrCnd 10;
BA_ "SignalType" SG_ 2153930752 LnCntrNonRspDrvrCnd "BLN";
BA_ "SignalLongName" SG_ 2153930752 LnCntrNonRspDrvrCnd "Lane Centering Non Responsive Driver Condition";
BA_ "VNSigAllNodes" SG_ 2153930752 LnCntrNonRspDrvrCnd 1;
BA_ "GenSigSendType" SG_ 2153930752 LnCntrEsclnStat 10;
BA_ "SignalType" SG_ 2153930752 LnCntrEsclnStat "ENM";
BA_ "SignalLongName" SG_ 2153930752 LnCntrEsclnStat "Lane Centering Escalation Status";
BA_ "VNSigAllNodes" SG_ 2153930752 LnCntrEsclnStat 1;
BA_ "GenSigSendType" SG_ 2153930752 LCWrnIndReq 10;
BA_ "SignalType" SG_ 2153930752 LCWrnIndReq "ENM";
BA_ "SignalLongName" SG_ 2153930752 LCWrnIndReq "Lane Centering Warning Indication Request";
BA_ "VNSigAllNodes" SG_ 2153930752 LCWrnIndReq 1;
BA_ "GenSigSendType" SG_ 2153930752 LCCDrvrAwrnsIO 10;
BA_ "SignalType" SG_ 2153930752 LCCDrvrAwrnsIO "BLN";
BA_ "SignalLongName" SG_ 2153930752 LCCDrvrAwrnsIO "Lane Centering Driver Awareness Indication On";
BA_ "VNSigAllNodes" SG_ 2153930752 LCCDrvrAwrnsIO 1;
BA_ "GenSigSendType" SG_ 2153930752 LCConvMsgIndreq 10;
BA_ "SignalType" SG_ 2153930752 LCConvMsgIndreq "ENM";
BA_ "SignalLongName" SG_ 2153930752 LCConvMsgIndreq "Lane Centering Convenience Message Indication Request";
BA_ "VNSigAllNodes" SG_ 2153930752 LCConvMsgIndreq 1;
BA_ "GenSigSendType" SG_ 2153930752 LCCIndReq 10;
BA_ "SignalType" SG_ 2153930752 LCCIndReq "ENM";
BA_ "SignalLongName" SG_ 2153930752 LCCIndReq "Lane Centering Control Indication Request";
BA_ "VNSigAllNodes" SG_ 2153930752 LCCIndReq 1;
BA_ "GenSigDeltaValue" SG_ 2153930752 LnCntrngCtlIcnLoctn 1;
BA_ "GenSigSendType" SG_ 2153930752 LnCntrngCtlIcnLoctn 12;
BA_ "SignalType" SG_ 2153930752 LnCntrngCtlIcnLoctn "SNM";
BA_ "SignalLongName" SG_ 2153930752 LnCntrngCtlIcnLoctn "Lane Centering Control Icon Location";
BA_ "VNSigAllNodes" SG_ 2153930752 LnCntrngCtlIcnLoctn 1;
BA_ "GenSigDeltaValue" SG_ 2153889792 LCArrwBlk5Offst 1;
BA_ "GenSigSendType" SG_ 2153889792 LCArrwBlk5Offst 12;
BA_ "SignalType" SG_ 2153889792 LCArrwBlk5Offst "SNM";
BA_ "SignalLongName" SG_ 2153889792 LCArrwBlk5Offst "Lane Centering Arrow Block 5 Offset";
BA_ "VNSigAllNodes" SG_ 2153889792 LCArrwBlk5Offst 1;
BA_ "GenSigSendType" SG_ 2153889792 LCArrwBlk5Act 10;
BA_ "SignalType" SG_ 2153889792 LCArrwBlk5Act "BLN";
BA_ "SignalLongName" SG_ 2153889792 LCArrwBlk5Act "Lane Centering Arrow Block 5 Active";
BA_ "VNSigAllNodes" SG_ 2153889792 LCArrwBlk5Act 1;
BA_ "GenSigDeltaValue" SG_ 2153889792 LCArrwBlk4Offst 1;
BA_ "GenSigSendType" SG_ 2153889792 LCArrwBlk4Offst 12;
BA_ "SignalType" SG_ 2153889792 LCArrwBlk4Offst "SNM";
BA_ "SignalLongName" SG_ 2153889792 LCArrwBlk4Offst "Lane Centering Arrow Block 4 Offset";
BA_ "VNSigAllNodes" SG_ 2153889792 LCArrwBlk4Offst 1;
BA_ "GenSigSendType" SG_ 2153889792 LCArrwBlk4Act 10;
BA_ "SignalType" SG_ 2153889792 LCArrwBlk4Act "BLN";
BA_ "SignalLongName" SG_ 2153889792 LCArrwBlk4Act "Lane Centering Arrow Block 4 Active";
BA_ "VNSigAllNodes" SG_ 2153889792 LCArrwBlk4Act 1;
BA_ "GenSigDeltaValue" SG_ 2153889792 LCArrwBlk3Offst 1;
BA_ "GenSigSendType" SG_ 2153889792 LCArrwBlk3Offst 12;
BA_ "SignalType" SG_ 2153889792 LCArrwBlk3Offst "SNM";
BA_ "SignalLongName" SG_ 2153889792 LCArrwBlk3Offst "Lane Centering Arrow Block 3 Offset";
BA_ "VNSigAllNodes" SG_ 2153889792 LCArrwBlk3Offst 1;
BA_ "GenSigSendType" SG_ 2153889792 LCArrwBlk3Act 10;
BA_ "SignalType" SG_ 2153889792 LCArrwBlk3Act "BLN";
BA_ "SignalLongName" SG_ 2153889792 LCArrwBlk3Act "Lane Centering Arrow Block 3 Active";
BA_ "VNSigAllNodes" SG_ 2153889792 LCArrwBlk3Act 1;
BA_ "GenSigDeltaValue" SG_ 2153889792 LCArrwBlk2Offst 1;
BA_ "GenSigSendType" SG_ 2153889792 LCArrwBlk2Offst 12;
BA_ "SignalType" SG_ 2153889792 LCArrwBlk2Offst "SNM";
BA_ "SignalLongName" SG_ 2153889792 LCArrwBlk2Offst "Lane Centering Arrow Block 2 Offset";
BA_ "VNSigAllNodes" SG_ 2153889792 LCArrwBlk2Offst 1;
BA_ "GenSigSendType" SG_ 2153889792 LCArrwBlk2Act 10;
BA_ "SignalType" SG_ 2153889792 LCArrwBlk2Act "BLN";
BA_ "SignalLongName" SG_ 2153889792 LCArrwBlk2Act "Lane Centering Arrow Block 2 Active";
BA_ "VNSigAllNodes" SG_ 2153889792 LCArrwBlk2Act 1;
BA_ "GenSigSendType" SG_ 2153889792 LCArrwBlk1Act 10;
BA_ "SignalType" SG_ 2153889792 LCArrwBlk1Act "BLN";
BA_ "SignalLongName" SG_ 2153889792 LCArrwBlk1Act "Lane Centering Arrow Block 1 Active";
BA_ "VNSigAllNodes" SG_ 2153889792 LCArrwBlk1Act 1;
BA_ "GenSigSendType" SG_ 2151063552 TrfRdsdInfCsStReq 10;
BA_ "SignalType" SG_ 2151063552 TrfRdsdInfCsStReq "ENM";
BA_ "SignalLongName" SG_ 2151063552 TrfRdsdInfCsStReq "Traffic and Roadside Information Customization Setting Request";
BA_ "VNSigAllNodes" SG_ 2151063552 TrfRdsdInfCsStReq 1;
BA_ "GenSigSendType" SG_ 2151063552 IntrStopAlrtCsSetReq 10;
BA_ "SignalType" SG_ 2151063552 IntrStopAlrtCsSetReq "ENM";
BA_ "SignalLongName" SG_ 2151063552 IntrStopAlrtCsSetReq "Intersection Stop Alert Customization Setting Request";
BA_ "VNSigAllNodes" SG_ 2151063552 IntrStopAlrtCsSetReq 1;
BA_ "GenSigSendType" SG_ 2151063552 CntdVehBrAltCsStReq 10;
BA_ "SignalType" SG_ 2151063552 CntdVehBrAltCsStReq "ENM";
BA_ "SignalLongName" SG_ 2151063552 CntdVehBrAltCsStReq "Connected Vehicle Braking Alerts Customization Setting Request";
BA_ "VNSigAllNodes" SG_ 2151063552 CntdVehBrAltCsStReq 1;
BA_ "GenSigSendType" SG_ 2151063552 TrgdVidRecSwAct 10;
BA_ "SignalType" SG_ 2151063552 TrgdVidRecSwAct "BLN";
BA_ "SignalLongName" SG_ 2151063552 TrgdVidRecSwAct "Triggered Video Recorder Switch Active";
BA_ "VNSigAllNodes" SG_ 2151063552 TrgdVidRecSwAct 1;
BA_ "GenSigDeltaValue" SG_ 2151063552 ICSTS_Y1TchCrdnt 1;
BA_ "GenSigSendType" SG_ 2151063552 ICSTS_Y1TchCrdnt 12;
BA_ "PacketOrder" SG_ 2151063552 ICSTS_Y1TchCrdnt 3;
BA_ "SignalType" SG_ 2151063552 ICSTS_Y1TchCrdnt "UNM";
BA_ "SignalLongName" SG_ 2151063552 ICSTS_Y1TchCrdnt "Integrated Center Stack Touch Status : Y1 Touch Coordinate";
BA_ "VNSigAllNodes" SG_ 2151063552 ICSTS_Y1TchCrdnt 1;
BA_ "GenSigDeltaValue" SG_ 2151063552 ICSTS_X1TchCrdnt 1;
BA_ "GenSigSendType" SG_ 2151063552 ICSTS_X1TchCrdnt 12;
BA_ "PacketOrder" SG_ 2151063552 ICSTS_X1TchCrdnt 2;
BA_ "SignalType" SG_ 2151063552 ICSTS_X1TchCrdnt "UNM";
BA_ "SignalLongName" SG_ 2151063552 ICSTS_X1TchCrdnt "Integrated Center Stack Touch Status : X1 Touch Coordinate";
BA_ "VNSigAllNodes" SG_ 2151063552 ICSTS_X1TchCrdnt 1;
BA_ "GenSigSendType" SG_ 2151063552 ICSTS_TchPrxmty 10;
BA_ "PacketOrder" SG_ 2151063552 ICSTS_TchPrxmty 1;
BA_ "SignalType" SG_ 2151063552 ICSTS_TchPrxmty "ENM";
BA_ "SignalLongName" SG_ 2151063552 ICSTS_TchPrxmty "Integrated Center Stack Touch Status : Touch Proximity";
BA_ "VNSigAllNodes" SG_ 2151063552 ICSTS_TchPrxmty 1;
BA_ "GenSigSendType" SG_ 2151063552 RrPedDetCstStReq 10;
BA_ "SignalType" SG_ 2151063552 RrPedDetCstStReq "ENM";
BA_ "SignalLongName" SG_ 2151063552 RrPedDetCstStReq "Rear Pedestrian Detection Customization Setting Request";
BA_ "VNSigAllNodes" SG_ 2151063552 RrPedDetCstStReq 1;
BA_ "GenSigSendType" SG_ 2151063552 CamVideoICSDispAct 10;
BA_ "SignalType" SG_ 2151063552 CamVideoICSDispAct "BLN";
BA_ "SignalLongName" SG_ 2151063552 CamVideoICSDispAct "Camera Video ICS Display Active";
BA_ "VNSigAllNodes" SG_ 2151063552 CamVideoICSDispAct 1;
BA_ "GenSigSendType" SG_ 2151063552 Frnt360CamSwAct 10;
BA_ "SignalType" SG_ 2151063552 Frnt360CamSwAct "BLN";
BA_ "SignalLongName" SG_ 2151063552 Frnt360CamSwAct "Front 360 Camera Switch Active";
BA_ "VNSigAllNodes" SG_ 2151063552 Frnt360CamSwAct 1;
BA_ "GenSigSendType" SG_ 2151063552 InftnOprAlwd 10;
BA_ "GenSigSendOnInit" SG_ 2151063552 InftnOprAlwd 1;
BA_ "VNSigInfotainment" SG_ 2151063552 InftnOprAlwd 1;
BA_ "SignalType" SG_ 2151063552 InftnOprAlwd "BLN";
BA_ "SignalLongName" SG_ 2151063552 InftnOprAlwd "Infotainment Operation Allowed";
BA_ "VNSigAllNodes" SG_ 2151063552 InftnOprAlwd 1;
BA_ "GenSigSendType" SG_ 2151063552 ValetMdAct 10;
BA_ "VNSigInfotainment" SG_ 2151063552 ValetMdAct 1;
BA_ "SignalType" SG_ 2151063552 ValetMdAct "BLN";
BA_ "SignalLongName" SG_ 2151063552 ValetMdAct "Valet Mode Active";
BA_ "VNSigAllNodes" SG_ 2151063552 ValetMdAct 1;
BA_ "SignalType" SG_ 2149646336 VehSpdAvgDrvnSrc "ENM";
BA_ "SignalLongName" SG_ 2149646336 VehSpdAvgDrvnSrc "Vehicle Speed Average Driven Source";
BA_ "VNSigAllNodes" SG_ 2149646336 VehSpdAvgDrvnSrc 1;
BA_ "SignalType" SG_ 2149646336 VehSpdAvgNDrvnV "ENM";
BA_ "SignalLongName" SG_ 2149646336 VehSpdAvgNDrvnV "Vehicle Speed Average Non Driven Validity";
BA_ "VNSigAllNodes" SG_ 2149646336 VehSpdAvgNDrvnV 1;
BA_ "GenSigSendOnInit" SG_ 2149646336 VehSpdAvgNDrvn 1;
BA_ "SignalType" SG_ 2149646336 VehSpdAvgNDrvn "UNM";
BA_ "SignalLongName" SG_ 2149646336 VehSpdAvgNDrvn "Vehicle Speed Average Non Driven";
BA_ "VNSigAllNodes" SG_ 2149646336 VehSpdAvgNDrvn 1;
BA_ "SignalType" SG_ 2149646336 DstRolCntAvgNonDrvnV "ENM";
BA_ "SignalLongName" SG_ 2149646336 DstRolCntAvgNonDrvnV "Distance Rolling Count Average Non Driven Validity";
BA_ "VNSigAllNodes" SG_ 2149646336 DstRolCntAvgNonDrvnV 1;
BA_ "SignalType" SG_ 2149646336 DstRolCntAvNDrRstOc "BLN";
BA_ "SignalLongName" SG_ 2149646336 DstRolCntAvNDrRstOc "Distance Rolling Count Average Non Driven Reset Occurred";
BA_ "VNSigAllNodes" SG_ 2149646336 DstRolCntAvNDrRstOc 1;
BA_ "SignalType" SG_ 2149646336 DstRolCntAvgNonDrvn "UNM";
BA_ "SignalLongName" SG_ 2149646336 DstRolCntAvgNonDrvn "Distance Rolling Count Average Non Driven";
BA_ "VNSigAllNodes" SG_ 2149646336 DstRolCntAvgNonDrvn 1;
BA_ "SignalType" SG_ 2149646336 DstRolCntAvgDrnRstOc "BLN";
BA_ "SignalLongName" SG_ 2149646336 DstRolCntAvgDrnRstOc "Distance Rolling Count Average Driven Reset Occurred";
BA_ "VNSigAllNodes" SG_ 2149646336 DstRolCntAvgDrnRstOc 1;
BA_ "SignalType" SG_ 2149646336 DistRollCntAvgDrvnV "ENM";
BA_ "SignalLongName" SG_ 2149646336 DistRollCntAvgDrvnV "Distance Rolling Count Average Driven Validity";
BA_ "VNSigAllNodes" SG_ 2149646336 DistRollCntAvgDrvnV 1;
BA_ "SignalType" SG_ 2149646336 DistRollCntAvgDrvnSrc "ENM";
BA_ "SignalLongName" SG_ 2149646336 DistRollCntAvgDrvnSrc "Distance Rolling Count Average Driven Source";
BA_ "VNSigAllNodes" SG_ 2149646336 DistRollCntAvgDrvnSrc 1;
BA_ "SignalType" SG_ 2149646336 DistRollCntAvgDrvn "UNM";
BA_ "SignalLongName" SG_ 2149646336 DistRollCntAvgDrvn "Distance Rolling Count Average Driven";
BA_ "VNSigAllNodes" SG_ 2149646336 DistRollCntAvgDrvn 1;
BA_ "SignalType" SG_ 2149646336 VehSpdAvgDrvnV "ENM";
BA_ "SignalLongName" SG_ 2149646336 VehSpdAvgDrvnV "Vehicle Speed Average Driven Validity";
BA_ "VNSigAllNodes" SG_ 2149646336 VehSpdAvgDrvnV 1;
BA_ "SignalType" SG_ 2149646336 VehSpdAvgDrvn "UNM";
BA_ "SignalLongName" SG_ 2149646336 VehSpdAvgDrvn "Vehicle Speed Average Driven";
BA_ "VNSigAllNodes" SG_ 2149646336 VehSpdAvgDrvn 1;
BA_ "GenSigSendType" SG_ 2154905600 DrvSeatPrsMemID 10;
BA_ "SignalType" SG_ 2154905600 DrvSeatPrsMemID "ENM";
BA_ "SignalLongName" SG_ 2154905600 DrvSeatPrsMemID "Driver Seat Personalization Memory ID";
BA_ "GenSigStartValue" SG_ 2154905600 DrvSeatPrsMemID 7;
BA_ "VNSigAllNodes" SG_ 2154905600 DrvSeatPrsMemID 1;
BA_ "GenSigSendType" SG_ 2154905600 DrId 10;
BA_ "GenSigSendOnInit" SG_ 2154905600 DrId 1;
BA_ "VNSigInfotainment" SG_ 2154905600 DrId 1;
BA_ "SignalType" SG_ 2154905600 DrId "ENM";
BA_ "SignalLongName" SG_ 2154905600 DrId "Driver Identifier";
BA_ "GenSigStartValue" SG_ 2154905600 DrId 7;
BA_ "VNSigAllNodes" SG_ 2154905600 DrId 1;
BA_ "GenSigDeltaValue" SG_ 2155954176 ClmCntRrBlwFnSp 1;
BA_ "GenSigSendType" SG_ 2155954176 ClmCntRrBlwFnSp 12;
BA_ "GenSigSendOnInit" SG_ 2155954176 ClmCntRrBlwFnSp 2;
BA_ "SignalType" SG_ 2155954176 ClmCntRrBlwFnSp "UNM";
BA_ "SignalLongName" SG_ 2155954176 ClmCntRrBlwFnSp "Climate Control Rear Blower Fan Speed";
BA_ "VNSigAllNodes" SG_ 2155954176 ClmCntRrBlwFnSp 1;
BA_ "GenSigSendType" SG_ 2155954176 ClmCntlExtDefActIO 10;
BA_ "GenSigSendOnInit" SG_ 2155954176 ClmCntlExtDefActIO 2;
BA_ "SignalType" SG_ 2155954176 ClmCntlExtDefActIO "BLN";
BA_ "SignalLongName" SG_ 2155954176 ClmCntlExtDefActIO "Climate Control Extended Defrost Active Indication On";
BA_ "VNSigAllNodes" SG_ 2155954176 ClmCntlExtDefActIO 1;
BA_ "GenSigSendType" SG_ 2155954176 ClntCircPmpRq 10;
BA_ "GenSigSendOnInit" SG_ 2155954176 ClntCircPmpRq 2;
BA_ "VNSigIntermediate" SG_ 2155954176 ClntCircPmpRq 1;
BA_ "SignalType" SG_ 2155954176 ClntCircPmpRq "ENM";
BA_ "SignalLongName" SG_ 2155954176 ClntCircPmpRq "Coolant Circulation Pump Request";
BA_ "VNSigAllNodes" SG_ 2155954176 ClntCircPmpRq 1;
BA_ "GenSigSendType" SG_ 2155954176 ClimCtrlAftBlowModActv 10;
BA_ "GenSigSendOnInit" SG_ 2155954176 ClimCtrlAftBlowModActv 1;
BA_ "VNSigIntermediate" SG_ 2155954176 ClimCtrlAftBlowModActv 1;
BA_ "SignalType" SG_ 2155954176 ClimCtrlAftBlowModActv "BLN";
BA_ "SignalLongName" SG_ 2155954176 ClimCtrlAftBlowModActv "Climate Control Afterblow Mode Active";
BA_ "VNSigAllNodes" SG_ 2155954176 ClimCtrlAftBlowModActv 1;
BA_ "GenSigDeltaValue" SG_ 2155954176 ClmCntFrBlwFnSp 1;
BA_ "GenSigSendType" SG_ 2155954176 ClmCntFrBlwFnSp 12;
BA_ "GenSigSendOnInit" SG_ 2155954176 ClmCntFrBlwFnSp 2;
BA_ "VNSigIntermediate" SG_ 2155954176 ClmCntFrBlwFnSp 1;
BA_ "SignalType" SG_ 2155954176 ClmCntFrBlwFnSp "UNM";
BA_ "SignalLongName" SG_ 2155954176 ClmCntFrBlwFnSp "Climate Control Front Blower Fan Speed";
BA_ "VNSigAllNodes" SG_ 2155954176 ClmCntFrBlwFnSp 1;
BA_ "GenSigSendType" SG_ 2155954176 ACHtIdleBstLevReq 10;
BA_ "GenSigSendOnInit" SG_ 2155954176 ACHtIdleBstLevReq 1;
BA_ "SignalType" SG_ 2155954176 ACHtIdleBstLevReq "ENM";
BA_ "SignalLongName" SG_ 2155954176 ACHtIdleBstLevReq "Air Conditioning and Heating Idle Boost Level Request";
BA_ "VNSigAllNodes" SG_ 2155954176 ACHtIdleBstLevReq 1;
BA_ "GenSigDeltaValue" SG_ 2155954176 AirCndCmptLdEst 1;
BA_ "GenSigSendType" SG_ 2155954176 AirCndCmptLdEst 12;
BA_ "GenSigSendOnInit" SG_ 2155954176 AirCndCmptLdEst 2;
BA_ "SignalType" SG_ 2155954176 AirCndCmptLdEst "UNM";
BA_ "SignalLongName" SG_ 2155954176 AirCndCmptLdEst "Air Conditioning Compartment Load Estimated";
BA_ "VNSigAllNodes" SG_ 2155954176 AirCndCmptLdEst 1;
BA_ "GenSigSendType" SG_ 2155954176 AirCndActIO 10;
BA_ "GenSigSendOnInit" SG_ 2155954176 AirCndActIO 2;
BA_ "SignalType" SG_ 2155954176 AirCndActIO "BLN";
BA_ "SignalLongName" SG_ 2155954176 AirCndActIO "Air Conditioning Active Indication On";
BA_ "VNSigAllNodes" SG_ 2155954176 AirCndActIO 1;
BA_ "SignalType" SG_ 2155421696 PsvEntAprchDrctn "ENM";
BA_ "SignalLongName" SG_ 2155421696 PsvEntAprchDrctn "Passive Entry Approach Direction";
BA_ "VNSigAllNodes" SG_ 2155421696 PsvEntAprchDrctn 1;
BA_ "SignalType" SG_ 2155421696 PsvEntApprchDtcd "BLN";
BA_ "SignalLongName" SG_ 2155421696 PsvEntApprchDtcd "Passive Entry Approach Detected";
BA_ "VNSigAllNodes" SG_ 2155421696 PsvEntApprchDtcd 1;
BA_ "SignalType" SG_ 2155421696 PsvEntApprchCnfgReq "ENM";
BA_ "SignalLongName" SG_ 2155421696 PsvEntApprchCnfgReq "Passive Entry Approach Configuration Request";
BA_ "VNSigAllNodes" SG_ 2155421696 PsvEntApprchCnfgReq 1;
BA_ "SignalType" SG_ 2155421696 ServKylsStSysIO "BLN";
BA_ "SignalLongName" SG_ 2155421696 ServKylsStSysIO "Service Keyless Start System Indication On";
BA_ "VNSigAllNodes" SG_ 2155421696 ServKylsStSysIO 1;
BA_ "SignalType" SG_ 2155421696 PsvEntChlng "UNM";
BA_ "SignalLongName" SG_ 2155421696 PsvEntChlng "Passive Entry Challenge";
BA_ "VNSigAllNodes" SG_ 2155421696 PsvEntChlng 1;
BA_ "GenSigSendType" SG_ 2153938944 RmtRflshMdReqtd 10;
BA_ "VNSigRemoteDiagnostics" SG_ 2153938944 RmtRflshMdReqtd 1;
BA_ "SignalType" SG_ 2153938944 RmtRflshMdReqtd "BLN";
BA_ "SignalLongName" SG_ 2153938944 RmtRflshMdReqtd "Remote Reflash Mode Requested";
BA_REL_ "GenSigSuprvResp" BU_SG_REL_ VCU_LE SG_ 2149826560 SpdLmtVsnFsdSpd 1;
BA_REL_ "GenSigSuprvResp" BU_SG_REL_ IPC_LE SG_ 2149826560 SpdLmtVsnFsdSpd 1;
BA_REL_ "GenSigSuprvResp" BU_SG_REL_ CHUD_LE SG_ 2149826560 FwdClnAlrtPr11E 1;
BA_REL_ "GenSigSuprvResp" BU_SG_REL_ HUD_LE SG_ 2149826560 FwdClnAlrtPr11E 1;
BA_REL_ "GenSigSuprvResp" BU_SG_REL_ VCU_LE SG_ 2149711872 SetSpdLmtRchd 1;
BA_REL_ "GenSigSuprvResp" BU_SG_REL_ IPC_LE SG_ 2149711872 SetSpdLmtRchd 1;
BA_REL_ "GenSigSuprvResp" BU_SG_REL_ V2V_LE SG_ 2149711872 FwdClnAlrtPr 1;
BA_REL_ "GenSigSuprvResp" BU_SG_REL_ CHUD_LE SG_ 2149711872 FwdClnAlrtPr 1;
BA_REL_ "GenSigSuprvResp" BU_SG_REL_ HUD_LE SG_ 2149711872 FwdClnAlrtPr 1;
BA_REL_ "GenSigSuprvResp" BU_SG_REL_ CHUD_LE SG_ 2149711872 ACCHdwyStg 1;
BA_REL_ "GenSigSuprvResp" BU_SG_REL_ HUD_LE SG_ 2149711872 ACCHdwyStg 1;
BA_REL_ "GenSigSuprvResp" BU_SG_REL_ CHUD_LE SG_ 2149711872 ACCDrvrSeltdSpd 1;
BA_REL_ "GenSigSuprvResp" BU_SG_REL_ HUD_LE SG_ 2149711872 ACCDrvrSeltdSpd 1;
BA_REL_ "GenSigSuprvResp" BU_SG_REL_ VPM_LE SG_ 2149711872 VehDynYawRate 1;
BA_REL_ "GenSigSuprvResp" BU_SG_REL_ VCU_LE SG_ 2149711872 VehDynYawRate 1;
BA_REL_ "GenSigSuprvResp" BU_SG_REL_ IPC_LE SG_ 2149711872 VehDynYawRate 1;
BA_REL_ "GenSigSuprvResp" BU_SG_REL_ V2V_LE SG_ 2149711872 ACCAct370 1;
BA_REL_ "GenSigSuprvResp" BU_SG_REL_ CHUD_LE SG_ 2149711872 ACCAct370 1;
BA_REL_ "GenSigSuprvResp" BU_SG_REL_ HUD_LE SG_ 2149711872 ACCAct370 1;
BA_REL_ "GenSigSuprvResp" BU_SG_REL_ VCU_LE SG_ 2149711872 AutoMdSpdLmtStat 1;
BA_REL_ "GenSigSuprvResp" BU_SG_REL_ IPC_LE SG_ 2149711872 AutoMdSpdLmtStat 1;
BA_REL_ "GenSigSuprvResp" BU_SG_REL_ VCU_LE SG_ 2149711872 ACCAutoSetSpdStat 1;
BA_REL_ "GenSigSuprvResp" BU_SG_REL_ IPC_LE SG_ 2149711872 ACCAutoSetSpdStat 1;
BA_REL_ "GenSigSuprvResp" BU_SG_REL_ VPM_LE SG_ 2149629952 RtTrnLmpOn 1;
BA_REL_ "GenSigSuprvResp" BU_SG_REL_ VPM_LE SG_ 2149629952 LftTrnLmpOn 1;
BA_REL_ "GenSigSuprvResp" BU_SG_REL_ VCU_LE SG_ 2149629952 FrFogLmpsAct 1;
BA_REL_ "GenSigTimeoutMsg" BU_SG_REL_ VCU_LE SG_ 2149629952 FrFogLmpsAct 262;
BA_REL_ "GenSigSuprvResp" BU_SG_REL_ RadioHead_LE SG_ 2149629952 FrFogLmpsAct 1;
BA_REL_ "GenSigTimeoutMsg" BU_SG_REL_ RadioHead_LE SG_ 2149629952 FrFogLmpsAct 262;
BA_REL_ "GenSigSuprvResp" BU_SG_REL_ V2V_LE SG_ 2149629952 HiBmReqd 1;
BA_REL_ "GenSigSuprvResp" BU_SG_REL_ V2V_LE SG_ 2149629952 PrkLtRightOn 1;
BA_REL_ "GenSigSuprvResp" BU_SG_REL_ V2V_LE SG_ 2149629952 PrkLtLeftOn 1;
BA_REL_ "GenSigSuprvResp" BU_SG_REL_ VPM_LE SG_ 2149629952 TrnSwAct 1;
BA_REL_ "GenSigSuprvResp" BU_SG_REL_ RadioHead_LE SG_ 2149629952 TrnSwAct 1;
BA_REL_ "GenSigTimeoutMsg" BU_SG_REL_ RadioHead_LE SG_ 2149629952 TrnSwAct 262;
BA_REL_ "GenSigSuprvResp" BU_SG_REL_ VCU_LE SG_ 2149629952 TrnSwAct 1;
BA_REL_ "GenSigTimeoutMsg" BU_SG_REL_ VCU_LE SG_ 2149629952 TrnSwAct 262;
BA_REL_ "GenSigSuprvResp" BU_SG_REL_ VCU_LE SG_ 2149629952 MainLghtSw 1;
BA_REL_ "GenSigTimeoutMsg" BU_SG_REL_ VCU_LE SG_ 2149629952 MainLghtSw 262;
BA_REL_ "GenSigSuprvResp" BU_SG_REL_ RadioHead_LE SG_ 2149629952 MainLghtSw 1;
BA_REL_ "GenSigTimeoutMsg" BU_SG_REL_ RadioHead_LE SG_ 2149629952 MainLghtSw 262;
BA_REL_ "GenSigSuprvResp" BU_SG_REL_ V2V_LE SG_ 2149629952 HazSwAtv 1;
BA_REL_ "GenSigSuprvResp" BU_SG_REL_ VCU_LE SG_ 2149629952 HazSwAtv 1;
BA_REL_ "GenSigTimeoutMsg" BU_SG_REL_ VCU_LE SG_ 2149629952 HazSwAtv 262;
BA_REL_ "GenSigSuprvResp" BU_SG_REL_ RadioHead_LE SG_ 2149629952 HazSwAtv 1;
BA_REL_ "GenSigTimeoutMsg" BU_SG_REL_ RadioHead_LE SG_ 2149629952 HazSwAtv 262;
BA_REL_ "GenSigSuprvResp" BU_SG_REL_ RadioHead_LE SG_ 2149629952 HiBmIO 1;
BA_REL_ "GenSigTimeoutMsg" BU_SG_REL_ RadioHead_LE SG_ 2149629952 HiBmIO 262;
BA_REL_ "GenSigSuprvResp" BU_SG_REL_ VCU_LE SG_ 2149629952 HiBmIO 1;
BA_REL_ "GenSigTimeoutMsg" BU_SG_REL_ VCU_LE SG_ 2149629952 HiBmIO 262;
BA_REL_ "GenSigSuprvResp" BU_SG_REL_ VCU_LE SG_ 2149629952 HiBmIO 1;
BA_REL_ "GenSigSuprvResp" BU_SG_REL_ IPC_LE SG_ 2149629952 HiBmIO 1;
BA_REL_ "GenSigSuprvResp" BU_SG_REL_ V2V_LE SG_ 2149629952 FrFgLtIO 1;
BA_REL_ "GenSigSuprvResp" BU_SG_REL_ RadioHead_LE SG_ 2149629952 FrFgLtIO 1;
BA_REL_ "GenSigTimeoutMsg" BU_SG_REL_ RadioHead_LE SG_ 2149629952 FrFgLtIO 262;
BA_REL_ "GenSigSuprvResp" BU_SG_REL_ VCU_LE SG_ 2149629952 FrFgLtIO 1;
BA_REL_ "GenSigTimeoutMsg" BU_SG_REL_ VCU_LE SG_ 2149629952 FrFgLtIO 262;
BA_REL_ "GenSigSuprvResp" BU_SG_REL_ VPM_LE SG_ 2149629952 LftTrnLmpAtv 1;
BA_REL_ "GenSigSuprvResp" BU_SG_REL_ V2V_LE SG_ 2149629952 LftTrnLmpAtv 1;
BA_REL_ "GenSigSuprvResp" BU_SG_REL_ RadioHead_LE SG_ 2149629952 LftTrnLmpAtv 1;
BA_REL_ "GenSigTimeoutMsg" BU_SG_REL_ RadioHead_LE SG_ 2149629952 LftTrnLmpAtv 262;
BA_REL_ "GenSigSuprvResp" BU_SG_REL_ VCU_LE SG_ 2149629952 LftTrnLmpAtv 1;
BA_REL_ "GenSigTimeoutMsg" BU_SG_REL_ VCU_LE SG_ 2149629952 LftTrnLmpAtv 262;
BA_REL_ "GenSigSuprvResp" BU_SG_REL_ VPM_LE SG_ 2149629952 RtTrnLmpAtv 1;
BA_REL_ "GenSigSuprvResp" BU_SG_REL_ V2V_LE SG_ 2149629952 RtTrnLmpAtv 1;
BA_REL_ "GenSigSuprvResp" BU_SG_REL_ RadioHead_LE SG_ 2149629952 RtTrnLmpAtv 1;
BA_REL_ "GenSigTimeoutMsg" BU_SG_REL_ RadioHead_LE SG_ 2149629952 RtTrnLmpAtv 262;
BA_REL_ "GenSigSuprvResp" BU_SG_REL_ VCU_LE SG_ 2149629952 RtTrnLmpAtv 1;
BA_REL_ "GenSigTimeoutMsg" BU_SG_REL_ VCU_LE SG_ 2149629952 RtTrnLmpAtv 262;
BA_REL_ "GenSigSuprvResp" BU_SG_REL_ V2V_LE SG_ 2149629952 RevLmpAtv 1;
BA_REL_ "GenSigSuprvResp" BU_SG_REL_ VCU_LE SG_ 2149629952 RevLmpAtv 1;
BA_REL_ "GenSigTimeoutMsg" BU_SG_REL_ VCU_LE SG_ 2149629952 RevLmpAtv 262;
BA_REL_ "GenSigSuprvResp" BU_SG_REL_ RadioHead_LE SG_ 2149629952 RevLmpAtv 1;
BA_REL_ "GenSigTimeoutMsg" BU_SG_REL_ RadioHead_LE SG_ 2149629952 RevLmpAtv 262;
BA_REL_ "GenSigSuprvResp" BU_SG_REL_ V2V_LE SG_ 2149629952 HdlmpBmSelectStat 1;
BA_REL_ "GenSigSuprvResp" BU_SG_REL_ VCU_LE SG_ 2149629952 HdlmpBmSelectStat 1;
BA_REL_ "GenSigTimeoutMsg" BU_SG_REL_ VCU_LE SG_ 2149629952 HdlmpBmSelectStat 262;
BA_REL_ "GenSigSuprvResp" BU_SG_REL_ RadioHead_LE SG_ 2149629952 HdlmpBmSelectStat 1;
BA_REL_ "GenSigTimeoutMsg" BU_SG_REL_ RadioHead_LE SG_ 2149629952 HdlmpBmSelectStat 262;
BA_REL_ "GenSigSuprvResp" BU_SG_REL_ VCU_LE SG_ 2149629952 RrFogLmpsAct 1;
BA_REL_ "GenSigTimeoutMsg" BU_SG_REL_ VCU_LE SG_ 2149629952 RrFogLmpsAct 262;
BA_REL_ "GenSigSuprvResp" BU_SG_REL_ RadioHead_LE SG_ 2149629952 RrFogLmpsAct 1;
BA_REL_ "GenSigTimeoutMsg" BU_SG_REL_ RadioHead_LE SG_ 2149629952 RrFogLmpsAct 262;
BA_REL_ "GenSigSuprvResp" BU_SG_REL_ V2V_LE SG_ 2149629952 PrkngLtsAct 1;
BA_REL_ "GenSigSuprvResp" BU_SG_REL_ VCU_LE SG_ 2149629952 PrkngLtsAct 1;
BA_REL_ "GenSigTimeoutMsg" BU_SG_REL_ VCU_LE SG_ 2149629952 PrkngLtsAct 262;
BA_REL_ "GenSigSuprvResp" BU_SG_REL_ RadioHead_LE SG_ 2149629952 PrkngLtsAct 1;
BA_REL_ "GenSigTimeoutMsg" BU_SG_REL_ RadioHead_LE SG_ 2149629952 PrkngLtsAct 262;
BA_REL_ "GenSigSuprvResp" BU_SG_REL_ VCU_LE SG_ 2149629952 BrkLtsAtv 1;
BA_REL_ "GenSigSuprvResp" BU_SG_REL_ RadioHead_LE SG_ 2149629952 BrkLtsAtv 1;
BA_REL_ "GenSigSuprvResp" BU_SG_REL_ V2V_LE SG_ 2149629952 DRLAct 1;
BA_REL_ "GenSigSuprvResp" BU_SG_REL_ VCU_LE SG_ 2153947136 RmtRflshMdAct 1;
BA_REL_ "GenSigSuprvResp" BU_SG_REL_ CSM_LE SG_ 2153947136 RmtRflshMdAct 1;
BA_REL_ "GenSigSuprvResp" BU_SG_REL_ RadioHead_LE SG_ 2153947136 RmtRflshMdAct 1;
BA_REL_ "GenSigSuprvResp" BU_SG_REL_ TCP_LE SG_ 2154627072 AudMstrArbCom 1;
BA_REL_ "GenSigSuprvResp" BU_SG_REL_ UHP_Low_LE SG_ 2154627072 AudMstrArbCom 1;
BA_REL_ "GenSigSuprvResp" BU_SG_REL_ DVB_T_LE SG_ 2154627072 AudMstrArbCom 1;
BA_REL_ "GenSigSuprvResp" BU_SG_REL_ ONSTAR_LE SG_ 2154627072 AudMstrArbCom 1;
BA_REL_ "GenSigSuprvResp" BU_SG_REL_ V2V_LE SG_ 2154692608 LgclAVChnl 1;
BA_REL_ "GenSigSuprvResp" BU_SG_REL_ VCU_LE SG_ 2150703104 AudSysVNoisCompPres 1;
BA_REL_ "GenSigSuprvResp" BU_SG_REL_ RadioHead_LE SG_ 2150703104 AudSysVNoisCompPres 1;
BA_REL_ "GenSigSuprvResp" BU_SG_REL_ VCU_LE SG_ 2150703104 AudSysSurSndSysPres 1;
BA_REL_ "GenSigSuprvResp" BU_SG_REL_ RadioHead_LE SG_ 2150703104 AudSysSurSndSysPres 1;
BA_REL_ "GenSigSuprvResp" BU_SG_REL_ VCU_LE SG_ 2150703104 AudSysDigSigProcPres 1;
BA_REL_ "GenSigSuprvResp" BU_SG_REL_ RadioHead_LE SG_ 2150703104 AudSysDigSigProcPres 1;
BA_REL_ "GenSigSuprvResp" BU_SG_REL_ V2V_LE SG_ 2151718912 ChmVolSt 1;
BA_REL_ "GenSigSuprvResp" BU_SG_REL_ VPM_LE SG_ 2151718912 ChmAct 1;
BA_REL_ "GenSigSuprvResp" BU_SG_REL_ V2V_LE SG_ 2151718912 ChmAct 1;
BA_REL_ "GenSigSuprvResp" BU_SG_REL_ TCP_LE SG_ 2151718912 ChmAct 1;
BA_REL_ "GenSigSuprvResp" BU_SG_REL_ ONSTAR_LE SG_ 2151718912 ChmAct 1;
BA_REL_ "GenSigSuprvResp" BU_SG_REL_ RadioHead_LE SG_ 2151718912 ChmAct 1;
BA_REL_ "GenSigSuprvResp" BU_SG_REL_ VCU_LE SG_ 2151718912 ChmAct 1;
BA_REL_ "GenSigSuprvResp" BU_SG_REL_ TCP_LE SG_ 2155020288 LngSelExt 1;
BA_REL_ "GenSigVBitResp" BU_SG_REL_ VCU_LE SG_ 2149851136 SysPwrMd 1;
BA_REL_ "GenSigSuprvResp" BU_SG_REL_ VCU_LE SG_ 2149851136 SysPwrMd 1;
BA_REL_ "GenSigVBitResp" BU_SG_REL_ CHUD_LE SG_ 2149851136 SysPwrMd 1;
BA_REL_ "GenSigSuprvResp" BU_SG_REL_ CHUD_LE SG_ 2149851136 SysPwrMd 1;
BA_REL_ "GenSigVBitResp" BU_SG_REL_ VKM_LE SG_ 2149851136 SysPwrMd 1;
BA_REL_ "GenSigSuprvResp" BU_SG_REL_ VKM_LE SG_ 2149851136 SysPwrMd 1;
BA_REL_ "GenSigVBitResp" BU_SG_REL_ RCRM_LE SG_ 2149851136 SysPwrMd 1;
BA_REL_ "GenSigSuprvResp" BU_SG_REL_ RCRM_LE SG_ 2149851136 SysPwrMd 1;
BA_REL_ "GenSigVBitResp" BU_SG_REL_ VPM_LE SG_ 2149851136 SysPwrMd 1;
BA_REL_ "GenSigSuprvResp" BU_SG_REL_ VPM_LE SG_ 2149851136 SysPwrMd 1;
BA_REL_ "GenSigVBitResp" BU_SG_REL_ V2V_LE SG_ 2149851136 SysPwrMd 1;
BA_REL_ "GenSigSuprvResp" BU_SG_REL_ V2V_LE SG_ 2149851136 SysPwrMd 1;
BA_REL_ "GenSigVBitResp" BU_SG_REL_ TCP_LE SG_ 2149851136 SysPwrMd 1;
BA_REL_ "GenSigSuprvResp" BU_SG_REL_ TCP_LE SG_ 2149851136 SysPwrMd 1;
BA_REL_ "GenSigVBitResp" BU_SG_REL_ CSM_LE SG_ 2149851136 SysPwrMd 1;
BA_REL_ "GenSigSuprvResp" BU_SG_REL_ CSM_LE SG_ 2149851136 SysPwrMd 1;
BA_REL_ "GenSigVBitResp" BU_SG_REL_ UHP_Low_LE SG_ 2149851136 SysPwrMd 1;
BA_REL_ "GenSigSuprvResp" BU_SG_REL_ UHP_Low_LE SG_ 2149851136 SysPwrMd 1;
BA_REL_ "GenSigVBitResp" BU_SG_REL_ RSC_LE SG_ 2149851136 SysPwrMd 1;
BA_REL_ "GenSigSuprvResp" BU_SG_REL_ RSC_LE SG_ 2149851136 SysPwrMd 1;
BA_REL_ "GenSigVBitResp" BU_SG_REL_ RSA_LE SG_ 2149851136 SysPwrMd 1;
BA_REL_ "GenSigSuprvResp" BU_SG_REL_ RSA_LE SG_ 2149851136 SysPwrMd 1;
BA_REL_ "GenSigVBitResp" BU_SG_REL_ PDIM_LE SG_ 2149851136 SysPwrMd 1;
BA_REL_ "GenSigSuprvResp" BU_SG_REL_ PDIM_LE SG_ 2149851136 SysPwrMd 1;
BA_REL_ "GenSigVBitResp" BU_SG_REL_ OTIM_LE SG_ 2149851136 SysPwrMd 1;
BA_REL_ "GenSigSuprvResp" BU_SG_REL_ OTIM_LE SG_ 2149851136 SysPwrMd 1;
BA_REL_ "GenSigVBitResp" BU_SG_REL_ ICS_LE SG_ 2149851136 SysPwrMd 1;
BA_REL_ "GenSigSuprvResp" BU_SG_REL_ ICS_LE SG_ 2149851136 SysPwrMd 1;
BA_REL_ "GenSigVBitResp" BU_SG_REL_ LVMPC_LE SG_ 2149851136 SysPwrMd 1;
BA_REL_ "GenSigSuprvResp" BU_SG_REL_ LVMPC_LE SG_ 2149851136 SysPwrMd 1;
BA_REL_ "GenSigVBitResp" BU_SG_REL_ LVMNav_LE SG_ 2149851136 SysPwrMd 1;
BA_REL_ "GenSigSuprvResp" BU_SG_REL_ LVMNav_LE SG_ 2149851136 SysPwrMd 1;
BA_REL_ "GenSigVBitResp" BU_SG_REL_ DVB_T_LE SG_ 2149851136 SysPwrMd 1;
BA_REL_ "GenSigSuprvResp" BU_SG_REL_ DVB_T_LE SG_ 2149851136 SysPwrMd 1;
BA_REL_ "GenSigVBitResp" BU_SG_REL_ ONSTAR_LE SG_ 2149851136 SysPwrMd 1;
BA_REL_ "GenSigSuprvResp" BU_SG_REL_ ONSTAR_LE SG_ 2149851136 SysPwrMd 1;
BA_REL_ "GenSigVBitResp" BU_SG_REL_ HUD_LE SG_ 2149851136 SysPwrMd 1;
BA_REL_ "GenSigSuprvResp" BU_SG_REL_ HUD_LE SG_ 2149851136 SysPwrMd 1;
BA_REL_ "GenSigVBitResp" BU_SG_REL_ RadioHead_LE SG_ 2149851136 SysPwrMd 1;
BA_REL_ "GenSigSuprvResp" BU_SG_REL_ RadioHead_LE SG_ 2149851136 SysPwrMd 1;
BA_REL_ "GenSigVBitResp" BU_SG_REL_ CHM_LE SG_ 2149851136 SysPwrMd 1;
BA_REL_ "GenSigSuprvResp" BU_SG_REL_ CHM_LE SG_ 2149851136 SysPwrMd 1;
BA_REL_ "GenSigVBitResp" BU_SG_REL_ AMP_LE SG_ 2149851136 SysPwrMd 1;
BA_REL_ "GenSigSuprvResp" BU_SG_REL_ AMP_LE SG_ 2149851136 SysPwrMd 1;
BA_REL_ "GenSigRxStartValue" BU_SG_REL_ VCU_LE SG_ 2149851136 SysPwrMdV "1";
BA_REL_ "GenSigRxStartValue" BU_SG_REL_ CHUD_LE SG_ 2149851136 SysPwrMdV "1";
BA_REL_ "GenSigRxStartValue" BU_SG_REL_ VKM_LE SG_ 2149851136 SysPwrMdV "1";
BA_REL_ "GenSigRxStartValue" BU_SG_REL_ RCRM_LE SG_ 2149851136 SysPwrMdV "1";
BA_REL_ "GenSigRxStartValue" BU_SG_REL_ VPM_LE SG_ 2149851136 SysPwrMdV "1";
BA_REL_ "GenSigRxStartValue" BU_SG_REL_ V2V_LE SG_ 2149851136 SysPwrMdV "1";
BA_REL_ "GenSigRxStartValue" BU_SG_REL_ TCP_LE SG_ 2149851136 SysPwrMdV "1";
BA_REL_ "GenSigRxStartValue" BU_SG_REL_ CSM_LE SG_ 2149851136 SysPwrMdV "1";
BA_REL_ "GenSigRxStartValue" BU_SG_REL_ UHP_Low_LE SG_ 2149851136 SysPwrMdV "1";
BA_REL_ "GenSigRxStartValue" BU_SG_REL_ RSC_LE SG_ 2149851136 SysPwrMdV "1";
BA_REL_ "GenSigRxStartValue" BU_SG_REL_ RSA_LE SG_ 2149851136 SysPwrMdV "1";
BA_REL_ "GenSigRxStartValue" BU_SG_REL_ PDIM_LE SG_ 2149851136 SysPwrMdV "1";
BA_REL_ "GenSigRxStartValue" BU_SG_REL_ OTIM_LE SG_ 2149851136 SysPwrMdV "1";
BA_REL_ "GenSigRxStartValue" BU_SG_REL_ ICS_LE SG_ 2149851136 SysPwrMdV "1";
BA_REL_ "GenSigRxStartValue" BU_SG_REL_ LVMPC_LE SG_ 2149851136 SysPwrMdV "1";
BA_REL_ "GenSigRxStartValue" BU_SG_REL_ LVMNav_LE SG_ 2149851136 SysPwrMdV "1";
BA_REL_ "GenSigRxStartValue" BU_SG_REL_ DVB_T_LE SG_ 2149851136 SysPwrMdV "1";
BA_REL_ "GenSigRxStartValue" BU_SG_REL_ ONSTAR_LE SG_ 2149851136 SysPwrMdV "1";
BA_REL_ "GenSigRxStartValue" BU_SG_REL_ HUD_LE SG_ 2149851136 SysPwrMdV "1";
BA_REL_ "GenSigRxStartValue" BU_SG_REL_ RadioHead_LE SG_ 2149851136 SysPwrMdV "1";
BA_REL_ "GenSigRxStartValue" BU_SG_REL_ CHM_LE SG_ 2149851136 SysPwrMdV "1";
BA_REL_ "GenSigRxStartValue" BU_SG_REL_ AMP_LE SG_ 2149851136 SysPwrMdV "1";
BA_REL_ "GenSigRxStartValue" BU_SG_REL_ VCU_LE SG_ 2149859328 SysBkUpPwrMdV "1";
BA_REL_ "GenSigRxStartValue" BU_SG_REL_ CHUD_LE SG_ 2149859328 SysBkUpPwrMdV "1";
BA_REL_ "GenSigRxStartValue" BU_SG_REL_ VKM_LE SG_ 2149859328 SysBkUpPwrMdV "1";
BA_REL_ "GenSigRxStartValue" BU_SG_REL_ RCRM_LE SG_ 2149859328 SysBkUpPwrMdV "1";
BA_REL_ "GenSigRxStartValue" BU_SG_REL_ VPM_LE SG_ 2149859328 SysBkUpPwrMdV "1";
BA_REL_ "GenSigRxStartValue" BU_SG_REL_ V2V_LE SG_ 2149859328 SysBkUpPwrMdV "1";
BA_REL_ "GenSigRxStartValue" BU_SG_REL_ TCP_LE SG_ 2149859328 SysBkUpPwrMdV "1";
BA_REL_ "GenSigRxStartValue" BU_SG_REL_ CSM_LE SG_ 2149859328 SysBkUpPwrMdV "1";
BA_REL_ "GenSigRxStartValue" BU_SG_REL_ UHP_Low_LE SG_ 2149859328 SysBkUpPwrMdV "1";
BA_REL_ "GenSigRxStartValue" BU_SG_REL_ RSC_LE SG_ 2149859328 SysBkUpPwrMdV "1";
BA_REL_ "GenSigRxStartValue" BU_SG_REL_ RSA_LE SG_ 2149859328 SysBkUpPwrMdV "1";
BA_REL_ "GenSigRxStartValue" BU_SG_REL_ PDIM_LE SG_ 2149859328 SysBkUpPwrMdV "1";
BA_REL_ "GenSigRxStartValue" BU_SG_REL_ OTIM_LE SG_ 2149859328 SysBkUpPwrMdV "1";
BA_REL_ "GenSigRxStartValue" BU_SG_REL_ ICS_LE SG_ 2149859328 SysBkUpPwrMdV "1";
BA_REL_ "GenSigRxStartValue" BU_SG_REL_ LVMPC_LE SG_ 2149859328 SysBkUpPwrMdV "1";
BA_REL_ "GenSigRxStartValue" BU_SG_REL_ LVMNav_LE SG_ 2149859328 SysBkUpPwrMdV "1";
BA_REL_ "GenSigRxStartValue" BU_SG_REL_ DVB_T_LE SG_ 2149859328 SysBkUpPwrMdV "1";
BA_REL_ "GenSigRxStartValue" BU_SG_REL_ ONSTAR_LE SG_ 2149859328 SysBkUpPwrMdV "1";
BA_REL_ "GenSigRxStartValue" BU_SG_REL_ HUD_LE SG_ 2149859328 SysBkUpPwrMdV "1";
BA_REL_ "GenSigRxStartValue" BU_SG_REL_ RadioHead_LE SG_ 2149859328 SysBkUpPwrMdV "1";
BA_REL_ "GenSigRxStartValue" BU_SG_REL_ CHM_LE SG_ 2149859328 SysBkUpPwrMdV "1";
BA_REL_ "GenSigRxStartValue" BU_SG_REL_ AMP_LE SG_ 2149859328 SysBkUpPwrMdV "1";
BA_REL_ "GenSigRxStartValue" BU_SG_REL_ VCU_LE SG_ 2149859328 SysBkupPwrMdEn "0";
BA_REL_ "GenSigSuprvResp" BU_SG_REL_ VCU_LE SG_ 2149859328 SysBkupPwrMdEn 1;
BA_REL_ "GenSigRxStartValue" BU_SG_REL_ CHUD_LE SG_ 2149859328 SysBkupPwrMdEn "0";
BA_REL_ "GenSigSuprvResp" BU_SG_REL_ CHUD_LE SG_ 2149859328 SysBkupPwrMdEn 1;
BA_REL_ "GenSigRxStartValue" BU_SG_REL_ VKM_LE SG_ 2149859328 SysBkupPwrMdEn "0";
BA_REL_ "GenSigSuprvResp" BU_SG_REL_ VKM_LE SG_ 2149859328 SysBkupPwrMdEn 1;
BA_REL_ "GenSigRxStartValue" BU_SG_REL_ RCRM_LE SG_ 2149859328 SysBkupPwrMdEn "0";
BA_REL_ "GenSigSuprvResp" BU_SG_REL_ RCRM_LE SG_ 2149859328 SysBkupPwrMdEn 1;
BA_REL_ "GenSigRxStartValue" BU_SG_REL_ VPM_LE SG_ 2149859328 SysBkupPwrMdEn "0";
BA_REL_ "GenSigSuprvResp" BU_SG_REL_ VPM_LE SG_ 2149859328 SysBkupPwrMdEn 1;
BA_REL_ "GenSigRxStartValue" BU_SG_REL_ V2V_LE SG_ 2149859328 SysBkupPwrMdEn "0";
BA_REL_ "GenSigSuprvResp" BU_SG_REL_ V2V_LE SG_ 2149859328 SysBkupPwrMdEn 1;
BA_REL_ "GenSigRxStartValue" BU_SG_REL_ TCP_LE SG_ 2149859328 SysBkupPwrMdEn "0";
BA_REL_ "GenSigSuprvResp" BU_SG_REL_ TCP_LE SG_ 2149859328 SysBkupPwrMdEn 1;
BA_REL_ "GenSigRxStartValue" BU_SG_REL_ CSM_LE SG_ 2149859328 SysBkupPwrMdEn "0";
BA_REL_ "GenSigSuprvResp" BU_SG_REL_ CSM_LE SG_ 2149859328 SysBkupPwrMdEn 1;
BA_REL_ "GenSigRxStartValue" BU_SG_REL_ UHP_Low_LE SG_ 2149859328 SysBkupPwrMdEn "0";
BA_REL_ "GenSigSuprvResp" BU_SG_REL_ UHP_Low_LE SG_ 2149859328 SysBkupPwrMdEn 1;
BA_REL_ "GenSigRxStartValue" BU_SG_REL_ RSC_LE SG_ 2149859328 SysBkupPwrMdEn "0";
BA_REL_ "GenSigSuprvResp" BU_SG_REL_ RSC_LE SG_ 2149859328 SysBkupPwrMdEn 1;
BA_REL_ "GenSigRxStartValue" BU_SG_REL_ RSA_LE SG_ 2149859328 SysBkupPwrMdEn "0";
BA_REL_ "GenSigSuprvResp" BU_SG_REL_ RSA_LE SG_ 2149859328 SysBkupPwrMdEn 1;
BA_REL_ "GenSigRxStartValue" BU_SG_REL_ PDIM_LE SG_ 2149859328 SysBkupPwrMdEn "0";
BA_REL_ "GenSigSuprvResp" BU_SG_REL_ PDIM_LE SG_ 2149859328 SysBkupPwrMdEn 1;
BA_REL_ "GenSigRxStartValue" BU_SG_REL_ OTIM_LE SG_ 2149859328 SysBkupPwrMdEn "0";
BA_REL_ "GenSigSuprvResp" BU_SG_REL_ OTIM_LE SG_ 2149859328 SysBkupPwrMdEn 1;
BA_REL_ "GenSigRxStartValue" BU_SG_REL_ ICS_LE SG_ 2149859328 SysBkupPwrMdEn "0";
BA_REL_ "GenSigSuprvResp" BU_SG_REL_ ICS_LE SG_ 2149859328 SysBkupPwrMdEn 1;
BA_REL_ "GenSigRxStartValue" BU_SG_REL_ LVMPC_LE SG_ 2149859328 SysBkupPwrMdEn "0";
BA_REL_ "GenSigSuprvResp" BU_SG_REL_ LVMPC_LE SG_ 2149859328 SysBkupPwrMdEn 1;
BA_REL_ "GenSigRxStartValue" BU_SG_REL_ LVMNav_LE SG_ 2149859328 SysBkupPwrMdEn "0";
BA_REL_ "GenSigSuprvResp" BU_SG_REL_ LVMNav_LE SG_ 2149859328 SysBkupPwrMdEn 1;
BA_REL_ "GenSigRxStartValue" BU_SG_REL_ DVB_T_LE SG_ 2149859328 SysBkupPwrMdEn "0";
BA_REL_ "GenSigSuprvResp" BU_SG_REL_ DVB_T_LE SG_ 2149859328 SysBkupPwrMdEn 1;
BA_REL_ "GenSigRxStartValue" BU_SG_REL_ ONSTAR_LE SG_ 2149859328 SysBkupPwrMdEn "0";
BA_REL_ "GenSigSuprvResp" BU_SG_REL_ ONSTAR_LE SG_ 2149859328 SysBkupPwrMdEn 1;
BA_REL_ "GenSigRxStartValue" BU_SG_REL_ HUD_LE SG_ 2149859328 SysBkupPwrMdEn "0";
BA_REL_ "GenSigSuprvResp" BU_SG_REL_ HUD_LE SG_ 2149859328 SysBkupPwrMdEn 1;
BA_REL_ "GenSigRxStartValue" BU_SG_REL_ RadioHead_LE SG_ 2149859328 SysBkupPwrMdEn "0";
BA_REL_ "GenSigSuprvResp" BU_SG_REL_ RadioHead_LE SG_ 2149859328 SysBkupPwrMdEn 1;
BA_REL_ "GenSigRxStartValue" BU_SG_REL_ CHM_LE SG_ 2149859328 SysBkupPwrMdEn "0";
BA_REL_ "GenSigSuprvResp" BU_SG_REL_ CHM_LE SG_ 2149859328 SysBkupPwrMdEn 1;
BA_REL_ "GenSigRxStartValue" BU_SG_REL_ AMP_LE SG_ 2149859328 SysBkupPwrMdEn "0";
BA_REL_ "GenSigSuprvResp" BU_SG_REL_ AMP_LE SG_ 2149859328 SysBkupPwrMdEn 1;
BA_REL_ "GenSigVBitResp" BU_SG_REL_ VCU_LE SG_ 2149859328 SysBkUpPwrMd 1;
BA_REL_ "GenSigSuprvResp" BU_SG_REL_ VCU_LE SG_ 2149859328 SysBkUpPwrMd 1;
BA_REL_ "GenSigVBitResp" BU_SG_REL_ CHUD_LE SG_ 2149859328 SysBkUpPwrMd 1;
BA_REL_ "GenSigSuprvResp" BU_SG_REL_ CHUD_LE SG_ 2149859328 SysBkUpPwrMd 1;
BA_REL_ "GenSigVBitResp" BU_SG_REL_ VKM_LE SG_ 2149859328 SysBkUpPwrMd 1;
BA_REL_ "GenSigSuprvResp" BU_SG_REL_ VKM_LE SG_ 2149859328 SysBkUpPwrMd 1;
BA_REL_ "GenSigVBitResp" BU_SG_REL_ RCRM_LE SG_ 2149859328 SysBkUpPwrMd 1;
BA_REL_ "GenSigSuprvResp" BU_SG_REL_ RCRM_LE SG_ 2149859328 SysBkUpPwrMd 1;
BA_REL_ "GenSigVBitResp" BU_SG_REL_ VPM_LE SG_ 2149859328 SysBkUpPwrMd 1;
BA_REL_ "GenSigSuprvResp" BU_SG_REL_ VPM_LE SG_ 2149859328 SysBkUpPwrMd 1;
BA_REL_ "GenSigVBitResp" BU_SG_REL_ V2V_LE SG_ 2149859328 SysBkUpPwrMd 1;
BA_REL_ "GenSigSuprvResp" BU_SG_REL_ V2V_LE SG_ 2149859328 SysBkUpPwrMd 1;
BA_REL_ "GenSigVBitResp" BU_SG_REL_ TCP_LE SG_ 2149859328 SysBkUpPwrMd 1;
BA_REL_ "GenSigSuprvResp" BU_SG_REL_ TCP_LE SG_ 2149859328 SysBkUpPwrMd 1;
BA_REL_ "GenSigVBitResp" BU_SG_REL_ CSM_LE SG_ 2149859328 SysBkUpPwrMd 1;
BA_REL_ "GenSigSuprvResp" BU_SG_REL_ CSM_LE SG_ 2149859328 SysBkUpPwrMd 1;
BA_REL_ "GenSigVBitResp" BU_SG_REL_ UHP_Low_LE SG_ 2149859328 SysBkUpPwrMd 1;
BA_REL_ "GenSigSuprvResp" BU_SG_REL_ UHP_Low_LE SG_ 2149859328 SysBkUpPwrMd 1;
BA_REL_ "GenSigVBitResp" BU_SG_REL_ RSC_LE SG_ 2149859328 SysBkUpPwrMd 1;
BA_REL_ "GenSigSuprvResp" BU_SG_REL_ RSC_LE SG_ 2149859328 SysBkUpPwrMd 1;
BA_REL_ "GenSigVBitResp" BU_SG_REL_ RSA_LE SG_ 2149859328 SysBkUpPwrMd 1;
BA_REL_ "GenSigSuprvResp" BU_SG_REL_ RSA_LE SG_ 2149859328 SysBkUpPwrMd 1;
BA_REL_ "GenSigVBitResp" BU_SG_REL_ PDIM_LE SG_ 2149859328 SysBkUpPwrMd 1;
BA_REL_ "GenSigSuprvResp" BU_SG_REL_ PDIM_LE SG_ 2149859328 SysBkUpPwrMd 1;
BA_REL_ "GenSigVBitResp" BU_SG_REL_ OTIM_LE SG_ 2149859328 SysBkUpPwrMd 1;
BA_REL_ "GenSigSuprvResp" BU_SG_REL_ OTIM_LE SG_ 2149859328 SysBkUpPwrMd 1;
BA_REL_ "GenSigVBitResp" BU_SG_REL_ ICS_LE SG_ 2149859328 SysBkUpPwrMd 1;
BA_REL_ "GenSigSuprvResp" BU_SG_REL_ ICS_LE SG_ 2149859328 SysBkUpPwrMd 1;
BA_REL_ "GenSigVBitResp" BU_SG_REL_ LVMPC_LE SG_ 2149859328 SysBkUpPwrMd 1;
BA_REL_ "GenSigSuprvResp" BU_SG_REL_ LVMPC_LE SG_ 2149859328 SysBkUpPwrMd 1;
BA_REL_ "GenSigVBitResp" BU_SG_REL_ LVMNav_LE SG_ 2149859328 SysBkUpPwrMd 1;
BA_REL_ "GenSigSuprvResp" BU_SG_REL_ LVMNav_LE SG_ 2149859328 SysBkUpPwrMd 1;
BA_REL_ "GenSigVBitResp" BU_SG_REL_ DVB_T_LE SG_ 2149859328 SysBkUpPwrMd 1;
BA_REL_ "GenSigSuprvResp" BU_SG_REL_ DVB_T_LE SG_ 2149859328 SysBkUpPwrMd 1;
BA_REL_ "GenSigVBitResp" BU_SG_REL_ ONSTAR_LE SG_ 2149859328 SysBkUpPwrMd 1;
BA_REL_ "GenSigSuprvResp" BU_SG_REL_ ONSTAR_LE SG_ 2149859328 SysBkUpPwrMd 1;
BA_REL_ "GenSigVBitResp" BU_SG_REL_ HUD_LE SG_ 2149859328 SysBkUpPwrMd 1;
BA_REL_ "GenSigSuprvResp" BU_SG_REL_ HUD_LE SG_ 2149859328 SysBkUpPwrMd 1;
BA_REL_ "GenSigVBitResp" BU_SG_REL_ RadioHead_LE SG_ 2149859328 SysBkUpPwrMd 1;
BA_REL_ "GenSigSuprvResp" BU_SG_REL_ RadioHead_LE SG_ 2149859328 SysBkUpPwrMd 1;
BA_REL_ "GenSigVBitResp" BU_SG_REL_ CHM_LE SG_ 2149859328 SysBkUpPwrMd 1;
BA_REL_ "GenSigSuprvResp" BU_SG_REL_ CHM_LE SG_ 2149859328 SysBkUpPwrMd 1;
BA_REL_ "GenSigVBitResp" BU_SG_REL_ AMP_LE SG_ 2149859328 SysBkUpPwrMd 1;
BA_REL_ "GenSigSuprvResp" BU_SG_REL_ AMP_LE SG_ 2149859328 SysBkUpPwrMd 1;
BA_REL_ "GenSigSuprvResp" BU_SG_REL_ RCRM_LE SG_ 2155167744 VehMovState 1;
BA_REL_ "GenSigSuprvResp" BU_SG_REL_ VCU_LE SG_ 2155167744 TrStLgMdAtv 1;
BA_REL_ "GenSigSuprvResp" BU_SG_REL_ RadioHead_LE SG_ 2155167744 TrStLgMdAtv 1;
BA_REL_ "GenSigSuprvResp" BU_SG_REL_ ONSTAR_LE SG_ 2155167744 Ky_IdDevPr 1;
BA_REL_ "GenSigSuprvResp" BU_SG_REL_ TCP_LE SG_ 2155167744 Ky_IdDevPr 1;
BA_REL_ "GenSigSuprvResp" BU_SG_REL_ VCU_LE SG_ 2155167744 KylsStrtUseTxPckIO 1;
BA_REL_ "GenSigSuprvResp" BU_SG_REL_ IPC_LE SG_ 2155167744 KylsStrtUseTxPckIO 1;
BA_REL_ "GenSigSuprvResp" BU_SG_REL_ TCP_LE SG_ 2152611840 OBTCReqstrStat 1;
BA_REL_ "GenSigSuprvResp" BU_SG_REL_ TCP_LE SG_ 2152611840 OBTCReqstrID 1;
BA_REL_ "GenSigSuprvResp" BU_SG_REL_ VCU_LE SG_ 2151464960 V2VWrngIndReq 1;
BA_REL_ "GenSigSuprvResp" BU_SG_REL_ IPC_LE SG_ 2151464960 V2VWrngIndReq 1;
BA_REL_ "GenSigSuprvResp" BU_SG_REL_ VCU_LE SG_ 2151464960 V2VWrngDistRemng 1;
BA_REL_ "GenSigSuprvResp" BU_SG_REL_ IPC_LE SG_ 2151464960 V2VWrngDistRemng 1;
BA_REL_ "GenSigSuprvResp" BU_SG_REL_ VCU_LE SG_ 2151464960 V2VWrngDirctn 1;
BA_REL_ "GenSigSuprvResp" BU_SG_REL_ IPC_LE SG_ 2151464960 V2VWrngDirctn 1;
BA_REL_ "GenSigSuprvResp" BU_SG_REL_ VCU_LE SG_ 2153930752 LCWrnIndReq 1;
BA_REL_ "GenSigSuprvResp" BU_SG_REL_ IPC_LE SG_ 2153930752 LCWrnIndReq 1;
BA_REL_ "GenSigSuprvResp" BU_SG_REL_ VCU_LE SG_ 2153930752 LCCDrvrAwrnsIO 1;
BA_REL_ "GenSigSuprvResp" BU_SG_REL_ IPC_LE SG_ 2153930752 LCCDrvrAwrnsIO 1;
BA_REL_ "GenSigSuprvResp" BU_SG_REL_ VCU_LE SG_ 2153930752 LCConvMsgIndreq 1;
BA_REL_ "GenSigSuprvResp" BU_SG_REL_ IPC_LE SG_ 2153930752 LCConvMsgIndreq 1;
BA_REL_ "GenSigSuprvResp" BU_SG_REL_ VCU_LE SG_ 2153930752 LCCIndReq 1;
BA_REL_ "GenSigSuprvResp" BU_SG_REL_ IPC_LE SG_ 2153930752 LCCIndReq 1;
BA_REL_ "GenSigSuprvResp" BU_SG_REL_ VCU_LE SG_ 2153930752 LnCntrngCtlIcnLoctn 1;
BA_REL_ "GenSigSuprvResp" BU_SG_REL_ IPC_LE SG_ 2153930752 LnCntrngCtlIcnLoctn 1;
BA_REL_ "GenSigSuprvResp" BU_SG_REL_ VCU_LE SG_ 2153889792 LCArrwBlk5Offst 1;
BA_REL_ "GenSigSuprvResp" BU_SG_REL_ IPC_LE SG_ 2153889792 LCArrwBlk5Offst 1;
BA_REL_ "GenSigSuprvResp" BU_SG_REL_ VCU_LE SG_ 2153889792 LCArrwBlk5Act 1;
BA_REL_ "GenSigSuprvResp" BU_SG_REL_ IPC_LE SG_ 2153889792 LCArrwBlk5Act 1;
BA_REL_ "GenSigSuprvResp" BU_SG_REL_ VCU_LE SG_ 2153889792 LCArrwBlk4Offst 1;
BA_REL_ "GenSigSuprvResp" BU_SG_REL_ IPC_LE SG_ 2153889792 LCArrwBlk4Offst 1;
BA_REL_ "GenSigSuprvResp" BU_SG_REL_ VCU_LE SG_ 2153889792 LCArrwBlk4Act 1;
BA_REL_ "GenSigSuprvResp" BU_SG_REL_ IPC_LE SG_ 2153889792 LCArrwBlk4Act 1;
BA_REL_ "GenSigSuprvResp" BU_SG_REL_ VCU_LE SG_ 2153889792 LCArrwBlk3Offst 1;
BA_REL_ "GenSigSuprvResp" BU_SG_REL_ IPC_LE SG_ 2153889792 LCArrwBlk3Offst 1;
BA_REL_ "GenSigSuprvResp" BU_SG_REL_ VCU_LE SG_ 2153889792 LCArrwBlk3Act 1;
BA_REL_ "GenSigSuprvResp" BU_SG_REL_ IPC_LE SG_ 2153889792 LCArrwBlk3Act 1;
BA_REL_ "GenSigSuprvResp" BU_SG_REL_ VCU_LE SG_ 2153889792 LCArrwBlk2Offst 1;
BA_REL_ "GenSigSuprvResp" BU_SG_REL_ IPC_LE SG_ 2153889792 LCArrwBlk2Offst 1;
BA_REL_ "GenSigSuprvResp" BU_SG_REL_ VCU_LE SG_ 2153889792 LCArrwBlk2Act 1;
BA_REL_ "GenSigSuprvResp" BU_SG_REL_ IPC_LE SG_ 2153889792 LCArrwBlk2Act 1;
BA_REL_ "GenSigSuprvResp" BU_SG_REL_ VCU_LE SG_ 2153889792 LCArrwBlk1Act 1;
BA_REL_ "GenSigSuprvResp" BU_SG_REL_ IPC_LE SG_ 2153889792 LCArrwBlk1Act 1;
BA_REL_ "GenSigSuprvResp" BU_SG_REL_ TCP_LE SG_ 2151063552 InftnOprAlwd 1;
BA_REL_ "GenSigSuprvResp" BU_SG_REL_ UHP_Low_LE SG_ 2151063552 InftnOprAlwd 1;
BA_REL_ "GenSigSuprvResp" BU_SG_REL_ RSC_LE SG_ 2151063552 InftnOprAlwd 1;
BA_REL_ "GenSigSuprvResp" BU_SG_REL_ PDIM_LE SG_ 2151063552 InftnOprAlwd 1;
BA_REL_ "GenSigSuprvResp" BU_SG_REL_ OTIM_LE SG_ 2151063552 InftnOprAlwd 1;
BA_REL_ "GenSigSuprvResp" BU_SG_REL_ ONSTAR_LE SG_ 2151063552 InftnOprAlwd 1;
BA_REL_ "GenSigSuprvResp" BU_SG_REL_ AMP_LE SG_ 2151063552 InftnOprAlwd 1;
BA_REL_ "GenSigSuprvResp" BU_SG_REL_ ICS_LE SG_ 2151063552 ValetMdAct 1;
BA_REL_ "GenSigVBitResp" BU_SG_REL_ RCRM_LE SG_ 2149646336 VehSpdAvgNDrvn 1;
BA_REL_ "GenSigSuprvResp" BU_SG_REL_ RCRM_LE SG_ 2149646336 VehSpdAvgNDrvn 1;
BA_REL_ "GenSigSuprvResp" BU_SG_REL_ CSM_LE SG_ 2149646336 VehSpdAvgNDrvn 1;
BA_REL_ "GenSigSuprvResp" BU_SG_REL_ ICS_LE SG_ 2149646336 VehSpdAvgNDrvn 1;
BA_REL_ "GenSigSuprvResp" BU_SG_REL_ VCU_LE SG_ 2149646336 VehSpdAvgNDrvn 1;
BA_REL_ "GenSigSuprvResp" BU_SG_REL_ VCU_LE SG_ 2149646336 VehSpdAvgNDrvn 1;
BA_REL_ "GenSigSuprvResp" BU_SG_REL_ RadioHead_LE SG_ 2149646336 VehSpdAvgNDrvn 1;
BA_REL_ "GenSigSuprvResp" BU_SG_REL_ RadioHead_LE SG_ 2149646336 VehSpdAvgNDrvn 1;
BA_REL_ "GenSigSuprvResp" BU_SG_REL_ OTIM_LE SG_ 2149646336 VehSpdAvgDrvn 2;
BA_REL_ "GenSigSuprvResp" BU_SG_REL_ CHUD_LE SG_ 2149646336 VehSpdAvgDrvn 1;
BA_REL_ "GenSigSuprvResp" BU_SG_REL_ HUD_LE SG_ 2149646336 VehSpdAvgDrvn 1;
BA_REL_ "GenSigSuprvResp" BU_SG_REL_ VCU_LE SG_ 2154905600 DrvSeatPrsMemID 1;
BA_REL_ "GenSigSuprvResp" BU_SG_REL_ IPC_LE SG_ 2154905600 DrvSeatPrsMemID 1;
BA_REL_ "GenSigSuprvResp" BU_SG_REL_ CHUD_LE SG_ 2154905600 DrvSeatPrsMemID 1;
BA_REL_ "GenSigSuprvResp" BU_SG_REL_ HUD_LE SG_ 2154905600 DrvSeatPrsMemID 1;
BA_REL_ "GenSigSuprvResp" BU_SG_REL_ RSC_LE SG_ 2155954176 ClmCntlExtDefActIO 1;
BA_REL_ "GenSigSuprvResp" BU_SG_REL_ RSC_LE SG_ 2155954176 ClntCircPmpRq 1;
BA_REL_ "GenSigSuprvResp" BU_SG_REL_ RSC_LE SG_ 2155954176 ClimCtrlAftBlowModActv 1;
BA_REL_ "GenSigSuprvResp" BU_SG_REL_ RSA_LE SG_ 2155954176 ClmCntFrBlwFnSp 1;
BA_REL_ "GenSigSuprvResp" BU_SG_REL_ RSC_LE SG_ 2155954176 ClmCntFrBlwFnSp 1;
BA_REL_ "GenSigSuprvResp" BU_SG_REL_ IPC_LE SG_ 2155954176 ClmCntFrBlwFnSp 1;
BA_REL_ "GenSigSuprvResp" BU_SG_REL_ VCU_LE SG_ 2155954176 ClmCntFrBlwFnSp 1;
BA_REL_ "GenSigSuprvResp" BU_SG_REL_ VCU_LE SG_ 2155954176 ClmCntFrBlwFnSp 1;
BA_REL_ "GenSigSuprvResp" BU_SG_REL_ CSM_LE SG_ 2155954176 ClmCntFrBlwFnSp 1;
BA_REL_ "GenSigSuprvResp" BU_SG_REL_ RadioHead_LE SG_ 2155954176 ClmCntFrBlwFnSp 1;
BA_REL_ "GenSigSuprvResp" BU_SG_REL_ RSC_LE SG_ 2155954176 ACHtIdleBstLevReq 1;
BA_REL_ "GenSigSuprvResp" BU_SG_REL_ RSC_LE SG_ 2155954176 AirCndCmptLdEst 1;
BA_REL_ "GenSigSuprvResp" BU_SG_REL_ RSC_LE SG_ 2155954176 AirCndActIO 1;
VAL_ 2149826560 SpdSignUltdDetdIO 1 "true" 0 "false" ;
VAL_ 2149826560 TrfcSgnMmryIcePosIO 1 "true" 0 "false" ;
VAL_ 2149826560 SpdLmtVsnFsdSpdUnt 0 "km/h" 1 "mph" ;
VAL_ 2149826560 SpdLmtVnFsSpdNwDet 1 "true" 0 "false" ;
VAL_ 2149826560 SpdLmtVsnFsdSpdM 0 "Don't Use Data" 1 "Use Data" ;
VAL_ 2149826560 FOAI_VehAhdIndRq11E 0 "No Alert" 1 "Alert Level 1" 2 "Alert Level 2" 3 "Alert Level 3" ;
VAL_ 2149826560 FOAI_AlrtWrnIndRq11E 0 "No Alert" 1 "Alert Level 1" 2 "Alert Level 2" 3 "Alert Level 3" ;
VAL_ 2149826560 FOAI_AlrtChmIhbRq11E 0 "Allow Chime" 1 "Inhibit Chime" ;
VAL_ 2149826560 FwdClnAlrtOffIO11E 1 "true" 0 "false" ;
VAL_ 2149826560 FwdClnAlrtPr11E 1 "true" 0 "false" ;
VAL_ 2149826560 FCABrkPrflReq 1 "true" 0 "false" ;
VAL_ 2149826560 FCAHdwyStngIO 1 "true" 0 "false" ;
VAL_ 2149826560 FCAGpStng 0 "Off" 1 "Near" 2 "Medium" 3 "Reserved3" 4 "Reserved4" 5 "Reserved5" 6 "Reserved6" 7 "Far" ;
VAL_ 2149826560 FCACrusCtrlCnclReqd 1 "true" 0 "false" ;
VAL_ 2149711872 SetSpdLmtRchd 3 "Reserved" 2 "Low limit reached" 1 "High limit reached" 0 "No limit reached" ;
VAL_ 2149711872 FOAI_VehAhdIndRq 0 "No Alert" 1 "Alert Level 1" 2 "Alert Level 2" 3 "Alert Level 3" ;
VAL_ 2149711872 FOAI_AlrtWrnIndRq 0 "No Alert" 1 "Alert Level 1" 2 "Alert Level 2" 3 "Alert Level 3" ;
VAL_ 2149711872 FOAI_AlrtChmIhbRq 0 "Allow Chime" 1 "Inhibit Chime" ;
VAL_ 2149711872 FwdClnAlrtOffIO 1 "true" 0 "false" ;
VAL_ 2149711872 FwdClnAlrtPr 1 "true" 0 "false" ;
VAL_ 2149711872 VehDynYawRateV 1 "Invalid" 0 "Valid" ;
VAL_ 2149711872 ACCHdwyStg 7 "Headway Setting 7" 6 "Headway Setting 6" 5 "Headway Setting 5" 4 "Headway Setting 4" 3 "Headway Setting 3" 2 "Headway Setting 2" 1 "Headway Setting 1" 0 "Minimum Headway Setting" ;
VAL_ 2149711872 AdapCrsCntVDA 1 "VirtualDeviceAvailable" 0 "VirtualDeviceUnavailable" ;
VAL_ 2149711872 SpdLmtrSpdWrngEnbld 1 "true" 0 "false" ;
VAL_ 2149711872 CrsCntlDrSelSpdAct 1 "true" 0 "false" ;
VAL_ 2149711872 ACCAct370 1 "true" 0 "false" ;
VAL_ 2149711872 SpdLmtrSpdWrngAct 1 "true" 0 "false" ;
VAL_ 2149711872 AutoMdSpdLmtStat 0 "No Speed Limit Change" 1 "Proposed Speed Limit Change" 2 "Accepted Speed Limit Change" 3 "Declined Speed Limit Change" ;
VAL_ 2149711872 ACCAutoSetSpdStat 0 "No Set Speed Change" 1 "Proposed Speed Limit Change" 2 "Accepted Speed Limit Change" 3 "Declined Speed Limit Change" ;
VAL_ 2149629952 RtTrnLmpOn 1 "true" 0 "false" ;
VAL_ 2149629952 LftTrnLmpOn 1 "true" 0 "false" ;
VAL_ 2149629952 FrFogLmpsAct 1 "true" 0 "false" ;
VAL_ 2149629952 HiBmReqd 1 "true" 0 "false" ;
VAL_ 2149629952 PrkLtRightOn 1 "true" 0 "false" ;
VAL_ 2149629952 PrkLtLeftOn 1 "true" 0 "false" ;
VAL_ 2149629952 TrnSwAct 2 "Right" 1 "Left" 0 "No Activation" ;
VAL_ 2149629952 PrkLtRightIO 1 "true" 0 "false" ;
VAL_ 2149629952 MainLghtSw 3 "HEADLAMP" 2 "PARKLAMP" 1 "OFF" 0 "AUTO" ;
VAL_ 2149629952 PrkLtLeftIO 1 "true" 0 "false" ;
VAL_ 2149629952 HazSwAtv 1 "true" 0 "false" ;
VAL_ 2149629952 HiBmIO 1 "true" 0 "false" ;
VAL_ 2149629952 FrFgLtIO 1 "true" 0 "false" ;
VAL_ 2149629952 AutoLtsInactIO 1 "true" 0 "false" ;
VAL_ 2149629952 AutoLtsActIO 1 "true" 0 "false" ;
VAL_ 2149629952 LftTrnLmpAtv 2 "On with telltale" 1 "On without telltale" 0 "Off" ;
VAL_ 2149629952 RtTrnLmpAtv 2 "On with telltale" 1 "On without telltale" 0 "Off" ;
VAL_ 2149629952 RevLmpAtv 1 "true" 0 "false" ;
VAL_ 2149629952 HdlmpBmSelectStat 2 "High Beams" 1 "Low Beams" 0 "Unknown" ;
VAL_ 2149629952 SrvlnceMdAct 1 "true" 0 "false" ;
VAL_ 2149629952 RrFgLtIO 1 "true" 0 "false" ;
VAL_ 2149629952 PrkLtIO 1 "true" 0 "false" ;
VAL_ 2149629952 OtsdAmbtLtLvlStatV 1 "Invalid" 0 "Valid" ;
VAL_ 2149629952 OtsdAmbtLtLvlStat 2 "Day" 1 "Night" 0 "Unknown" ;
VAL_ 2149629952 RrFogLmpsAct 1 "true" 0 "false" ;
VAL_ 2149629952 PrkngLtsAct 1 "true" 0 "false" ;
VAL_ 2149629952 BrkLtsAtv 1 "true" 0 "false" ;
VAL_ 2149629952 AutoBmSlctAllwd 1 "true" 0 "false" ;
VAL_ 2149629952 FlToPsSwAtv 1 "true" 0 "false" ;
VAL_ 2149629952 DRLAct 1 "true" 0 "false" ;
VAL_ 2151047168 HdUpDspAnmtStat 0 "Animation Not Available" 1 "Animation Available" 2 "Welcome Active" 3 "CRANK Active" 4 "RUN Active" 5 "Good Bye Active" ;
VAL_ 2151047168 HUDActv 1 "true" 0 "false" ;
VAL_ 2153947136 RmtRflshMdAct 1 "true" 0 "false" ;
VAL_ 2158067712 TSDUAE_ScrnPrsdRq 1 "true" 0 "false" ;
VAL_ 2158067712 TSDUAE_RotBtnPsh 1 "true" 0 "false" ;
VAL_ 2158067712 TSDUAE_GrphStrkInfRq 70 "Left" 71 "Right" 72 "Next" 73 "Previous" 74 "V-mode" 3 "Enter" 4 "Escape" 5 "Number 0" 6 "Number 1" 7 "Number 2" 8 "Number 3" 9 "Number 4" 10 "Number 5" 11 "Number 6" 12 "Number 7" 13 "Number 8" 14 "Number 9" 15 "Character A" 16 "Character B" 17 "Character C" 18 "Character D" 19 "Character E" 20 "Character F" 21 "Character G" 22 "Character H" 23 "Character I" 24 "Character J" 25 "Character K" 26 "Character L" 27 "Character M" 28 "Character N" 29 "Character O" 30 "Character P" 31 "Character Q" 32 "Character R" 33 "Character S" 34 "Character T" 35 "Character U" 36 "Character V" 37 "Character W" 38 "Character X" 39 "Character Y" 40 "Character Z" 41 "Character a" 42 "Character b" 43 "Character c" 44 "Character d" 45 "Character e" 46 "Character f" 47 "Character g" 48 "Character h" 49 "Character i" 50 "Character j" 51 "Character k" 52 "Character l" 53 "Character m" 54 "Character n" 55 "Character o" 56 "Character p" 57 "Character q" 58 "Character r" 59 "Character s" 60 "Character t" 61 "Character u" 62 "Character v" 63 "Character w" 64 "Character x" 65 "Character y" 66 "Character z" 67 "Undo" 68 "Up" 69 "Down" ;
VAL_ 2158051328 VidSrcUICntrlStat 1 "Active" 0 "Inactive" ;
VAL_ 2158051328 VidMstrDsplyMd 2 "Split Screen" 1 "Full Screen" 0 "No Action" ;
VAL_ 2158051328 VidMstrSrcType 4 "Enhanced Driver Interface" 3 "Auxiliary Device" 2 "Rear Camera" 1 "Television" 0 "Video Supervisor" ;
VAL_ 2158051328 VidMstrArbCmd 3 "Connection Complete" 2 "Disconnect" 1 "Connect" 0 "No Action" ;
VAL_ 2158051328 TVDspCmd 0 "No Action" 1 "TV Image Screen" 2 "TV OSD Screen" ;
VAL_ 2158051328 RmtRcvrTunCmnd 22 "List Request" 21 "Audio Program Service Identifier" 20 "Auto Store" 19 "Station Delta within Program Type" 18 "Scan Program Type Down" 17 "Scan Program Type Up" 16 "Scan Preset Down" 15 "Scan Preset Up" 14 "Scan Down" 13 "Scan Up" 12 "Seek Preset Down" 11 "Seek Preset Up" 10 "Seek Program Type Down" 9 "Seek Program Type Up" 8 "Seek Down" 7 "Seek Up" 6 "Set Preset" 5 "Recall Preset Number" 4 "Program Type Delta" 3 "Program Type" 2 "Station Delta" 1 "Station" 0 "No Action" ;
VAL_ 2158051328 RemRcvrSrcInpCmd 3 "Auxiliary Jack 2" 2 "Auxiliary Jack 1" 1 "Television" 0 "No Action" ;
VAL_ 2158034944 VidSrcCompFormatER 8 "ATSC" 7 "DMB" 6 "DTMB" 5 "ISBD-T" 4 "DVB-T" 3 "SECAM" 2 "PAL" 1 "NTSC" ;
VAL_ 2158034944 CurntTVStnServc 0 "No Data" 1 "General Subscription" 2 "Pay per use" 3 "Promotion" 4 "Unsubscribed" 5 "Other" ;
VAL_ 2158034944 CurntTVStnQual 0 "Insufficient Signal" 1 "Sufficient Signal" ;
VAL_ 2158034944 VidSrcType 3 "Auxiliary Device" 2 "Rear Camera" 1 "Television" ;
VAL_ 2158034944 VidSrcStatCode 4 "Producing Blank" 3 "Producing Video" 2 "Video Not Available" 1 "Video Available" 0 "Device Present" ;
VAL_ 2158034944 TVTunerPres 1 "true" 0 "false" ;
VAL_ 2158034944 RmtRcvrTunStat 1 "Tuning" 0 "Tuned" ;
VAL_ 2158034944 RemRcvrSrcInpStat 3 "Auxiliary Jack 2" 2 "Auxiliary Jack 1" 1 "Television" 0 "No Action" ;
VAL_ 2158034944 RmtRecvtDataTyp 7 "Unknown" 3 "Video" 2 "Data" 1 "Audio" 0 "No Update" ;
VAL_ 2158034944 RmtRcvrCmndStat 3 "Out of Range" 2 "Not Supported" 1 "Valid Command" 0 "No Update" ;
VAL_ 2154627072 LgclAVChnl_368 0 "None" 1 "Unused and Reserved 1" 2 "Unused and Reserved 2" 3 "Asynchronous Message" 4 "Incoming Call" 5 "Phone" 6 "Synchronous Message" 7 "Speech Recognition" 8 "Emergency Phone Call" 9 "Short Mix Alert Message" 10 "Unused and Reserved 3" 11 "Unused and Reserved 4" 12 "Onstar Initiated Call" ;
VAL_ 2154627072 AudMstrSrcTyp 28 "Phone" 24 "Sat. Digital Audio Receiver System" 20 "Digital Audio Broadcast" 16 "Remote CD Changer" 12 "Remote Digital Video Disk" 8 "Auxiliary Device" 1 "Television Tuner" 0 "Audio Supervisor" ;
VAL_ 2154627072 AudMstrChnnlTyp 3 "Mixed" 2 "Stereo" 1 "Mono" 0 "No Channel" ;
VAL_ 2154627072 AudMstrArbCom 4 "Connection Complete" 3 "Disconnect" 2 "Connect" 1 "Do Not Connect" 0 "No Action" ;
VAL_ 2154692608 LgclAVChnl 0 "None" 1 "Unused and Reserved 1" 2 "Unused and Reserved 2" 3 "Asynchronous Message" 4 "Incoming Call" 5 "Phone" 6 "Synchronous Message" 7 "Speech Recognition" 8 "Emergency Phone Call" 9 "Short Mix Alert Message" 10 "Unused and Reserved 3" 11 "Unused and Reserved 4" 12 "Onstar Initiated Call" ;
VAL_ 2154692608 ASSAudSrcStatCode 5 "Producing Audio" 4 "Producing Silence" 3 "Reserved" 2 "Audio Not Available" 1 "Audio Available" 0 "Device Present" ;
VAL_ 2154692608 ASSAudSrcChType 4 "Mono Emergency" 3 "Mixed" 2 "Stereo" 1 "Mono" 0 "No Action" ;
VAL_ 2154692608 ASSAudSrcType 28 "Phone" 24 "Sat. Digital Audio Receiver System" 20 "Digital Audio Broadcast" 16 "Remote CD Changer" 12 "Remote Digital Video Disk" 8 "Auxiliary Device" 1 "Television Tuner" ;
VAL_ 2153775104 DTCI_DTCFaultType 3 "Type C" 2 "Type B" 1 "Type A" 0 "Not Supported" ;
VAL_ 2153775104 DTCI_CodeSupported 1 "true" 0 "false" ;
VAL_ 2153775104 DTCI_CurrentStatus 1 "true" 0 "false" ;
VAL_ 2153775104 DTCI_TstNPsdCdClrdSt 1 "true" 0 "false" ;
VAL_ 2153775104 DTCI_TstFldCdClrdStat 1 "true" 0 "false" ;
VAL_ 2153775104 DTCI_HistStat 1 "true" 0 "false" ;
VAL_ 2153775104 DTCI_TstNPsdPwrUpSt 1 "true" 0 "false" ;
VAL_ 2153775104 DTCI_TstFldPwrUpSt 1 "true" 0 "false" ;
VAL_ 2153775104 DTCI_WrnIndRqdSt 1 "true" 0 "false" ;
VAL_ 2153775104 DTCI_DTCTriggered 1 "true" 0 "false" ;
VAL_ 2153775104 DTCIUnused7 1 "true" 0 "false" ;
VAL_ 2153775104 DTCIUnused6 1 "true" 0 "false" ;
VAL_ 2153775104 DTCIUnused5 1 "true" 0 "false" ;
VAL_ 2153775104 DTCIUnused4 1 "true" 0 "false" ;
VAL_ 2153775104 DTCIUnused3 1 "true" 0 "false" ;
VAL_ 2153775104 DTCIUnused2 1 "true" 0 "false" ;
VAL_ 2153775104 DTCIUnused1 1 "true" 0 "false" ;
VAL_ 2150703104 AudSysVNoisCompPres 1 "true" 0 "false" ;
VAL_ 2150703104 AudSysSurSndSysPres 1 "true" 0 "false" ;
VAL_ 2150703104 AudSysDigSigProcPres 1 "true" 0 "false" ;
VAL_ 2151718912 ChmVolSt 0 "Normal" 1 "Loud" ;
VAL_ 2151718912 ChmAct 1 "true" 0 "false" ;
VAL_ 2155020288 ChVolRq2 0 "Normal" 1 "Loud" ;
VAL_ 2155020288 LngSelExt 41 "ZA English" 40 "AU English" 39 "Macedonian" 38 "Latvian" 37 "Estonian" 36 "Lithuanian" 35 "Serbian" 34 "Uzbek" 33 "Cantonese" 32 "NA Spanish" 31 "NA French" 30 "Ukrainian" 29 "Croatian" 28 "Slovenian" 27 "Romanian" 26 "Bulgarian" 25 "Thai" 24 "Brazilian Portuguese" 23 "Russian" 22 "Slovak" 21 "Czech" 20 "Hungarian" 19 "UK English" 18 "Traditional Chinese" 17 "Korean" 16 "Turkish" 15 "Polish" 14 "Standard Chinese" 13 "Arabic" 12 "Japanese" 11 "Greek" 10 "Danish" 9 "Finnish" 8 "Norwegian" 7 "Portuguese" 6 "Dutch" 5 "Spanish" 4 "French" 3 "Swedish" 2 "Italian" 1 "German" 0 "NA English" ;
VAL_ 2151677952 SndLocRtRr 1 "true" 0 "false" ;
VAL_ 2151677952 SndLocLftRr 1 "true" 0 "false" ;
VAL_ 2151677952 SndLocPasFr 1 "true" 0 "false" ;
VAL_ 2151677952 SndLocDrFr 1 "true" 0 "false" ;
VAL_ 2151677952 SC_SndTne 10 "Beep (750 Hz) Radio Source Muted" 9 "High Frequency Broadband" 8 "Harp" 7 "Gong (2000 Hz)" 6 "Gong (750 Hz)" 5 "Beep (2000 Hz)" 4 "Beep (750 Hz)" 3 "Click-Clack" 2 "Click" 1 "Clack" 0 "Clock" 14 "No Chime with Radio Source Muted" 13 "Gong (2000 Hz) Radio Source Muted" 12 "Gong (750 Hz) Radio Source Muted" 11 "Beep (2000 Hz) Radio Source Muted" ;
VAL_ 2149851136 KylsStrtAuthRq 1 "true" 0 "false" ;
VAL_ 2149851136 SysPwrMd 3 "Crank Request" 2 "Run" 1 "Accessory" 0 "Off" ;
VAL_ 2149851136 SysPwrMdV 1 "Invalid" 0 "Valid" ;
VAL_ 2149859328 SysBkUpPwrMdV 1 "Invalid" 0 "Valid" ;
VAL_ 2149859328 SysBkupPwrMdEn 1 "true" 0 "false" ;
VAL_ 2149859328 SysBkUpPwrMd 3 "Crank Request" 2 "Run" 1 "Accessory" 0 "Off" ;
VAL_ 2155167744 ClsEngCmprtmtToStrtVehIO 1 "true" 0 "false" ;
VAL_ 2155167744 PrsCltchPrsStrtAgnIO 1 "true" 0 "false" ;
VAL_ 2155167744 PrsStrtAgnIO 1 "true" 0 "false" ;
VAL_ 2155167744 AutoShtdwnDsblIO 1 "true" 0 "false" ;
VAL_ 2155167744 ShftToNtrlIO 1 "true" 0 "false" ;
VAL_ 2155167744 AppPrkBrkIO 1 "true" 0 "false" ;
VAL_ 2155167744 NRmtDtctdRstrtAllwd 1 "true" 0 "false" ;
VAL_ 2155167744 NRmtDtdPsCluRstIO 1 "true" 0 "false" ;
VAL_ 2155167744 SecPwrMdPshBtnAtv 1 "true" 0 "false" ;
VAL_ 2155167744 TSLgMdPwrCtOWAtv 1 "true" 0 "false" ;
VAL_ 2155167744 PrsBtnAgnTTrnEngOffIO 1 "true" 0 "false" ;
VAL_ 2155167744 NRmtDtdPsBrkRstIO 1 "true" 0 "false" ;
VAL_ 2155167744 NoReDetInOn 1 "true" 0 "false" ;
VAL_ 2155167744 ApplyCltPdlIO 1 "true" 0 "false" ;
VAL_ 2155167744 VehMovState 4 "Invalid" 3 "Reverse" 2 "Forward" 1 "Neutral" 0 "Parked" ;
VAL_ 2155167744 TrStLgMdAtv 1 "true" 0 "false" ;
VAL_ 2155167744 TransModInactIO 1 "true" 0 "false" ;
VAL_ 2155167744 TransModActIO 1 "true" 0 "false" ;
VAL_ 2155167744 ApplyBrkPdlIO 1 "true" 0 "false" ;
VAL_ 2155167744 Ky_IdDevPr 1 "true" 0 "false" ;
VAL_ 2155167744 KylsStrtUseTxPckIO 1 "true" 0 "false" ;
VAL_ 2155167744 ShftPrkIO 1 "true" 0 "false" ;
VAL_ 2152611840 OBTCReqstrStat 3 "Off Board Tester Present" 2 "Active" 1 "Inactive" 0 "Unknown" ;
VAL_ 2152611840 OBTCR_Actv 1 "true" 0 "false" ;
VAL_ 2151292928 TrfRdsdInfCsStAvail 1 "true" 0 "false" ;
VAL_ 2151292928 TrfRdsdInfCsCrStVal 7 "Reserved5" 6 "Reserved4" 5 "Reserved3" 4 "Reserved2" 3 "Reserved1" 2 "On" 1 "Off" 0 "No Action" ;
VAL_ 2151292928 TRICA_Resrv5Avail 1 "true" 0 "false" ;
VAL_ 2151292928 TRICA_Resrv4Avail 1 "true" 0 "false" ;
VAL_ 2151292928 TRICA_Resrv3Avail 1 "true" 0 "false" ;
VAL_ 2151292928 TRICA_Resrv2Avail 1 "true" 0 "false" ;
VAL_ 2151292928 TRICA_Resrv1Avail 1 "true" 0 "false" ;
VAL_ 2151292928 TRICA_OnAvail 1 "true" 0 "false" ;
VAL_ 2151292928 TRICA_OfAvail 1 "true" 0 "false" ;
VAL_ 2151292928 IntrStopAlrtCsSetAvl 1 "true" 0 "false" ;
VAL_ 2151292928 IntrStAlrtCsCrSetVal 7 "Reserved4" 6 "Reserved3" 5 "Reserved2" 4 "Reserved1" 3 "Alert and Brake" 2 "Alert " 1 "Off" 0 "No Action" ;
VAL_ 2151292928 ISACA_Resrv4Avail 1 "true" 0 "false" ;
VAL_ 2151292928 ISACA_Resrv3Avail 1 "true" 0 "false" ;
VAL_ 2151292928 ISACA_Resrv2Avail 1 "true" 0 "false" ;
VAL_ 2151292928 ISACA_Resrv1Avail 1 "true" 0 "false" ;
VAL_ 2151292928 ISACA_AlrtBrkAvail 1 "true" 0 "false" ;
VAL_ 2151292928 ISACA_AlrtAvail 1 "true" 0 "false" ;
VAL_ 2151292928 ISACA_OfAvail 1 "true" 0 "false" ;
VAL_ 2151292928 CntdVehBrkAltCsStAvl 1 "true" 0 "false" ;
VAL_ 2151292928 CntdVehBrAltCsCrStVal 7 "Reserved5" 6 "Reserved4" 5 "Reserved3" 4 "Reserved2" 3 "Reserved1" 2 "On" 1 "Off" 0 "No Action" ;
VAL_ 2151292928 CVBACA_Resrv5Avail 1 "true" 0 "false" ;
VAL_ 2151292928 CVBACA_Resrv4Avail 1 "true" 0 "false" ;
VAL_ 2151292928 CVBACA_Resrv3Avail 1 "true" 0 "false" ;
VAL_ 2151292928 CVBACA_Resrv2Avail 1 "true" 0 "false" ;
VAL_ 2151292928 CVBACA_Resrv1Avail 1 "true" 0 "false" ;
VAL_ 2151292928 CVBACA_OnAvail 1 "true" 0 "false" ;
VAL_ 2151292928 CVBACA_OfAvail 1 "true" 0 "false" ;
VAL_ 2151464960 V2VWrngIndReq 31 "Unused And Reserved 15" 30 "Unused And Reserved 14" 29 "Unused And Reserved 13" 28 "Unused And Reserved 12" 27 "Unused And Reserved 11" 26 "Unused And Reserved 10" 25 "Unused And Reserved 9" 24 "Unused And Reserved 8" 23 "Unused And Reserved 7" 22 "Unused And Reserved 6" 21 "Unused And Reserved 5" 20 "Unused And Reserved 4" 19 "Unused And Reserved 3" 18 "Unused And Reserved 2" 17 "Unused And Reserved 1" 16 "Green Light Optimal Speed Advisory" 15 "Intersection Colision Warning Right" 14 "Intersection Colision Warning Left" 13 "Intersection Stop" 12 "Construction Ends" 11 "Construction Starts" 10 "Slowing Traffic" 9 "Crosswinds" 8 "Slippery Road" 7 "Low Visibility" 6 "Heavy Rain" 5 "Sharp  Curve" 4 "Obstacle" 3 "Emergency Vehicle" 2 "Hard Braking" 1 "Hazard Lights" 0 "No Indication" ;
VAL_ 2151464960 V2VWrngDirctn 7 "North West" 6 "West" 5 "South West" 4 "South" 3 "South East" 2 "East" 1 "North East" 0 "North" ;
VAL_ 2151464960 V2VSrvIndReq 3 "Unused and Reserved2" 2 "Unused and Reserved1" 1 "Service V2V System" 0 "No Indication" ;
VAL_ 2151464960 V2VTLI_TrfLghtMntngDirctn 1 "Horizontal" 0 "Vertical" ;
VAL_ 2151464960 V2VTLI_TrfLghtValDirctn 3 "All direction" 2 "Right" 1 "Left" 0 "Straight" ;
VAL_ 2151464960 V2VTLI_TrfLghtPhsArivl 3 "Unknown Phase" 2 "Yellow" 1 "Green" 0 "Red" ;
VAL_ 2151464960 V2VTLI_TrfLghtActlPhs 3 "Unknown Phase" 2 "Yellow" 1 "Green" 0 "Red" ;
VAL_ 2153930752 LnCntrVhlStpd 1 "true" 0 "false" ;
VAL_ 2153930752 LnCntrSpchPrmtReq 3 "Unused and Reserved" 2 "Take Vehicle Control" 1 "Take Steering" 0 "No Prompt" ;
VAL_ 2153930752 LnCntrNonRspDrvrCnd 1 "true" 0 "false" ;
VAL_ 2153930752 LnCntrEsclnStat 3 "System Faulted" 2 "Limit Condition" 1 "Driver Not Looking to Roadway" 0 "None" ;
VAL_ 2153930752 LCWrnIndReq 25 "Sensor Imparied" 24 "Vehicle Center" 23 "Driver Action" 22 "GPS Unavailable" 21 "Driver Attn Off Road" 20 "Controlled Access" 19 "Adaptive Cruise" 18 "Vehicle Setting" 17 "GM Authority" 16 "Exit Lane" 15 "Lane Ending" 14 "Lane Following Locked Out" 13 "Service Driver Assist System" 12 "Take Vehicle Control" 11 "Take Steering" 10 "Due to Weather" 9 "Attention Unknown" 8 "Unavailable" 7 "Adaptive Cruise Disengaging" 6 "Vehicle Proximity" 5 "Excessive Speed" 4 "Construction" 3 "Freeway Ends" 2 "Tight Curve" 1 "Lane Lines" 0 "No Indication" ;
VAL_ 2153930752 LCCDrvrAwrnsIO 1 "true" 0 "false" ;
VAL_ 2153930752 LCConvMsgIndreq 31 "Reserved" 30 "Reserved" 29 "Reserved" 28 "Reserved" 27 "Reserved" 26 "Reserved" 25 "Reserved" 24 "Reserved" 23 "Reserved" 22 "Reserved" 21 "Reserved" 20 "Reserved" 19 "Show Fuel Range" 18 "Show Fuel Level" 17 "Take Time to Look at Road" 16 "Road Detour Detected" 15 "Lane Ending Ahead" 14 "Exit Only Lane Ahead" 13 "Road Exit Detected Ahead" 12 "Major Road Interchange Ahead" 11 "Slow Moving Traffic in Right Lane" 10 "Slow Moving Traffic Ahead" 9 "Slow Moving Traffic in Left Lane" 8 "Merging Vehicle" 7 "Heavy Traffic" 6 "Right Blind Spot Occupied" 5 "Left Blind Spot Occupied" 4 "Tailgater Detected" 3 "Being Passed on Right" 2 "Being Passed on Left" 1 "Behind Slow Vehicle" 0 "No Indication" ;
VAL_ 2153930752 LCCIndReq 7 "Reserved" 6 "Reserved" 5 "Reserved" 4 "Red Indicator" 3 "Blue Indicator" 2 "Green Indicator" 1 "White Indicator" 0 "Indicator Off" ;
VAL_ 2153889792 LCArrwBlk5Act 1 "true" 0 "false" ;
VAL_ 2153889792 LCArrwBlk4Act 1 "true" 0 "false" ;
VAL_ 2153889792 LCArrwBlk3Act 1 "true" 0 "false" ;
VAL_ 2153889792 LCArrwBlk2Act 1 "true" 0 "false" ;
VAL_ 2153889792 LCArrwBlk1Act 1 "true" 0 "false" ;
VAL_ 2151063552 TrfRdsdInfCsStReq 7 "Reserved5" 6 "Reserved4" 5 "Reserved3" 4 "Reserved2" 3 "Reserved1" 2 "On" 1 "Off" 0 "No Action" ;
VAL_ 2151063552 IntrStopAlrtCsSetReq 7 "Reserved4" 6 "Reserved3" 5 "Reserved2" 4 "Reserved1" 3 "Alert and Brake" 2 "Alert " 1 "Off" 0 "No Action" ;
VAL_ 2151063552 CntdVehBrAltCsStReq 7 "Reserved5" 6 "Reserved4" 5 "Reserved3" 4 "Reserved2" 3 "Reserved1" 2 "On" 1 "Off" 0 "No Action" ;
VAL_ 2151063552 TrgdVidRecSwAct 1 "true" 0 "false" ;
VAL_ 2151063552 ICSTS_TchPrxmty 2 "Touch" 1 "Near" 0 "Far" ;
VAL_ 2151063552 RrPedDetCstStReq 7 "Reserved3" 6 "Reserved2" 5 "Reserved1" 4 "Alert and Brake" 3 "Alert" 2 "On" 1 "Off" 0 "No Action" ;
VAL_ 2151063552 CamVideoICSDispAct 1 "true" 0 "false" ;
VAL_ 2151063552 Frnt360CamSwAct 1 "true" 0 "false" ;
VAL_ 2151063552 InftnOprAlwd 1 "true" 0 "false" ;
VAL_ 2151063552 ValetMdAct 1 "true" 0 "false" ;
VAL_ 2149646336 VehSpdAvgDrvnSrc 1 "Wheel Speed" 0 "Transmission Output Speed" ;
VAL_ 2149646336 VehSpdAvgNDrvnV 1 "Invalid" 0 "Valid" ;
VAL_ 2149646336 DstRolCntAvgNonDrvnV 1 "Invalid" 0 "Valid" ;
VAL_ 2149646336 DstRolCntAvNDrRstOc 1 "true" 0 "false" ;
VAL_ 2149646336 DstRolCntAvgDrnRstOc 1 "true" 0 "false" ;
VAL_ 2149646336 DistRollCntAvgDrvnV 1 "Invalid" 0 "Valid" ;
VAL_ 2149646336 DistRollCntAvgDrvnSrc 1 "Wheel Speed" 0 "Transmission Output Speed" ;
VAL_ 2149646336 VehSpdAvgDrvnV 1 "Invalid" 0 "Valid" ;
VAL_ 2154905600 DrvSeatPrsMemID 0 "Memory #1" 1 "Memory #2" 2 "Memory #3" 3 "Memory #4" 4 "Memory #5" 5 "Memory #6" 6 "Memory #7" 7 "Unknown" ;
VAL_ 2154905600 DrId 7 "Unknown" 6 "Driver #7" 5 "Driver #6" 4 "Driver #5" 3 "Driver #4" 2 "Driver #3" 1 "Driver #2" 0 "Driver #1" ;
VAL_ 2155954176 ClmCntlExtDefActIO 1 "true" 0 "false" ;
VAL_ 2155954176 ClntCircPmpRq 1 "On" 0 "Off" ;
VAL_ 2155954176 ClimCtrlAftBlowModActv 1 "true" 0 "false" ;
VAL_ 2155954176 ACHtIdleBstLevReq 3 "Boost Level 3" 2 "Boost Level 2" 1 "Boost Level 1" 0 "No Boost Requested" ;
VAL_ 2155954176 AirCndActIO 1 "true" 0 "false" ;
VAL_ 2155421696 PsvEntAprchDrctn 0 "Driver" 1 "Co-Driver" 2 "Front" 3 "Rear" ;
VAL_ 2155421696 PsvEntApprchDtcd 1 "true" 0 "false" ;
VAL_ 2155421696 PsvEntApprchCnfgReq 0 "Level 0" 1 "Level 1" 2 "Level 2" 3 "Level 3" 4 "Level 4" 5 "Level 5" 6 "Level 6" 7 "Level 7" ;
VAL_ 2155421696 ServKylsStSysIO 1 "true" 0 "false" ;
VAL_ 2153938944 RmtRflshMdReqtd 1 "true" 0 "false" ;
SIG_GROUP_ 2149826560 FwdObjAlrtInd11E 1 : FOAI_VehAhdIndRq11E FOAI_AlrtWrnIndRq11E FOAI_AlrtChmIhbRq11E;
SIG_GROUP_ 2149711872 FwdObjAlrtInd 1 : FOAI_VehAhdIndRq FOAI_AlrtWrnIndRq FOAI_AlrtChmIhbRq;
SIG_GROUP_ 2158067712 TchScnDsplUsrActnExt 1 : TSDUAE_YCoOdntRq TSDUAE_XCoOdntRq TSDUAE_ScrnPrsdRq TSDUAE_RotEnc TSDUAE_RotBtnPsh TSDUAE_GrphStrkInfRq;
SIG_GROUP_ 2154692608 AudSrcStat 1 : ASSAudSrcStatCode ASSAudSrcChType ASSAudSrcType;
SIG_GROUP_ 2153775104 DTCInfo 1 : DTCI_DTCFaultType DTCI_CodeSupported DTCI_CurrentStatus DTCI_TstNPsdCdClrdSt DTCI_TstFldCdClrdStat DTCI_HistStat DTCI_TstNPsdPwrUpSt DTCI_TstFldPwrUpSt DTCI_WrnIndRqdSt DTCI_DTCFailType DTCI_DTCNumber DTCI_DTCSource DTCI_DTCTriggered DTCIUnused7 DTCIUnused6 DTCIUnused5 DTCIUnused4 DTCIUnused3 DTCIUnused2 DTCIUnused1;
SIG_GROUP_ 2151677952 SndLoc 1 : SndLocRtRr SndLocLftRr SndLocPasFr SndLocDrFr;
SIG_GROUP_ 2151677952 SndChrs 1 : SC_SndDutCyc SC_NmofRp SC_SndCdnPrd SC_SndTne;
SIG_GROUP_ 2152611840 OBTCReq 1 : OBTCR_Prty OBTCR_Actv;
SIG_GROUP_ 2151292928 TrfRdsdInfCsAvail 1 : TRICA_Resrv5Avail TRICA_Resrv4Avail TRICA_Resrv3Avail TRICA_Resrv2Avail TRICA_Resrv1Avail TRICA_OnAvail TRICA_OfAvail;
SIG_GROUP_ 2151292928 IntrStAlrtCsAvail 1 : ISACA_Resrv4Avail ISACA_Resrv3Avail ISACA_Resrv2Avail ISACA_Resrv1Avail ISACA_AlrtBrkAvail ISACA_AlrtAvail ISACA_OfAvail;
SIG_GROUP_ 2151292928 CntdVehBrkAlrtCsAvail 1 : CVBACA_Resrv5Avail CVBACA_Resrv4Avail CVBACA_Resrv3Avail CVBACA_Resrv2Avail CVBACA_Resrv1Avail CVBACA_OnAvail CVBACA_OfAvail;
SIG_GROUP_ 2151464960 V2VSpdRecmndtn 1 : V2VSR_TrfLghtDispLim V2VSR_TrfLghtMaxRecmndSpd V2VSR_TrfLghtMinRecmndSpd;
SIG_GROUP_ 2151464960 V2VTrfLghtInfo 1 : V2VTLI_TrfLghtMntngDirctn V2VTLI_TrfLghtValDirctn V2VTLI_TrfLghtPhsArivl V2VTLI_TrfLghtActlPhs V2VTLI_TrfLghtTmPhsSw;
SIG_GROUP_ 2151063552 ICSTchStat 1 : ICSTS_Y1TchCrdnt ICSTS_X1TchCrdnt ICSTS_TchPrxmty;
